VERSION "Version"

NS_ :

BS_:

BU_: LBMS CCU ZCUR_ZCUT Tester PLGM CCURT2 TMC ZCUF ZCUL ZCUR ZCUT EMS DCDC IPS NIDU DCU2 IDUR OBC OPC LPC CPC GCU DCU IPU BMS EOP DCDC2 SRS ECS SAS CBM RAS EPS RBM IBCS ICM IID IDC RCICP AMP WHUD IMR CD INU ADC IFC FAPA RRR RLR PAS PCS SCMR SCMRL SCMRR SCMRM SCMT MFS DRM IDU FCP RCP LBMSAD AVAS DLPFL FBLCM FLISD FLLCM FRLCM RLLCMA RLLCMB RRLCMA RRLCMB RLISD RRISD DLPML DLPMR PSDL PSDR HVSPRL HVSPRR TBOX2 TBOX EPB RFR SBM WCM ETC EVCC CCURT1 EDL

BO_ 1236 LBMS_DiagCode: 64 LBMS
 SG_ LBMS_DTCCode : 7|512@0+ (1,0) [0|0] ""  CCU

BO_ 998 CCU_VCU_5: 24 CCU
 SG_ VCU_LVBatFillSt_1 : 127|4@0+ (1,0) [0|15] ""  CCURT2,LBMS

BO_ 616 CCU_1: 64 CCU
 SG_ UMM_UsageModeSt : 26|3@0+ (1,0) [0|7] ""  CCURT2,TMC,ZCUF,ZCUL,ZCUR,ZCUT,EMS,DCDC,IPS,NIDU,DCU2,IDUR,OBC,OPC,LPC,CPC,GCU,DCU,IPU,BMS,EOP,DCDC2,SRS,ECS,SAS,CBM,RAS,EPS,RBM,IBCS,ICM,IID,IDC,RCICP,AMP,WHUD,IMR,CD,INU,ADC,IFC,FAPA,RRR,RLR,PAS,PCS,SCMR,SCMRL,SCMRR,SCMRM,SCMT,MFS,DRM,IDU,FCP,RCP,LBMSAD,AVAS,DLPFL,FBLCM,FLISD,FLLCM,FRLCM,RLLCMA,RLLCMB,RRLCMA,RRLCMB,RLISD,RRISD,DLPML,DLPMR,PLGM,PSDL,PSDR,HVSPRL,HVSPRR,LBMS,TBOX2,TBOX
 SG_ VMM_VehModeSt : 159|4@0+ (1,0) [0|15] ""  CCURT2,TMC,ZCUF,ZCUL,ZCUR,ZCUT,EMS,DCDC,IPS,NIDU,DCU2,IDUR,OBC,OPC,LPC,CPC,GCU,DCU,IPU,BMS,EOP,DCDC2,SRS,ECS,SAS,EPS,EPB,RBM,IBCS,ICM,IDC,RCICP,AMP,WHUD,IMR,ADC,IFC,FAPA,RRR,RLR,PAS,SCMR,SCMRL,SCMRR,SCMT,MFS,IDU,FCP,RCP,LBMSAD,AVAS,DLPFL,FBLCM,FLISD,FLLCM,FRLCM,RLLCMA,RLLCMB,RRLCMA,RRLCMB,RLISD,RRISD,DLPML,DLPMR,PLGM,PSDL,PSDR,HVSPRL,HVSPRR,LBMS,RFR,SBM,WCM,ETC,TBOX2,TBOX
 SG_ VMM_OTAModeSt : 167|2@0+ (1,0) [0|3] ""  CCURT2,ZCUF,ZCUL,ZCUR,ZCUT,EMS,DCDC,IPS,NIDU,DCU2,IDUR,OBC,OPC,LPC,CPC,GCU,DCU,IPU,BMS,EOP,DCDC2,SRS,ECS,EPS,EPB,RBM,IBCS,ICM,IDC,RCICP,AMP,WHUD,ADC,IFC,FAPA,RRR,RLR,PAS,SCMR,SCMRL,SCMRR,SCMT,MFS,RCP,LBMSAD,AVAS,DLPFL,FBLCM,FLISD,FLLCM,FRLCM,RLLCMA,RLLCMB,RRLCMA,RRLCMB,RLISD,RRISD,DLPML,DLPMR,PSDL,PSDR,HVSPRL,HVSPRR,LBMS,RFR,SBM,WCM,ETC,TBOX
 SG_ Time_Year : 343|8@0+ (1,2000) [2000|2255] "y"  CCURT2,TMC,ZCUF,ZCUL,ZCUR,ZCUT,EMS,DCDC,IPS,NIDU,DCU2,IDUR,OBC,OPC,LPC,CPC,GCU,DCU,IPU,BMS,EOP,EVCC,DCDC2,SRS,ECS,CBM,EPS,RBM,IBCS,RCICP,AMP,WHUD,IMR,INU,ADC,IFC,FAPA,RRR,RLR,PAS,PCS,SCMR,SCMRL,SCMRR,SCMT,MFS,DRM,RCP,LBMSAD,DLPFL,FBLCM,FLISD,FLLCM,FRLCM,RLLCMA,RLLCMB,RRLCMA,RRLCMB,RLISD,RRISD,DLPML,DLPMR,PLGM,PSDL,PSDR,HVSPRL,HVSPRR,LBMS
 SG_ Time_Month : 351|4@0+ (1,0) [1|12] "m"  CCURT2,TMC,ZCUF,ZCUL,ZCUR,ZCUT,EMS,DCDC,IPS,NIDU,DCU2,IDUR,OBC,OPC,LPC,CPC,GCU,DCU,IPU,BMS,EOP,EVCC,DCDC2,SRS,ECS,CBM,EPS,RBM,IBCS,RCICP,AMP,WHUD,IMR,INU,ADC,IFC,FAPA,RRR,RLR,PAS,PCS,SCMR,SCMRL,SCMRR,SCMT,MFS,DRM,RCP,LBMSAD,DLPFL,FBLCM,FLISD,FLLCM,FRLCM,RLLCMA,RLLCMB,RRLCMA,RRLCMB,RLISD,RRISD,DLPML,DLPMR,PLGM,PSDL,PSDR,HVSPRL,HVSPRR,LBMS
 SG_ Time_Day : 347|5@0+ (1,0) [1|31] "d"  CCURT2,TMC,ZCUF,ZCUL,ZCUR,ZCUT,EMS,DCDC,IPS,NIDU,DCU2,IDUR,OBC,OPC,LPC,CPC,GCU,DCU,IPU,BMS,EOP,EVCC,DCDC2,SRS,ECS,CBM,EPS,RBM,IBCS,RCICP,AMP,WHUD,IMR,INU,ADC,IFC,FAPA,RRR,RLR,PAS,PCS,SCMR,SCMRL,SCMRR,SCMT,MFS,DRM,RCP,LBMSAD,DLPFL,FBLCM,FLISD,FLLCM,FRLCM,RLLCMA,RLLCMB,RRLCMA,RRLCMB,RLISD,RRISD,DLPML,DLPMR,PLGM,PSDL,PSDR,HVSPRL,HVSPRR,LBMS
 SG_ Time_Hour : 358|5@0+ (1,0) [0|23] "h"  CCURT2,TMC,ZCUF,ZCUL,ZCUR,ZCUT,EMS,DCDC,IPS,NIDU,DCU2,IDUR,OBC,OPC,LPC,CPC,GCU,DCU,IPU,BMS,EOP,EVCC,DCDC2,SRS,ECS,CBM,EPS,RBM,IBCS,RCICP,AMP,WHUD,IMR,INU,ADC,IFC,FAPA,RRR,RLR,PAS,PCS,SCMR,SCMRL,SCMRR,SCMT,MFS,DRM,RCP,LBMSAD,DLPFL,FBLCM,FLISD,FLLCM,FRLCM,RLLCMA,RLLCMB,RRLCMA,RRLCMB,RLISD,RRISD,DLPML,DLPMR,PLGM,PSDL,PSDR,HVSPRL,HVSPRR,LBMS
 SG_ Time_Min : 353|6@0+ (1,0) [0|59] "min"  CCURT2,TMC,ZCUF,ZCUL,ZCUR,ZCUT,EMS,DCDC,IPS,NIDU,DCU2,IDUR,OBC,OPC,LPC,CPC,GCU,DCU,IPU,BMS,EOP,EVCC,DCDC2,SRS,ECS,CBM,EPS,RBM,IBCS,RCICP,AMP,WHUD,IMR,INU,ADC,IFC,FAPA,RRR,RLR,PAS,PCS,SCMR,SCMRL,SCMRR,SCMT,MFS,DRM,RCP,LBMSAD,DLPFL,FBLCM,FLISD,FLLCM,FRLCM,RLLCMA,RLLCMB,RRLCMA,RRLCMB,RLISD,RRISD,DLPML,DLPMR,PLGM,PSDL,PSDR,HVSPRL,HVSPRR,LBMS
 SG_ Time_Sec : 363|6@0+ (1,0) [0|59] "s"  CCURT2,TMC,ZCUF,ZCUL,ZCUR,ZCUT,EMS,DCDC,IPS,NIDU,DCU2,IDUR,OBC,OPC,LPC,CPC,GCU,DCU,IPU,BMS,EOP,EVCC,DCDC2,SRS,ECS,CBM,EPS,RBM,IBCS,RCICP,AMP,WHUD,IMR,INU,ADC,IFC,FAPA,RRR,RLR,PAS,PCS,SCMR,SCMRL,SCMRR,SCMT,MFS,DRM,RCP,LBMSAD,DLPFL,FBLCM,FLISD,FLLCM,FRLCM,RLLCMA,RLLCMB,RRLCMA,RRLCMB,RLISD,RRISD,DLPML,DLPMR,PLGM,PSDL,PSDR,HVSPRL,HVSPRR,LBMS

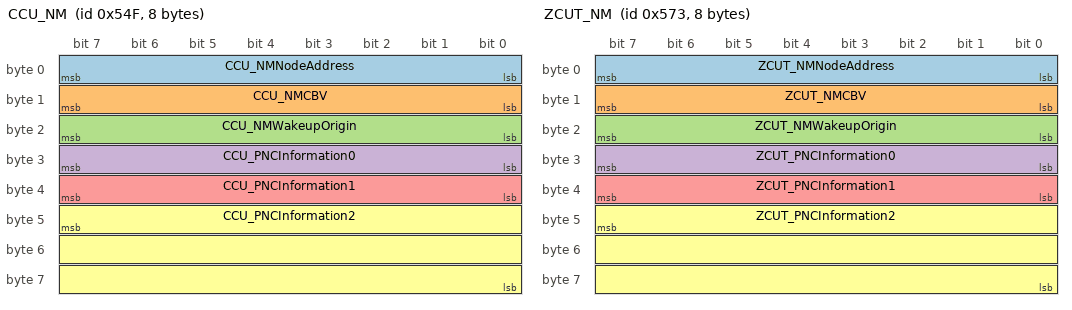
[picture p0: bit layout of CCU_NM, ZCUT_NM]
BO_ 1359 CCU_NM: 8 CCU
 SG_ CCU_NMNodeAddress : 7|8@0+ (1,0) [0|255] ""  CCURT1,TMC,ZCUF,ZCUL,ZCUR,ZCUT,EMS,IPS,NIDU,BMS,EVCC,ECS,CBM,RBM,IBCS,ICM,IID,IDC,AMP,ADC,FAPA,SCMR,SCMRL,SCMRR,SCMRM,SCMT,MFS,LBMSAD,PLGM,PSDL,PSDR,LBMS,TBOX
 SG_ CCU_NMCBV : 15|8@0+ (1,0) [0|0] ""  CCURT1,TMC,ZCUF,ZCUL,ZCUR,ZCUT,EMS,IPS,NIDU,BMS,EVCC,ECS,CBM,RBM,IBCS,ICM,IID,IDC,AMP,ADC,FAPA,SCMR,SCMRL,SCMRR,SCMRM,SCMT,MFS,LBMSAD,PLGM,PSDL,PSDR,LBMS,TBOX
 SG_ CCU_NMWakeupOrigin : 23|8@0+ (1,0) [0|255] ""  CCURT1,TMC,ZCUF,ZCUL,ZCUR,ZCUT,EMS,IPS,NIDU,BMS,EVCC,ECS,CBM,RBM,IBCS,ICM,IID,IDC,AMP,ADC,FAPA,SCMR,SCMRL,SCMRR,SCMRM,SCMT,MFS,LBMSAD,PLGM,PSDL,PSDR,LBMS,TBOX
 SG_ CCU_PNCInformation0 : 31|8@0+ (1,0) [0|255] ""  CCURT1,TMC,ZCUF,ZCUL,ZCUR,ZCUT,EMS,IPS,NIDU,BMS,EVCC,ECS,CBM,RBM,IBCS,ICM,IID,IDC,AMP,ADC,FAPA,SCMR,SCMRL,SCMRR,SCMRM,SCMT,MFS,LBMSAD,PLGM,PSDL,PSDR,LBMS,TBOX
 SG_ CCU_PNCInformation1 : 39|8@0+ (1,0) [0|255] ""  CCURT1,TMC,ZCUF,ZCUL,ZCUR,ZCUT,EMS,IPS,NIDU,BMS,EVCC,ECS,CBM,RBM,IBCS,ICM,IID,IDC,AMP,ADC,FAPA,SCMR,SCMRL,SCMRR,SCMRM,SCMT,MFS,LBMSAD,PLGM,PSDL,PSDR,LBMS,TBOX
 SG_ CCU_PNCInformation2 : 47|24@0+ (1,0) [0|0] ""  CCURT1,TMC,ZCUF,ZCUL,ZCUR,ZCUT,EMS,IPS,NIDU,BMS,EVCC,ECS,CBM,RBM,IBCS,ICM,IID,IDC,AMP,ADC,FAPA,SCMR,SCMRL,SCMRR,SCMRM,SCMT,MFS,LBMSAD,PLGM,PSDL,PSDR,LBMS,TBOX

BO_ 352 CCU_BCS_2_C: 64 CCU
 SG_ BCS_VehSpd : 31|13@0+ (0.05625,0) [0|240] "km/h"  TMC,ZCUF,ZCUL,ZCUR,ZCUT,EMS,DCDC,IPS,NIDU,DCU2,IDUR,OBC,OPC,LPC,CPC,GCU,DCU,IPU,BMS,EVCC,DCDC2,EDL,ICM,IID,IDC,AMP,IMR,INU,ADC,IFC,FAPA,RRR,RLR,PAS,PCS,SCMR,SCMRL,SCMRR,SCMRM,SCMT,MFS,DRM,IDU,RCP,LBMSAD,AVAS,DLPFL,FBLCM,FLISD,FLLCM,FRLCM,RLLCMA,RLLCMB,RRLCMA,RRLCMB,RLISD,RRISD,DLPML,DLPMR,PLGM,PSDL,PSDR,HVSPRL,HVSPRR,LBMS,TBOX2,TBOX
 SG_ BCS_VehSpdVD : 34|1@0+ (1,0) [0|1] ""  TMC,ZCUF,ZCUL,ZCUR,ZCUT,EMS,DCDC,IPS,NIDU,DCU2,IDUR,OBC,OPC,LPC,CPC,GCU,DCU,IPU,BMS,EVCC,DCDC2,ICM,IID,IDC,AMP,IMR,INU,ADC,IFC,FAPA,RRR,RLR,PAS,SCMR,SCMRL,SCMRR,SCMRM,SCMT,MFS,DRM,IDU,RCP,LBMSAD,AVAS,DLPFL,FBLCM,FLISD,FLLCM,FRLCM,RLLCMA,RLLCMB,RRLCMA,RRLCMB,RLISD,RRISD,DLPML,DLPMR,PLGM,PSDL,PSDR,HVSPRL,HVSPRR,LBMS,TBOX

BO_ 884 CCU_GwMsg_3: 64 CCU
 SG_ CCU_GwMsg_3_CRC : 7|16@0+ (1,0) [0|65535] ""  CBM,LBMS
 SG_ CCU_GwMsg_3_Counter : 23|8@0+ (1,0) [0|255] ""  CBM,LBMS
 SG_ LCK_FrontLeftDoorHandlePosition : 31|8@0+ (1,0) [0|255] ""  CBM,LBMS
 SG_ LCK_FrontLeftDoorLockAction : 41|2@0+ (1,0) [0|2] ""  CBM,LBMS
 SG_ LCK_FrontLeftDoorHandleAction : 43|2@0+ (1,0) [0|2] ""  CBM,LBMS
 SG_ LCK_FrontLeftPowerDoorAction : 45|2@0+ (1,0) [0|2] ""  CBM,LBMS
 SG_ LCK_FrontRightDoorHandlePosition : 39|8@0+ (1,0) [0|255] ""  CBM,LBMS
 SG_ LCK_FrontRightDoorLockAction : 47|2@0+ (1,0) [0|2] ""  CBM,LBMS
 SG_ LCK_FrontRightDoorHandleAction : 53|2@0+ (1,0) [0|2] ""  CBM,LBMS
 SG_ LCK_FrontRightPowerDoorAction : 55|2@0+ (1,0) [0|2] ""  CBM,LBMS
 SG_ IPDS_BAT1PowerSt : 48|1@0+ (1,0) [0|1] ""  LBMSAD,LBMS
 SG_ IPDS_BAT2PowerSt : 49|1@0+ (1,0) [0|1] ""  LBMSAD,LBMS
 SG_ IPDS_DCDC2PowerSt : 50|1@0+ (1,0) [0|1] ""  LBMSAD,LBMS
 SG_ IPDS_GridIsoPowerSt : 51|1@0+ (1,0) [0|1] ""  LBMSAD,LBMS
 SG_ IPS_DCDCDiagErrCode : 63|8@0+ (1,0) [0|255] ""  LBMSAD,LBMS
 SG_ IPS_DCDCCurrLvAct : 71|9@0+ (1,0) [0|511] "A"  LBMSAD,LBMS

BO_ 514 CCU_GwMsg_2: 16 CCU
 SG_ CCU_GwMsg_2_CRC : 7|16@0+ (1,0) [0|65535] ""  ZCUR,ZCUT,LBMSAD,LBMS
 SG_ CCU_GwMsg_2_Counter : 23|8@0+ (1,0) [0|255] ""  ZCUR,ZCUT,LBMSAD,LBMS
 SG_ SRS_CrashOutputSt : 29|8@0+ (1,0) [0|160] ""  LBMSAD,LBMS
 SG_ BMS_HVBattSt : 109|4@0+ (1,0) [0|15] ""  LBMSAD,LBMS

BO_ 909 CCU_ZCU_1: 64 CCU
 SG_ LCK_FrontLeftDoorLockSt : 47|1@0+ (1,0) [0|1] ""  ZCUR,CBM,ICM,IDC,ADC,IFC,FAPA,RRR,RLR,LBMS
 SG_ LCK_FrontRightDoorLockSt : 46|1@0+ (1,0) [0|1] ""  CBM,ICM,IDC,ADC,IFC,FAPA,RRR,RLR,LBMS
 SG_ LCK_RearLeftDoorLockSt : 45|1@0+ (1,0) [0|1] ""  ZCUL,ZCUR,ECS,CBM,ICM,IDC,ADC,IFC,FAPA,RRR,RLR,LBMS
 SG_ LCK_RearRightDoorLockSt : 44|1@0+ (1,0) [0|1] ""  ZCUL,ZCUR,ECS,CBM,ICM,IDC,ADC,IFC,FAPA,RRR,RLR,LBMS
 SG_ LCK_RearLeftChildSaftyLockSt : 43|1@0+ (1,0) [0|1] ""  ZCUL,ZCUR,CBM,ICM,IDC,ADC,IFC,FAPA,RRR,RLR,LBMS
 SG_ LCK_RearRightChildSaftyLockSt : 42|1@0+ (1,0) [0|1] ""  ZCUL,ZCUR,CBM,ICM,IDC,ADC,IFC,FAPA,RRR,RLR,LBMS
 SG_ IPS_DCDCVoltLvAct : 301|10@0+ (0.1,0) [0|102.3] "V"  LBMSAD,LBMS
 SG_ BMS_ThermalRunawayErr : 208|1@0+ (1,0) [0|1] ""  LBMSAD,LBMS
 SG_ IPS_DCDCModeSt : 449|3@0+ (1,0) [0|7] ""  ZCUR,ECS,IDU,LBMSAD,LBMS

BO_ 792 CCU_ZCUT_2: 64 CCU
 SG_ ZCUT_2_CRC : 7|16@0+ (1,0) [0|65535] ""  LBMS
 SG_ ZCUT_2_Counter : 23|8@0+ (1,0) [0|255] ""  LBMS
 SG_ LCK_RearLeftDoorLockAction : 141|2@0+ (1,0) [0|2] ""  LBMS
 SG_ LCK_RearLeftDoorHandleAction : 139|2@0+ (1,0) [0|2] ""  LBMS
 SG_ LCK_RearLeftPowerDoorAction : 137|2@0+ (1,0) [0|2] ""  LBMS
 SG_ LCK_RearLeftDoorHandlePosition : 151|8@0+ (1,0) [0|255] ""  LBMS
 SG_ LCK_RearLeftChildSaftyLockAction : 158|2@0+ (1,0) [0|2] ""  LBMS
 SG_ LCK_RearRightDoorHandlePosition : 167|8@0+ (1,0) [0|255] ""  LBMS
 SG_ LCK_RearRightDoorHandleAction : 175|2@0+ (1,0) [0|2] ""  LBMS
 SG_ LCK_RearRightPowerDoorAction : 173|2@0+ (1,0) [0|2] ""  LBMS
 SG_ LCK_RearRightChildSaftyLockAction : 171|2@0+ (1,0) [0|2] ""  LBMS
 SG_ LCK_RearRightDoorLockAction : 203|2@0+ (1,0) [0|3] ""  LBMS

BO_ 1395 ZCUT_NM: 8 ZCUR_ZCUT
 SG_ ZCUT_NMNodeAddress : 7|8@0+ (1,0) [0|255] ""  CCU,SCMR,SCMRL,SCMRR,SCMRM,SCMT,PLGM,LBMS
 SG_ ZCUT_NMCBV : 15|8@0+ (1,0) [0|0] ""  CCU,SCMR,SCMRL,SCMRR,SCMRM,SCMT,PLGM,LBMS
 SG_ ZCUT_NMWakeupOrigin : 23|8@0+ (1,0) [0|255] ""  CCU,SCMR,SCMRL,SCMRR,SCMRM,SCMT,PLGM,LBMS
 SG_ ZCUT_PNCInformation0 : 31|8@0+ (1,0) [0|255] ""  CCU,SCMR,SCMRL,SCMRR,SCMRM,SCMT,PLGM,LBMS
 SG_ ZCUT_PNCInformation1 : 39|8@0+ (1,0) [0|255] ""  CCU,SCMR,SCMRL,SCMRR,SCMRM,SCMT,PLGM,LBMS
 SG_ ZCUT_PNCInformation2 : 47|24@0+ (1,0) [0|0] ""  CCU,SCMR,SCMRL,SCMRR,SCMRM,SCMT,PLGM,LBMS

BO_ 1697 LBMS_Diag_Rx: 64 Tester
 SG_ LBMS_Diag_Request : 7|512@0+ (1,0) [0|0] ""  LBMS

BO_ 1705 LBMS_Diag_Tx: 64 LBMS
 SG_ LBMS_Diag_Response : 7|512@0+ (1,0) [0|0] ""  Tester

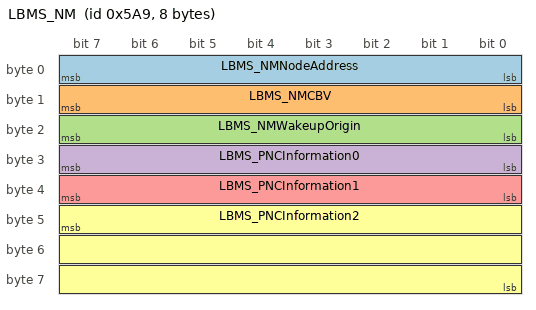
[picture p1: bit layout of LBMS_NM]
BO_ 1449 LBMS_NM: 8 LBMS
 SG_ LBMS_NMNodeAddress : 7|8@0+ (1,0) [0|255] ""  CCU,ZCUT,PLGM
 SG_ LBMS_NMCBV : 15|8@0+ (1,0) [0|0] ""  CCU,ZCUT,PLGM
 SG_ LBMS_NMWakeupOrigin : 23|8@0+ (1,0) [0|255] ""  CCU,ZCUT,PLGM
 SG_ LBMS_PNCInformation0 : 31|8@0+ (1,0) [0|255] ""  CCU,ZCUT,PLGM
 SG_ LBMS_PNCInformation1 : 39|8@0+ (1,0) [0|255] ""  CCU,ZCUT,PLGM
 SG_ LBMS_PNCInformation2 : 47|24@0+ (1,0) [0|0] ""  CCU,ZCUT,PLGM

BO_ 793 LBMS_1: 64 LBMS
 SG_ LBMS_1_CRC : 7|16@0+ (1,0) [0|65535] ""  CCU,CCURT1,CCURT2
 SG_ LBMS_1_Counter : 23|8@0+ (1,0) [0|255] ""  CCU,CCURT1,CCURT2
 SG_ LBMS_UnsfLoadPackVoltVD : 110|1@0+ (1,0) [0|1] ""  CCU,CCURT1,CCURT2
 SG_ LBMS_UnsfLoadPackVolt : 73|11@0+ (0.01,0) [0|20.47] "V"  CCU,CCURT1,CCURT2
 SG_ LBMS_SfLoadPackVoltVD : 111|1@0+ (1,0) [0|1] ""  CCU,CCURT1,CCURT2
 SG_ LBMS_SfLoadPackVolt : 94|11@0+ (0.01,0) [0|20.47] "V"  CCU,CCURT1,CCURT2
 SG_ LBMS_UnsfLoadCurrentRange : 97|2@0+ (1,0) [0|3] ""  CCU,CCURT1,CCURT2
 SG_ LBMS_SfLoadCurrentRange : 99|2@0+ (1,0) [0|3] ""  CCU,CCURT1,CCURT2
 SG_ LBMS_SOFVD : 28|1@0+ (1,0) [0|1] ""  CCU,CCURT1,CCURT2
 SG_ LBMS_SOFEN : 30|2@0+ (1,0) [0|3] ""  CCU,CCURT1,CCURT2
 SG_ LBMS_SOFInhibitSt : 47|8@0+ (1,0) [0|255] ""  CCU,CCURT1,CCURT2
 SG_ LBMS_ChargReq : 26|3@0+ (1,0) [0|7] ""  CCU,CCURT1,CCURT2
 SG_ LBMS_SOCVD : 27|1@0+ (1,0) [0|1] ""  CCU,CCURT1,CCURT2
 SG_ LBMS_SOC : 39|8@0+ (1,0) [0|100] "%"  CCU,CCURT1,CCURT2
 SG_ LBMS_PackVoltVD : 31|1@0+ (1,0) [0|1] ""  CCU,CCURT1,CCURT2
 SG_ LBMS_PackVolt : 55|11@0+ (0.01,0) [0|20.47] "V"  CCU,CCURT1,CCURT2
 SG_ LBMS_AlrmDispSt : 60|3@0+ (1,0) [0|7] ""  CCU,CCURT1,CCURT2
 SG_ LBMS_CurrentRange : 57|2@0+ (1,0) [0|3] ""  CCU,CCURT1,CCURT2
 SG_ LBMS_RefChargReq : 75|2@0+ (1,0) [0|3] ""  CCU,CCURT1,CCURT2
 SG_ LBMS_ThermalRunawayErr : 77|2@0+ (1,0) [0|3] ""  CCU,CCURT1,CCURT2
 SG_ LBMS_ChrgVoltReq : 71|10@0+ (0.01,9) [9|19.23] "V"  CCU,CCURT1,CCURT2
 SG_ LBMS_IPDS_BAT1PowerReq : 107|1@0+ (1,0) [0|1] ""  CCU,CCURT1,CCURT2
 SG_ LBMS_IPDS_BAT2PowerReq : 108|1@0+ (1,0) [0|1] ""  CCU,CCURT1,CCURT2
 SG_ LBMS_IPDS_GridlsoPowerReq : 109|1@0+ (1,0) [0|1] ""  CCU,CCURT1,CCURT2
 SG_ LBMS_FaultSt_SOCLow : 106|2@0+ (1,0) [0|3] ""  CCU,CCURT1,CCURT2
 SG_ LBMS_FaultNum : 119|8@0+ (1,0) [0|255] ""  CCU,CCURT1,CCURT2
 SG_ LBMS_FaultCode : 127|8@0+ (1,0) [0|255] ""  CCU,CCURT1,CCURT2
 SG_ LBMS_DisconnectSt : 191|3@0+ (1,0) [0|7] ""  CCU,CCURT1,CCURT2

BO_ 973 LBMS_2: 64 LBMS
 SG_ LBMS_SOH : 7|8@0+ (1,0) [0|255] ""  CCU,CCURT1,CCURT2
 SG_ LBMS_SOHVD : 25|1@0+ (1,0) [0|1] ""  CCU,CCURT1,CCURT2
 SG_ LBMS_Current : 15|22@0+ (0.001,-1500) [-1500|2694.303] "A"  CCU,CCURT1,CCURT2
 SG_ LBMS_ChrgCurrentReq : 39|12@0+ (0.1,0) [0|409.5] "A"  CCU,CCURT1,CCURT2
 SG_ LBMS_CellTotVolt : 43|11@0+ (0.01,0) [0|20.47] "V"  CCU,CCURT1,CCURT2
 SG_ LBMS_CellTotVoltVD : 24|1@0+ (1,0) [0|1] ""  CCU,CCURT1,CCURT2
 SG_ LBMS_ChargReqEn : 48|1@0+ (1,0) [0|1] ""  CCU,CCURT1,CCURT2
 SG_ LBMS_WorkSt : 63|4@0+ (1,0) [0|15] ""  CCU,CCURT1,CCURT2
 SG_ LBMS_MOSSt : 71|3@0+ (1,0) [0|7] ""  CCU,CCURT1,CCURT2
 SG_ LBMS_WakeupSource : 59|4@0+ (1,0) [0|15] ""  CCU,CCURT1,CCURT2
 SG_ LBMS_HardWireSt : 68|2@0+ (1,0) [0|3] ""  CCU,CCURT1,CCURT2
 SG_ LBMS_QC : 471|14@0+ (1,-16000) [-16000|383] "mA"  CCU,CCURT1,CCURT2
 SG_ LBMS_WireHarnConSt : 84|3@0+ (1,0) [0|7] ""  CCU,CCURT1,CCURT2
 SG_ LBMS_SOCCaliMode : 66|3@0+ (1,0) [0|7] ""  CCU,CCURT1,CCURT2
 SG_ LBMS_ChrgCurrentLimt1 : 95|12@0+ (0.1,0) [0|409.5] "A"  CCU,CCURT1,CCURT2
 SG_ LBMS_ChrgCurrentLimt2 : 99|12@0+ (0.1,0) [0|409.5] "A"  CCU,CCURT1,CCURT2
 SG_ LBMS_ChrgCurrentLimt1VD : 81|1@0+ (1,0) [0|1] ""  CCU,CCURT1,CCURT2
 SG_ LBMS_ChrgCurrentLimt2VD : 80|1@0+ (1,0) [0|1] ""  CCU,CCURT1,CCURT2
 SG_ LBMS_Cell1Volt : 119|13@0+ (0.001,0) [0|8.191] "V"  CCU,CCURT1,CCURT2
 SG_ LBMS_Cell1VoltVD : 122|1@0+ (1,0) [0|1] ""  CCU,CCURT1,CCURT2
 SG_ LBMS_Cell2Volt : 135|13@0+ (0.001,0) [0|8.191] "V"  CCU,CCURT1,CCURT2
 SG_ LBMS_Cell2VoltVD : 138|1@0+ (1,0) [0|1] ""  CCU,CCURT1,CCURT2
 SG_ LBMS_Cell3Volt : 151|13@0+ (0.001,0) [0|8.191] "V"  CCU,CCURT1,CCURT2
 SG_ LBMS_Cell3VoltVD : 154|1@0+ (1,0) [0|1] ""  CCU,CCURT1,CCURT2
 SG_ LBMS_Cell4Volt : 167|13@0+ (0.001,0) [0|8.191] "V"  CCU,CCURT1,CCURT2
 SG_ LBMS_Cell4VoltVD : 170|1@0+ (1,0) [0|1] ""  CCU,CCURT1,CCURT2
 SG_ LBMS_CellMaxVolt : 183|13@0+ (0.001,0) [0|8.191] "V"  CCU,CCURT1,CCURT2
 SG_ LBMS_CellMinVolt : 199|13@0+ (0.001,0) [0|8.191] "V"  CCU,CCURT1,CCURT2
 SG_ LBMS_Cell1BalanceSt : 121|2@0+ (1,0) [0|3] ""  CCU,CCURT1,CCURT2
 SG_ LBMS_Cell2BalanceSt : 137|2@0+ (1,0) [0|3] ""  CCU,CCURT1,CCURT2
 SG_ LBMS_Cell3BalanceSt : 153|2@0+ (1,0) [0|3] ""  CCU,CCURT1,CCURT2
 SG_ LBMS_Cell4BalanceSt : 169|2@0+ (1,0) [0|3] ""  CCU,CCURT1,CCURT2
 SG_ LBMS_CellTemp1 : 215|8@0+ (1,-40) [-40|215] "℃"  CCU,CCURT1,CCURT2
 SG_ LBMS_CellTemp2 : 223|8@0+ (1,-40) [-40|215] "℃"  CCU,CCURT1,CCURT2
 SG_ LBMS_CellTemp3 : 231|8@0+ (1,-40) [-40|215] "℃"  CCU,CCURT1,CCURT2
 SG_ LBMS_CellTemp1VD : 186|1@0+ (1,0) [0|1] ""  CCU,CCURT1,CCURT2
 SG_ LBMS_CellTemp2VD : 185|1@0+ (1,0) [0|1] ""  CCU,CCURT1,CCURT2
 SG_ LBMS_CellTemp3VD : 184|1@0+ (1,0) [0|1] ""  CCU,CCURT1,CCURT2
 SG_ LBMS_McuTemp : 239|8@0+ (1,-40) [-40|215] "℃"  CCU,CCURT1,CCURT2
 SG_ LBMS_McuTempVD : 201|1@0+ (1,0) [0|1] ""  CCU,CCURT1,CCURT2
 SG_ LBMS_MosTemp1 : 247|8@0+ (1,-40) [-40|215] "℃"  CCU,CCURT1,CCURT2
 SG_ LBMS_MosTemp1VD : 200|1@0+ (1,0) [0|1] ""  CCU,CCURT1,CCURT2
 SG_ LBMS_CurrentVD : 202|1@0+ (1,0) [0|1] ""  CCU,CCURT1,CCURT2
 SG_ LBMS_MosTemp2 : 255|8@0+ (1,-40) [-40|215] "℃"  CCU,CCURT1,CCURT2
 SG_ LBMS_MosTemp2VD : 287|1@0+ (1,0) [0|1] ""  CCU,CCURT1,CCURT2
 SG_ LBMS_ShuntTemp : 263|8@0+ (1,-40) [-40|215] "℃"  CCU,CCURT1,CCURT2
 SG_ LBMS_ShuntTempVD : 286|1@0+ (1,0) [0|1] ""  CCU,CCURT1,CCURT2
 SG_ LBMS_BalanTemp1 : 271|8@0+ (1,-40) [-40|215] "℃"  CCU,CCURT1,CCURT2
 SG_ LBMS_BalanTemp1VD : 285|1@0+ (1,0) [0|1] ""  CCU,CCURT1,CCURT2
 SG_ LBMS_BalanTemp2 : 279|8@0+ (1,-40) [-40|215] "℃"  CCU,CCURT1,CCURT2
 SG_ LBMS_BalanTemp2VD : 284|1@0+ (1,0) [0|1] ""  CCU,CCURT1,CCURT2
 SG_ LBMS_FaultSt_OVB : 295|2@0+ (1,0) [0|3] ""  CCU,CCURT1,CCURT2
 SG_ LBMS_FaultSt_OVC : 283|3@0+ (1,0) [0|7] ""  CCU,CCURT1,CCURT2
 SG_ LBMS_FaultSt_CVD : 280|1@0+ (1,0) [0|1] ""  CCU,CCURT1,CCURT2
 SG_ LBMS_FaultSt_LVB : 293|3@0+ (1,0) [0|7] ""  CCU,CCURT1,CCURT2
 SG_ LBMS_FaultSt_LVC : 290|3@0+ (1,0) [0|7] ""  CCU,CCURT1,CCURT2
 SG_ LBMS_FaultSt_OTB : 303|3@0+ (1,0) [0|7] ""  CCU,CCURT1,CCURT2
 SG_ LBMS_FaultSt_OTMC : 300|2@0+ (1,0) [0|3] ""  CCU,CCURT1,CCURT2
 SG_ LBMS_FaultSt_OTMO : 298|2@0+ (1,0) [0|3] ""  CCU,CCURT1,CCURT2
 SG_ LBMS_FaultSt_OTS : 311|2@0+ (1,0) [0|3] ""  CCU,CCURT1,CCURT2
 SG_ LBMS_FaultSt_OTCB : 296|1@0+ (1,0) [0|1] ""  CCU,CCURT1,CCURT2
 SG_ LBMS_FaultSt_CTD : 309|1@0+ (1,0) [0|1] ""  CCU,CCURT1,CCURT2
 SG_ LBMS_FaultSt_LT : 308|2@0+ (1,0) [0|3] ""  CCU,CCURT1,CCURT2
 SG_ LBMS_FaultSt_ChgOC : 319|2@0+ (1,0) [0|3] ""  CCU,CCURT1,CCURT2
 SG_ LBMS_FaultSt_DsgOC : 306|3@0+ (1,0) [0|7] ""  CCU,CCURT1,CCURT2
 SG_ LBMS_FaultSt_Hard_CellVolCol : 317|2@0+ (1,0) [0|3] ""  CCU,CCURT1,CCURT2
 SG_ LBMS_FaultSt_Hard_TempColBat : 315|2@0+ (1,0) [0|3] ""  CCU,CCURT1,CCURT2
 SG_ LBMS_FaultSt_Hard_TemColMOS : 313|2@0+ (1,0) [0|3] ""  CCU,CCURT1,CCURT2
 SG_ LBMS_FaultSt_Hard_TemColMCU : 327|2@0+ (1,0) [0|3] ""  CCU,CCURT1,CCURT2
 SG_ LBMS_FaultSt_Hard_Shunt : 325|2@0+ (1,0) [0|3] ""  CCU,CCURT1,CCURT2
 SG_ LBMS_FaultSt_Hard_ChgMOS : 323|2@0+ (1,0) [0|3] ""  CCU,CCURT1,CCURT2
 SG_ LBMS_FaultSt_Hard_DsgMOS : 343|3@0+ (1,0) [0|7] ""  CCU,CCURT1,CCURT2
 SG_ LBMS_FaultSt_Hard_AFE : 335|4@0+ (1,0) [0|15] ""  CCU,CCURT1,CCURT2
 SG_ LBMS_FaultSt_Hard_MCU : 331|4@0+ (1,0) [0|15] ""  CCU,CCURT1,CCURT2
 SG_ LBMS_FaultSt_Hard_SBC : 340|3@0+ (1,0) [0|7] ""  CCU,CCURT1,CCURT2
 SG_ LBMS_FaultSt_Hard_DCDC : 321|2@0+ (1,0) [0|3] ""  CCU,CCURT1,CCURT2
 SG_ LBMS_FaultSt_CANBusOff : 337|1@0+ (1,0) [0|1] ""  CCU,CCURT1,CCURT2
 SG_ LBMS_FaultSt_CANTimeOut : 336|1@0+ (1,0) [0|1] ""  CCU,CCURT1,CCURT2
 SG_ LBMS_FaultSt_CANCrcErr : 405|1@0+ (1,0) [0|1] ""  CCU,CCURT1,CCURT2
 SG_ LBMS_CumuChargeAh : 351|24@0+ (0.1,0) [0|1677721.5] "Ah"  CCU,CCURT1,CCURT2
 SG_ LBMS_CumuDischargeAh : 375|24@0+ (0.1,0) [0|1677721.5] "Ah"  CCU,CCURT1,CCURT2
 SG_ LBMS_LastFullChargeAh : 399|10@0+ (1,0) [0|1023] "Ah"  CCU,CCURT1,CCURT2
 SG_ LBMS_HisLockPackSt : 404|1@0+ (1,0) [0|1] ""  CCU,CCURT1,CCURT2
 SG_ LBMS_CurentLockPackSt : 403|1@0+ (1,0) [0|1] ""  CCU,CCURT1,CCURT2
 SG_ LBMS_ExternalCharging : 402|1@0+ (1,0) [0|1] ""  CCU,CCURT1,CCURT2
 SG_ LBMS_LastFullChargeTime : 415|8@0+ (1,0) [0|255] "h"  CCU,CCURT1,CCURT2
 SG_ LBMS_StaticTime : 423|13@0+ (1,0) [0|8191] "day"  CCU,CCURT1,CCURT2
 SG_ LBMS_AppVersionFirst : 439|4@0+ (1,0) [0|15] ""  CCU,CCURT1,CCURT2
 SG_ LBMS_AppVersionSecond : 435|4@0+ (1,0) [0|15] ""  CCU,CCURT1,CCURT2
 SG_ LBMS_AppVersionThird : 447|4@0+ (1,0) [0|15] ""  CCU,CCURT1,CCURT2
 SG_ LBMS_BootVersionFirst : 443|4@0+ (1,0) [0|15] ""  CCU,CCURT1,CCURT2
 SG_ LBMS_BootVersionSecond : 455|4@0+ (1,0) [0|15] ""  CCU,CCURT1,CCURT2
 SG_ LBMS_HwVersion : 451|4@0+ (1,0) [0|15] ""  CCU,CCURT1,CCURT2
 SG_ LBMS_Supplier : 426|3@0+ (1,0) [0|7] ""  CCU,CCURT1,CCURT2
 SG_ LBMS_UpackRvsVolt : 473|12@0+ (0.01,-20) [-20|20] "V"  CCU,CCURT1,CCURT2
 SG_ LBMS_UpackRvsVoltVD : 401|1@0+ (1,0) [0|1] ""  CCU,CCURT1,CCURT2

CM_ SG_ 1236 LBMS_DTCCode "LBMS DTC code and status";
CM_ SG_ 998 VCU_LVBatFillSt_1 "Low voltage battery charge fill state";
CM_ SG_ 616 UMM_UsageModeSt "Usage mode state";
CM_ SG_ 616 VMM_VehModeSt "Vehicle mode state";
CM_ SG_ 616 VMM_OTAModeSt "OTA Mode state";
CM_ SG_ 616 Time_Year "Year number";
CM_ SG_ 616 Time_Month "Month number";
CM_ SG_ 616 Time_Day "Day number";
CM_ SG_ 616 Time_Hour "Hour number";
CM_ SG_ 616 Time_Min "Minute number";
CM_ SG_ 616 Time_Sec "Second number";
CM_ SG_ 1359 CCU_NMNodeAddress "CCU node address";
CM_ SG_ 1359 CCU_NMCBV "CCU Network management control bit vector";
CM_ SG_ 1359 CCU_NMWakeupOrigin "Origin of the wake up";
CM_ SG_ 1359 CCU_PNCInformation0 "PNC Information";
CM_ SG_ 1359 CCU_PNCInformation1 "PNC Information";
CM_ SG_ 1359 CCU_PNCInformation2 "PNC Information";
CM_ SG_ 352 BCS_VehSpd "Vehicle speed";
CM_ SG_ 352 BCS_VehSpdVD "Quality/fault information to vehicle speed";
CM_ SG_ 884 CCU_GwMsg_3_CRC "E2E Profile 5 CRC";
CM_ SG_ 884 CCU_GwMsg_3_Counter "E2E Profile 5 Counter";
CM_ SG_ 884 LCK_FrontLeftDoorHandlePosition "FrontLeftDoorHandlePosition";
CM_ SG_ 884 LCK_FrontLeftDoorLockAction "FrontLeftDoorLockAction";
CM_ SG_ 884 LCK_FrontLeftDoorHandleAction "FrontLeftDoorHandleAction";
CM_ SG_ 884 LCK_FrontLeftPowerDoorAction "FrontLeftPowerDoorAction";
CM_ SG_ 884 LCK_FrontRightDoorHandlePosition "FrontRightDoorHandlePosition";
CM_ SG_ 884 LCK_FrontRightDoorLockAction "FrontRightDoorLockAction";
CM_ SG_ 884 LCK_FrontRightDoorHandleAction "FrontRightDoorHandleAction";
CM_ SG_ 884 LCK_FrontRightPowerDoorAction "FrontRightPowerDoorAction";
CM_ SG_ 884 IPDS_BAT1PowerSt "BAT1 power  state";
CM_ SG_ 884 IPDS_BAT2PowerSt "BAT2 power  state";
CM_ SG_ 884 IPDS_DCDC2PowerSt "DCDC2 power  state";
CM_ SG_ 884 IPDS_GridIsoPowerSt "Grid Isolation Power State";
CM_ SG_ 884 IPS_DCDCDiagErrCode "DCDC diagnostics error code";
CM_ SG_ 884 IPS_DCDCCurrLvAct "LV Current? of DCDC";
CM_ SG_ 514 CCU_GwMsg_2_CRC "E2E Profile 5 CRC";
CM_ SG_ 514 CCU_GwMsg_2_Counter "E2E Profile 5 Counter";
CM_ SG_ 514 SRS_CrashOutputSt "To inform there's crash event happened in last 2 seconds.After 2 seconds, the signal will turn to 0(crash here means any one of the 5 status defined below)";
CM_ SG_ 514 BMS_HVBattSt "working state of HV battery system";
CM_ SG_ 909 LCK_FrontLeftDoorLockSt "FrontLeftDoorLockSt";
CM_ SG_ 909 LCK_FrontRightDoorLockSt "FrontRightDoorLockSt";
CM_ SG_ 909 LCK_RearLeftDoorLockSt "RearLeftDoorLockSt";
CM_ SG_ 909 LCK_RearRightDoorLockSt "RearRightDoorLockSt";
CM_ SG_ 909 LCK_RearLeftChildSaftyLockSt "RearLeftChildSaftyLockSt";
CM_ SG_ 909 LCK_RearRightChildSaftyLockSt "RearRightChildSaftyLockSt";
CM_ SG_ 909 IPS_DCDCVoltLvAct "actual LV voltage at DCDC";
CM_ SG_ 909 BMS_ThermalRunawayErr "thermal runaway error alarm";
CM_ SG_ 909 IPS_DCDCModeSt "mode status of DCDC";
CM_ SG_ 792 ZCUT_2_CRC "E2E Profile 5 CRC";
CM_ SG_ 792 ZCUT_2_Counter "E2E Profile 5 Counter";
CM_ SG_ 792 LCK_RearLeftDoorLockAction "RearLeftDoorLockAction";
CM_ SG_ 792 LCK_RearLeftDoorHandleAction "RearLeftDoorHandleAction";
CM_ SG_ 792 LCK_RearLeftPowerDoorAction "RearLeftPowerDoorAction";
CM_ SG_ 792 LCK_RearLeftDoorHandlePosition "RearLeftDoorHandlePosition";
CM_ SG_ 792 LCK_RearLeftChildSaftyLockAction "RearLeftChildSaftyLockAction";
CM_ SG_ 792 LCK_RearRightDoorHandlePosition "RearRightDoorHandlePosition";
CM_ SG_ 792 LCK_RearRightDoorHandleAction "RearRightDoorHandleAction";
CM_ SG_ 792 LCK_RearRightPowerDoorAction "RearRightPowerDoorAction";
CM_ SG_ 792 LCK_RearRightChildSaftyLockAction "RearRightChildSaftyLockAction";
CM_ SG_ 792 LCK_RearRightDoorLockAction "RearRightDoorLockAction";
CM_ SG_ 1395 ZCUT_NMNodeAddress "ZCUT node address";
CM_ SG_ 1395 ZCUT_NMCBV "ZCUT Network management control bit vector";
CM_ SG_ 1395 ZCUT_NMWakeupOrigin "Origin of the wake up";
CM_ SG_ 1395 ZCUT_PNCInformation0 "PNC Information";
CM_ SG_ 1395 ZCUT_PNCInformation1 "PNC Information";
CM_ SG_ 1395 ZCUT_PNCInformation2 "PNC Information";
CM_ SG_ 1697 LBMS_Diag_Request "LBMS diagnostic request";
CM_ SG_ 1705 LBMS_Diag_Response "LBMS diagnostic response";
CM_ SG_ 1449 LBMS_NMNodeAddress "LBMS node address";
CM_ SG_ 1449 LBMS_NMCBV "LBMS Network management control bit vector";
CM_ SG_ 1449 LBMS_NMWakeupOrigin "Origin of the wake up";
CM_ SG_ 1449 LBMS_PNCInformation0 "PNC Information";
CM_ SG_ 1449 LBMS_PNCInformation1 "PNC Information";
CM_ SG_ 1449 LBMS_PNCInformation2 "PNC Information";
CM_ SG_ 793 LBMS_1_CRC "E2E Profile 5 CRC";
CM_ SG_ 793 LBMS_1_Counter "E2E Profile 5 Counter";
CM_ SG_ 793 LBMS_UnsfLoadPackVoltVD "Battery  pack voltage validity of unsafe load";
CM_ SG_ 793 LBMS_UnsfLoadPackVolt "Battery  pack voltage of unsafe load ";
CM_ SG_ 793 LBMS_SfLoadPackVoltVD "Battery  pack voltage validity of safe load";
CM_ SG_ 793 LBMS_SfLoadPackVolt "Battery  pack voltage of safe load ";
CM_ SG_ 793 LBMS_UnsfLoadCurrentRange "Battery current  range of unsafe load";
CM_ SG_ 793 LBMS_SfLoadCurrentRange "Battery current  range of safe load";
CM_ SG_ 793 LBMS_SOFVD "LBMS Validity of SOF";
CM_ SG_ 793 LBMS_SOFEN "LBMS  State of Function Enable";
CM_ SG_ 793 LBMS_SOFInhibitSt "Inhibited status of SOF ";
CM_ SG_ 793 LBMS_ChargReq "LBMS Battery Charge Request";
CM_ SG_ 793 LBMS_SOCVD "LBMS Validity of SOC";
CM_ SG_ 793 LBMS_SOC "LBMS  State of Charge";
CM_ SG_ 793 LBMS_PackVoltVD "LBMS Battery voltage of pack  Valid";
CM_ SG_ 793 LBMS_PackVolt "LBMS Battery voltage of pack";
CM_ SG_ 793 LBMS_AlrmDispSt "Alarm  State for Display of Low voltage battery Management System";
CM_ SG_ 793 LBMS_CurrentRange "LBMS Battery Current  Range";
CM_ SG_ 793 LBMS_RefChargReq "Battery fully charged sign Dynamic calibration";
CM_ SG_ 793 LBMS_ThermalRunawayErr "Lithium electrothermal runaway state signal";
CM_ SG_ 793 LBMS_ChrgVoltReq "Battery Charging Volt Request";
CM_ SG_ 793 LBMS_IPDS_BAT1PowerReq "LBMS Control Battery1 power Request";
CM_ SG_ 793 LBMS_IPDS_BAT2PowerReq "LBMS Control Battery2 power Request";
CM_ SG_ 793 LBMS_IPDS_GridlsoPowerReq "LBMS Control Grid Isolation Power Request";
CM_ SG_ 793 LBMS_FaultSt_SOCLow "SOC LOW Fault of Battery";
CM_ SG_ 793 LBMS_FaultNum "Number of LBMS Faults";
CM_ SG_ 793 LBMS_FaultCode "LBMS Fault Code";
CM_ SG_ 793 LBMS_DisconnectSt "Low voltage battery power supply disconnect state";
CM_ SG_ 973 LBMS_SOH "LBMS State of Health";
CM_ SG_ 973 LBMS_SOHVD "LBMS Validity of SOH";
CM_ SG_ 973 LBMS_Current "LBMS Battery Current";
CM_ SG_ 973 LBMS_ChrgCurrentReq "Battery charging current request";
CM_ SG_ 973 LBMS_CellTotVolt "LBMS The total internal voltage of the battery";
CM_ SG_ 973 LBMS_CellTotVoltVD "LBMS The total internal voltage of the battery Validity";
CM_ SG_ 973 LBMS_ChargReqEn "Autocharge Request of Low voltage battery Management System Enable state";
CM_ SG_ 973 LBMS_WorkSt "LBMS Battery Working State";
CM_ SG_ 973 LBMS_MOSSt "State of Mos";
CM_ SG_ 973 LBMS_WakeupSource "WakeupSource";
CM_ SG_ 973 LBMS_HardWireSt "Hardwire  state ";
CM_ SG_ 973 LBMS_QC "Quiescent Current";
CM_ SG_ 973 LBMS_WireHarnConSt "Wire harness connect state";
CM_ SG_ 973 LBMS_SOCCaliMode "The Method of The last SOC  Calibration";
CM_ SG_ 973 LBMS_ChrgCurrentLimt1 "Charge current limit MAP1";
CM_ SG_ 973 LBMS_ChrgCurrentLimt2 "Charge current limit MAP2";
CM_ SG_ 973 LBMS_ChrgCurrentLimt1VD "Charge current limit MAP1 Validity";
CM_ SG_ 973 LBMS_ChrgCurrentLimt2VD "Charge current limit MAP2 Validity";
CM_ SG_ 973 LBMS_Cell1Volt "Cell voltage 1";
CM_ SG_ 973 LBMS_Cell1VoltVD "Cell voltage 1 validity";
CM_ SG_ 973 LBMS_Cell2Volt "Cell voltage 2";
CM_ SG_ 973 LBMS_Cell2VoltVD "Cell voltage 2 validity";
CM_ SG_ 973 LBMS_Cell3Volt "Cell voltage 3";
CM_ SG_ 973 LBMS_Cell3VoltVD "Cell voltage 3 validity";
CM_ SG_ 973 LBMS_Cell4Volt "Cell voltage 4";
CM_ SG_ 973 LBMS_Cell4VoltVD "Cell voltage 4 validity";
CM_ SG_ 973 LBMS_CellMaxVolt "Cell maximum voltage";
CM_ SG_ 973 LBMS_CellMinVolt "Cell minimum voltage ";
CM_ SG_ 973 LBMS_Cell1BalanceSt "Balance state of the cell 1";
CM_ SG_ 973 LBMS_Cell2BalanceSt "Balance state of the cell 2";
CM_ SG_ 973 LBMS_Cell3BalanceSt "Balance state of the cell 3";
CM_ SG_ 973 LBMS_Cell4BalanceSt "Balance state of the cell 4";
CM_ SG_ 973 LBMS_CellTemp1 "Battery cell temperature 1";
CM_ SG_ 973 LBMS_CellTemp2 "Battery cell temperature 2";
CM_ SG_ 973 LBMS_CellTemp3 "Battery cell temperature 3";
CM_ SG_ 973 LBMS_CellTemp1VD "Battery cell temperature 1 validity";
CM_ SG_ 973 LBMS_CellTemp2VD "Battery cell temperature 2 validity";
CM_ SG_ 973 LBMS_CellTemp3VD "Battery cell temperature 3 validity";
CM_ SG_ 973 LBMS_McuTemp "MCU temperature signal";
CM_ SG_ 973 LBMS_McuTempVD "MCU temperature signal validity";
CM_ SG_ 973 LBMS_MosTemp1 "MOS1 temperature signal";
CM_ SG_ 973 LBMS_MosTemp1VD "MOS1 temperature signal validity";
CM_ SG_ 973 LBMS_CurrentVD "LBMS battery current validity";
CM_ SG_ 973 LBMS_MosTemp2 "MOS2 temperature signal";
CM_ SG_ 973 LBMS_MosTemp2VD "MOS2 temperature signal validity";
CM_ SG_ 973 LBMS_ShuntTemp "Shunt temperature signal";
CM_ SG_ 973 LBMS_ShuntTempVD "Shunt temperature signal validity";
CM_ SG_ 973 LBMS_BalanTemp1 "Balance temperature 1 signal";
CM_ SG_ 973 LBMS_BalanTemp1VD "Balance temperature 1 signal validity";
CM_ SG_ 973 LBMS_BalanTemp2 "Balance temperature 2 signal";
CM_ SG_ 973 LBMS_BalanTemp2VD "Balance temperature 2 signal validity";
CM_ SG_ 973 LBMS_FaultSt_OVB "Over voltage fault of Battery";
CM_ SG_ 973 LBMS_FaultSt_OVC "Over voltage fault of cell ";
CM_ SG_ 973 LBMS_FaultSt_CVD " Cell  voltage different fault";
CM_ SG_ 973 LBMS_FaultSt_LVB "Low voltage fault of Battery";
CM_ SG_ 973 LBMS_FaultSt_LVC "Low voltage fault of Cell";
CM_ SG_ 973 LBMS_FaultSt_OTB "Over temperature fault of Battery";
CM_ SG_ 973 LBMS_FaultSt_OTMC "Over temperature fault of MCU";
CM_ SG_ 973 LBMS_FaultSt_OTMO "Over temperature fault of MOS";
CM_ SG_ 973 LBMS_FaultSt_OTS "Over temperature fault of Shunt";
CM_ SG_ 973 LBMS_FaultSt_OTCB "Over temperature fault of cell Balance";
CM_ SG_ 973 LBMS_FaultSt_CTD "Cell temperature different fault";
CM_ SG_ 973 LBMS_FaultSt_LT "Low temperature fault";
CM_ SG_ 973 LBMS_FaultSt_ChgOC "Charge over current fault";
CM_ SG_ 973 LBMS_FaultSt_DsgOC "Discharge over current fault";
CM_ SG_ 973 LBMS_FaultSt_Hard_CellVolCol "Cell volt collect open hardware fault";
CM_ SG_ 973 LBMS_FaultSt_Hard_TempColBat "Temperature collect hardware fault of Battery";
CM_ SG_ 973 LBMS_FaultSt_Hard_TemColMOS "Temperature collect hardware fault of MOS";
CM_ SG_ 973 LBMS_FaultSt_Hard_TemColMCU "Temperature collect hardware fault of MCU";
CM_ SG_ 973 LBMS_FaultSt_Hard_Shunt "Shunt  hardware fault";
CM_ SG_ 973 LBMS_FaultSt_Hard_ChgMOS "Charge mos hardware fault";
CM_ SG_ 973 LBMS_FaultSt_Hard_DsgMOS "Discharge mos hardware fault";
CM_ SG_ 973 LBMS_FaultSt_Hard_AFE "AFE hardware fault";
CM_ SG_ 973 LBMS_FaultSt_Hard_MCU "MCU hardware fault";
CM_ SG_ 973 LBMS_FaultSt_Hard_SBC "SBC hardware fault";
CM_ SG_ 973 LBMS_FaultSt_Hard_DCDC "DCDC hardeware fault";
CM_ SG_ 973 LBMS_FaultSt_CANBusOff "Communication bus off fault";
CM_ SG_ 973 LBMS_FaultSt_CANTimeOut "Communication timeout fault";
CM_ SG_ 973 LBMS_FaultSt_CANCrcErr "Communication crc fault";
CM_ SG_ 973 LBMS_CumuChargeAh "Cumulate  Charge Ah";
CM_ SG_ 973 LBMS_CumuDischargeAh "Cumulate  Discharge Ah";
CM_ SG_ 973 LBMS_LastFullChargeAh "Throughput From last Full Charge Correction";
CM_ SG_ 973 LBMS_HisLockPackSt "Historical lock State";
CM_ SG_ 973 LBMS_CurentLockPackSt "Current lock State";
CM_ SG_ 973 LBMS_ExternalCharging "External Ground Charging State";
CM_ SG_ 973 LBMS_LastFullChargeTime "Time From last Full Charge Correction";
CM_ SG_ 973 LBMS_StaticTime "Accumulated Battery Static Time";
CM_ SG_ 973 LBMS_AppVersionFirst "1st Digit of The APP Version Number";
CM_ SG_ 973 LBMS_AppVersionSecond "2nd Digit of The APP Version Number";
CM_ SG_ 973 LBMS_AppVersionThird "3rd Digit of The APP Version Number";
CM_ SG_ 973 LBMS_BootVersionFirst "1st Digit of The BOOT Version Number";
CM_ SG_ 973 LBMS_BootVersionSecond "2nd Digit of The BOOT Version Number";
CM_ SG_ 973 LBMS_HwVersion "HW Version Number, 1Byte";
CM_ SG_ 973 LBMS_Supplier "LBMS Supplier";
CM_ SG_ 973 LBMS_UpackRvsVolt "LBMS Battery Negative Voltage of Pack";
CM_ SG_ 973 LBMS_UpackRvsVoltVD "LBMS Battery Negative Voltage of Pack Validity";

BA_DEF_ BO_  "GenMsgCycleTime" INT 0 0;
BA_DEF_ BO_  "GenMsgCycleTimeFast" INT 0 0;
BA_DEF_ BO_  "GenMsgSendType" ENUM  "Periodic","Event","IfActive","POE","PA","FixedPeriodic","Event","EnabledPeriodic","NotUsed","NotUsed","EventPeriodic","NotUsed","NotUsed","NoMsgSendType";
BA_DEF_ BO_  "VFrameFormat" ENUM  "StandardCAN","ExtendedCAN","reserved","reserved","reserved","reserved","reserved","reserved","reserved","reserved","reserved","reserved","reserved","reserved","StandardCAN_FD","ExtendedCAN_FD";
BA_DEF_ BO_  "CANFD_BRS" ENUM  "0","1";
BA_DEF_ SG_  "EventCommandSignal" ENUM  "No","Yes";
BA_DEF_ SG_  "GatewayedSignals" ENUM  "No","Yes";
BA_DEF_ SG_  "GenSigInactiveValue" HEX 0 0;
BA_DEF_ SG_  "GenSigInvalidValue" HEX 0 0;
BA_DEF_ SG_  "GenSigSendType" ENUM  "Trigger","Passive","Cyclic","OnWrite","OnWriteWithRepetition","OnChange","OnChangeWithRepetition","IfActive","IfActiveWithRepetition","NoSigSendType";
BA_DEF_ SG_  "GenSigStartValue" HEX 0 0;
BA_DEF_ SG_  "GenSigTimeoutValue" HEX 0 0;
BA_DEF_ SG_  "Remark" STRING ;
BA_DEF_  "Manufacturer" STRING ;
BA_DEF_  "Project" STRING ;
BA_DEF_  "Version" STRING ;
BA_DEF_  "Date" STRING ;
BA_DEF_  "Author" STRING ;
BA_DEF_  "DBName" STRING ;
BA_DEF_  "BusType" STRING ;
BA_DEF_  "Checker" STRING ;
BA_DEF_  "Approver" STRING ;
BA_ "Manufacturer" "GACRND";
BA_ "Project" "A88";
BA_ "Version" "0.1";
BA_ "Date" "2025/5/30 15:05:41";
BA_ "Author" "LeoFeng";
BA_ "DBName" "LBMSCZR_CANFD2";
BA_ "BusType" "CAN FD";
BA_ "Checker" "Miss Fan";
BA_ "Approver" "Mr Hu";

BA_ "GenMsgCycleTime" BO_ 1236 0;
BA_ "GenMsgCycleTimeFast" BO_ 1236 0;
BA_ "GenMsgSendType" BO_ 1236 1;
BA_ "VFrameFormat" BO_ 1236 14;
BA_ "CANFD_BRS" BO_ 1236 1;
BA_ "GenMsgCycleTime" BO_ 998 200;
BA_ "GenMsgCycleTimeFast" BO_ 998 0;
BA_ "GenMsgSendType" BO_ 998 0;
BA_ "VFrameFormat" BO_ 998 14;
BA_ "CANFD_BRS" BO_ 998 1;
BA_ "GenMsgCycleTime" BO_ 616 20;
BA_ "GenMsgCycleTimeFast" BO_ 616 0;
BA_ "GenMsgSendType" BO_ 616 0;
BA_ "VFrameFormat" BO_ 616 14;
BA_ "CANFD_BRS" BO_ 616 1;
BA_ "GenMsgCycleTime" BO_ 616 20;
BA_ "GenMsgCycleTimeFast" BO_ 616 0;
BA_ "GenMsgSendType" BO_ 616 0;
BA_ "VFrameFormat" BO_ 616 14;
BA_ "CANFD_BRS" BO_ 616 1;
BA_ "GenMsgCycleTime" BO_ 616 20;
BA_ "GenMsgCycleTimeFast" BO_ 616 0;
BA_ "GenMsgSendType" BO_ 616 0;
BA_ "VFrameFormat" BO_ 616 14;
BA_ "CANFD_BRS" BO_ 616 1;
BA_ "GenMsgCycleTime" BO_ 616 20;
BA_ "GenMsgCycleTimeFast" BO_ 616 0;
BA_ "GenMsgSendType" BO_ 616 0;
BA_ "VFrameFormat" BO_ 616 14;
BA_ "CANFD_BRS" BO_ 616 1;
BA_ "GenMsgCycleTime" BO_ 616 20;
BA_ "GenMsgCycleTimeFast" BO_ 616 0;
BA_ "GenMsgSendType" BO_ 616 0;
BA_ "VFrameFormat" BO_ 616 14;
BA_ "CANFD_BRS" BO_ 616 1;
BA_ "GenMsgCycleTime" BO_ 616 20;
BA_ "GenMsgCycleTimeFast" BO_ 616 0;
BA_ "GenMsgSendType" BO_ 616 0;
BA_ "VFrameFormat" BO_ 616 14;
BA_ "CANFD_BRS" BO_ 616 1;
BA_ "GenMsgCycleTime" BO_ 616 20;
BA_ "GenMsgCycleTimeFast" BO_ 616 0;
BA_ "GenMsgSendType" BO_ 616 0;
BA_ "VFrameFormat" BO_ 616 14;
BA_ "CANFD_BRS" BO_ 616 1;
BA_ "GenMsgCycleTime" BO_ 616 20;
BA_ "GenMsgCycleTimeFast" BO_ 616 0;
BA_ "GenMsgSendType" BO_ 616 0;
BA_ "VFrameFormat" BO_ 616 14;
BA_ "CANFD_BRS" BO_ 616 1;
BA_ "GenMsgCycleTime" BO_ 616 20;
BA_ "GenMsgCycleTimeFast" BO_ 616 0;
BA_ "GenMsgSendType" BO_ 616 0;
BA_ "VFrameFormat" BO_ 616 14;
BA_ "CANFD_BRS" BO_ 616 1;
BA_ "GenMsgCycleTime" BO_ 1359 200;
BA_ "GenMsgCycleTimeFast" BO_ 1359 0;
BA_ "GenMsgSendType" BO_ 1359 0;
BA_ "VFrameFormat" BO_ 1359 0;
BA_ "CANFD_BRS" BO_ 1359 1;
BA_ "GenMsgCycleTime" BO_ 1359 200;
BA_ "GenMsgCycleTimeFast" BO_ 1359 0;
BA_ "GenMsgSendType" BO_ 1359 0;
BA_ "VFrameFormat" BO_ 1359 0;
BA_ "CANFD_BRS" BO_ 1359 1;
BA_ "GenMsgCycleTime" BO_ 1359 200;
BA_ "GenMsgCycleTimeFast" BO_ 1359 0;
BA_ "GenMsgSendType" BO_ 1359 0;
BA_ "VFrameFormat" BO_ 1359 0;
BA_ "CANFD_BRS" BO_ 1359 1;
BA_ "GenMsgCycleTime" BO_ 1359 200;
BA_ "GenMsgCycleTimeFast" BO_ 1359 0;
BA_ "GenMsgSendType" BO_ 1359 0;
BA_ "VFrameFormat" BO_ 1359 0;
BA_ "CANFD_BRS" BO_ 1359 1;
BA_ "GenMsgCycleTime" BO_ 1359 200;
BA_ "GenMsgCycleTimeFast" BO_ 1359 0;
BA_ "GenMsgSendType" BO_ 1359 0;
BA_ "VFrameFormat" BO_ 1359 0;
BA_ "CANFD_BRS" BO_ 1359 1;
BA_ "GenMsgCycleTime" BO_ 1359 200;
BA_ "GenMsgCycleTimeFast" BO_ 1359 0;
BA_ "GenMsgSendType" BO_ 1359 0;
BA_ "VFrameFormat" BO_ 1359 0;
BA_ "CANFD_BRS" BO_ 1359 1;
BA_ "GenMsgCycleTime" BO_ 352 10;
BA_ "GenMsgCycleTimeFast" BO_ 352 0;
BA_ "GenMsgSendType" BO_ 352 0;
BA_ "VFrameFormat" BO_ 352 14;
BA_ "CANFD_BRS" BO_ 352 1;
BA_ "GenMsgCycleTime" BO_ 352 10;
BA_ "GenMsgCycleTimeFast" BO_ 352 0;
BA_ "GenMsgSendType" BO_ 352 0;
BA_ "VFrameFormat" BO_ 352 14;
BA_ "CANFD_BRS" BO_ 352 1;
BA_ "GenMsgCycleTime" BO_ 884 100;
BA_ "GenMsgCycleTimeFast" BO_ 884 0;
BA_ "GenMsgSendType" BO_ 884 0;
BA_ "VFrameFormat" BO_ 884 14;
BA_ "CANFD_BRS" BO_ 884 1;
BA_ "GenMsgCycleTime" BO_ 884 100;
BA_ "GenMsgCycleTimeFast" BO_ 884 0;
BA_ "GenMsgSendType" BO_ 884 0;
BA_ "VFrameFormat" BO_ 884 14;
BA_ "CANFD_BRS" BO_ 884 1;
BA_ "GenMsgCycleTime" BO_ 884 100;
BA_ "GenMsgCycleTimeFast" BO_ 884 0;
BA_ "GenMsgSendType" BO_ 884 0;
BA_ "VFrameFormat" BO_ 884 14;
BA_ "CANFD_BRS" BO_ 884 1;
BA_ "GenMsgCycleTime" BO_ 884 100;
BA_ "GenMsgCycleTimeFast" BO_ 884 0;
BA_ "GenMsgSendType" BO_ 884 0;
BA_ "VFrameFormat" BO_ 884 14;
BA_ "CANFD_BRS" BO_ 884 1;
BA_ "GenMsgCycleTime" BO_ 884 100;
BA_ "GenMsgCycleTimeFast" BO_ 884 0;
BA_ "GenMsgSendType" BO_ 884 0;
BA_ "VFrameFormat" BO_ 884 14;
BA_ "CANFD_BRS" BO_ 884 1;
BA_ "GenMsgCycleTime" BO_ 884 100;
BA_ "GenMsgCycleTimeFast" BO_ 884 0;
BA_ "GenMsgSendType" BO_ 884 0;
BA_ "VFrameFormat" BO_ 884 14;
BA_ "CANFD_BRS" BO_ 884 1;
BA_ "GenMsgCycleTime" BO_ 884 100;
BA_ "GenMsgCycleTimeFast" BO_ 884 0;
BA_ "GenMsgSendType" BO_ 884 0;
BA_ "VFrameFormat" BO_ 884 14;
BA_ "CANFD_BRS" BO_ 884 1;
BA_ "GenMsgCycleTime" BO_ 884 100;
BA_ "GenMsgCycleTimeFast" BO_ 884 0;
BA_ "GenMsgSendType" BO_ 884 0;
BA_ "VFrameFormat" BO_ 884 14;
BA_ "CANFD_BRS" BO_ 884 1;
BA_ "GenMsgCycleTime" BO_ 884 100;
BA_ "GenMsgCycleTimeFast" BO_ 884 0;
BA_ "GenMsgSendType" BO_ 884 0;
BA_ "VFrameFormat" BO_ 884 14;
BA_ "CANFD_BRS" BO_ 884 1;
BA_ "GenMsgCycleTime" BO_ 884 100;
BA_ "GenMsgCycleTimeFast" BO_ 884 0;
BA_ "GenMsgSendType" BO_ 884 0;
BA_ "VFrameFormat" BO_ 884 14;
BA_ "CANFD_BRS" BO_ 884 1;
BA_ "GenMsgCycleTime" BO_ 884 100;
BA_ "GenMsgCycleTimeFast" BO_ 884 0;
BA_ "GenMsgSendType" BO_ 884 0;
BA_ "VFrameFormat" BO_ 884 14;
BA_ "CANFD_BRS" BO_ 884 1;
BA_ "GenMsgCycleTime" BO_ 884 100;
BA_ "GenMsgCycleTimeFast" BO_ 884 0;
BA_ "GenMsgSendType" BO_ 884 0;
BA_ "VFrameFormat" BO_ 884 14;
BA_ "CANFD_BRS" BO_ 884 1;
BA_ "GenMsgCycleTime" BO_ 884 100;
BA_ "GenMsgCycleTimeFast" BO_ 884 0;
BA_ "GenMsgSendType" BO_ 884 0;
BA_ "VFrameFormat" BO_ 884 14;
BA_ "CANFD_BRS" BO_ 884 1;
BA_ "GenMsgCycleTime" BO_ 884 100;
BA_ "GenMsgCycleTimeFast" BO_ 884 0;
BA_ "GenMsgSendType" BO_ 884 0;
BA_ "VFrameFormat" BO_ 884 14;
BA_ "CANFD_BRS" BO_ 884 1;
BA_ "GenMsgCycleTime" BO_ 884 100;
BA_ "GenMsgCycleTimeFast" BO_ 884 0;
BA_ "GenMsgSendType" BO_ 884 0;
BA_ "VFrameFormat" BO_ 884 14;
BA_ "CANFD_BRS" BO_ 884 1;
BA_ "GenMsgCycleTime" BO_ 884 100;
BA_ "GenMsgCycleTimeFast" BO_ 884 0;
BA_ "GenMsgSendType" BO_ 884 0;
BA_ "VFrameFormat" BO_ 884 14;
BA_ "CANFD_BRS" BO_ 884 1;
BA_ "GenMsgCycleTime" BO_ 514 10;
BA_ "GenMsgCycleTimeFast" BO_ 514 0;
BA_ "GenMsgSendType" BO_ 514 0;
BA_ "VFrameFormat" BO_ 514 14;
BA_ "CANFD_BRS" BO_ 514 1;
BA_ "GenMsgCycleTime" BO_ 514 10;
BA_ "GenMsgCycleTimeFast" BO_ 514 0;
BA_ "GenMsgSendType" BO_ 514 0;
BA_ "VFrameFormat" BO_ 514 14;
BA_ "CANFD_BRS" BO_ 514 1;
BA_ "GenMsgCycleTime" BO_ 514 10;
BA_ "GenMsgCycleTimeFast" BO_ 514 0;
BA_ "GenMsgSendType" BO_ 514 0;
BA_ "VFrameFormat" BO_ 514 14;
BA_ "CANFD_BRS" BO_ 514 1;
BA_ "GenMsgCycleTime" BO_ 514 10;
BA_ "GenMsgCycleTimeFast" BO_ 514 0;
BA_ "GenMsgSendType" BO_ 514 0;
BA_ "VFrameFormat" BO_ 514 14;
BA_ "CANFD_BRS" BO_ 514 1;
BA_ "GenMsgCycleTime" BO_ 909 100;
BA_ "GenMsgCycleTimeFast" BO_ 909 0;
BA_ "GenMsgSendType" BO_ 909 0;
BA_ "VFrameFormat" BO_ 909 14;
BA_ "CANFD_BRS" BO_ 909 1;
BA_ "GenMsgCycleTime" BO_ 909 100;
BA_ "GenMsgCycleTimeFast" BO_ 909 0;
BA_ "GenMsgSendType" BO_ 909 0;
BA_ "VFrameFormat" BO_ 909 14;
BA_ "CANFD_BRS" BO_ 909 1;
BA_ "GenMsgCycleTime" BO_ 909 100;
BA_ "GenMsgCycleTimeFast" BO_ 909 0;
BA_ "GenMsgSendType" BO_ 909 0;
BA_ "VFrameFormat" BO_ 909 14;
BA_ "CANFD_BRS" BO_ 909 1;
BA_ "GenMsgCycleTime" BO_ 909 100;
BA_ "GenMsgCycleTimeFast" BO_ 909 0;
BA_ "GenMsgSendType" BO_ 909 0;
BA_ "VFrameFormat" BO_ 909 14;
BA_ "CANFD_BRS" BO_ 909 1;
BA_ "GenMsgCycleTime" BO_ 909 100;
BA_ "GenMsgCycleTimeFast" BO_ 909 0;
BA_ "GenMsgSendType" BO_ 909 0;
BA_ "VFrameFormat" BO_ 909 14;
BA_ "CANFD_BRS" BO_ 909 1;
BA_ "GenMsgCycleTime" BO_ 909 100;
BA_ "GenMsgCycleTimeFast" BO_ 909 0;
BA_ "GenMsgSendType" BO_ 909 0;
BA_ "VFrameFormat" BO_ 909 14;
BA_ "CANFD_BRS" BO_ 909 1;
BA_ "GenMsgCycleTime" BO_ 909 100;
BA_ "GenMsgCycleTimeFast" BO_ 909 0;
BA_ "GenMsgSendType" BO_ 909 0;
BA_ "VFrameFormat" BO_ 909 14;
BA_ "CANFD_BRS" BO_ 909 1;
BA_ "GenMsgCycleTime" BO_ 909 100;
BA_ "GenMsgCycleTimeFast" BO_ 909 0;
BA_ "GenMsgSendType" BO_ 909 0;
BA_ "VFrameFormat" BO_ 909 14;
BA_ "CANFD_BRS" BO_ 909 1;
BA_ "GenMsgCycleTime" BO_ 909 100;
BA_ "GenMsgCycleTimeFast" BO_ 909 0;
BA_ "GenMsgSendType" BO_ 909 0;
BA_ "VFrameFormat" BO_ 909 14;
BA_ "CANFD_BRS" BO_ 909 1;
BA_ "GenMsgCycleTime" BO_ 792 100;
BA_ "GenMsgCycleTimeFast" BO_ 792 0;
BA_ "GenMsgSendType" BO_ 792 0;
BA_ "VFrameFormat" BO_ 792 14;
BA_ "CANFD_BRS" BO_ 792 1;
BA_ "GenMsgCycleTime" BO_ 792 100;
BA_ "GenMsgCycleTimeFast" BO_ 792 0;
BA_ "GenMsgSendType" BO_ 792 0;
BA_ "VFrameFormat" BO_ 792 14;
BA_ "CANFD_BRS" BO_ 792 1;
BA_ "GenMsgCycleTime" BO_ 792 100;
BA_ "GenMsgCycleTimeFast" BO_ 792 0;
BA_ "GenMsgSendType" BO_ 792 0;
BA_ "VFrameFormat" BO_ 792 14;
BA_ "CANFD_BRS" BO_ 792 1;
BA_ "GenMsgCycleTime" BO_ 792 100;
BA_ "GenMsgCycleTimeFast" BO_ 792 0;
BA_ "GenMsgSendType" BO_ 792 0;
BA_ "VFrameFormat" BO_ 792 14;
BA_ "CANFD_BRS" BO_ 792 1;
BA_ "GenMsgCycleTime" BO_ 792 100;
BA_ "GenMsgCycleTimeFast" BO_ 792 0;
BA_ "GenMsgSendType" BO_ 792 0;
BA_ "VFrameFormat" BO_ 792 14;
BA_ "CANFD_BRS" BO_ 792 1;
BA_ "GenMsgCycleTime" BO_ 792 100;
BA_ "GenMsgCycleTimeFast" BO_ 792 0;
BA_ "GenMsgSendType" BO_ 792 0;
BA_ "VFrameFormat" BO_ 792 14;
BA_ "CANFD_BRS" BO_ 792 1;
BA_ "GenMsgCycleTime" BO_ 792 100;
BA_ "GenMsgCycleTimeFast" BO_ 792 0;
BA_ "GenMsgSendType" BO_ 792 0;
BA_ "VFrameFormat" BO_ 792 14;
BA_ "CANFD_BRS" BO_ 792 1;
BA_ "GenMsgCycleTime" BO_ 792 100;
BA_ "GenMsgCycleTimeFast" BO_ 792 0;
BA_ "GenMsgSendType" BO_ 792 0;
BA_ "VFrameFormat" BO_ 792 14;
BA_ "CANFD_BRS" BO_ 792 1;
BA_ "GenMsgCycleTime" BO_ 792 100;
BA_ "GenMsgCycleTimeFast" BO_ 792 0;
BA_ "GenMsgSendType" BO_ 792 0;
BA_ "VFrameFormat" BO_ 792 14;
BA_ "CANFD_BRS" BO_ 792 1;
BA_ "GenMsgCycleTime" BO_ 792 100;
BA_ "GenMsgCycleTimeFast" BO_ 792 0;
BA_ "GenMsgSendType" BO_ 792 0;
BA_ "VFrameFormat" BO_ 792 14;
BA_ "CANFD_BRS" BO_ 792 1;
BA_ "GenMsgCycleTime" BO_ 792 100;
BA_ "GenMsgCycleTimeFast" BO_ 792 0;
BA_ "GenMsgSendType" BO_ 792 0;
BA_ "VFrameFormat" BO_ 792 14;
BA_ "CANFD_BRS" BO_ 792 1;
BA_ "GenMsgCycleTime" BO_ 792 100;
BA_ "GenMsgCycleTimeFast" BO_ 792 0;
BA_ "GenMsgSendType" BO_ 792 0;
BA_ "VFrameFormat" BO_ 792 14;
BA_ "CANFD_BRS" BO_ 792 1;
BA_ "GenMsgCycleTime" BO_ 1395 200;
BA_ "GenMsgCycleTimeFast" BO_ 1395 0;
BA_ "GenMsgSendType" BO_ 1395 0;
BA_ "VFrameFormat" BO_ 1395 0;
BA_ "CANFD_BRS" BO_ 1395 1;
BA_ "GenMsgCycleTime" BO_ 1395 200;
BA_ "GenMsgCycleTimeFast" BO_ 1395 0;
BA_ "GenMsgSendType" BO_ 1395 0;
BA_ "VFrameFormat" BO_ 1395 0;
BA_ "CANFD_BRS" BO_ 1395 1;
BA_ "GenMsgCycleTime" BO_ 1395 200;
BA_ "GenMsgCycleTimeFast" BO_ 1395 0;
BA_ "GenMsgSendType" BO_ 1395 0;
BA_ "VFrameFormat" BO_ 1395 0;
BA_ "CANFD_BRS" BO_ 1395 1;
BA_ "GenMsgCycleTime" BO_ 1395 200;
BA_ "GenMsgCycleTimeFast" BO_ 1395 0;
BA_ "GenMsgSendType" BO_ 1395 0;
BA_ "VFrameFormat" BO_ 1395 0;
BA_ "CANFD_BRS" BO_ 1395 1;
BA_ "GenMsgCycleTime" BO_ 1395 200;
BA_ "GenMsgCycleTimeFast" BO_ 1395 0;
BA_ "GenMsgSendType" BO_ 1395 0;
BA_ "VFrameFormat" BO_ 1395 0;
BA_ "CANFD_BRS" BO_ 1395 1;
BA_ "GenMsgCycleTime" BO_ 1395 200;
BA_ "GenMsgCycleTimeFast" BO_ 1395 0;
BA_ "GenMsgSendType" BO_ 1395 0;
BA_ "VFrameFormat" BO_ 1395 0;
BA_ "CANFD_BRS" BO_ 1395 1;
BA_ "GenMsgCycleTime" BO_ 1697 0;
BA_ "GenMsgCycleTimeFast" BO_ 1697 0;
BA_ "GenMsgSendType" BO_ 1697 1;
BA_ "VFrameFormat" BO_ 1697 14;
BA_ "CANFD_BRS" BO_ 1697 1;
BA_ "GenMsgCycleTime" BO_ 1705 0;
BA_ "GenMsgCycleTimeFast" BO_ 1705 0;
BA_ "GenMsgSendType" BO_ 1705 1;
BA_ "VFrameFormat" BO_ 1705 14;
BA_ "CANFD_BRS" BO_ 1705 1;
BA_ "GenMsgCycleTime" BO_ 1449 200;
BA_ "GenMsgCycleTimeFast" BO_ 1449 0;
BA_ "GenMsgSendType" BO_ 1449 0;
BA_ "VFrameFormat" BO_ 1449 0;
BA_ "CANFD_BRS" BO_ 1449 1;
BA_ "GenMsgCycleTime" BO_ 1449 200;
BA_ "GenMsgCycleTimeFast" BO_ 1449 0;
BA_ "GenMsgSendType" BO_ 1449 0;
BA_ "VFrameFormat" BO_ 1449 0;
BA_ "CANFD_BRS" BO_ 1449 1;
BA_ "GenMsgCycleTime" BO_ 1449 200;
BA_ "GenMsgCycleTimeFast" BO_ 1449 0;
BA_ "GenMsgSendType" BO_ 1449 0;
BA_ "VFrameFormat" BO_ 1449 0;
BA_ "CANFD_BRS" BO_ 1449 1;
BA_ "GenMsgCycleTime" BO_ 1449 200;
BA_ "GenMsgCycleTimeFast" BO_ 1449 0;
BA_ "GenMsgSendType" BO_ 1449 0;
BA_ "VFrameFormat" BO_ 1449 0;
BA_ "CANFD_BRS" BO_ 1449 1;
BA_ "GenMsgCycleTime" BO_ 1449 200;
BA_ "GenMsgCycleTimeFast" BO_ 1449 0;
BA_ "GenMsgSendType" BO_ 1449 0;
BA_ "VFrameFormat" BO_ 1449 0;
BA_ "CANFD_BRS" BO_ 1449 1;
BA_ "GenMsgCycleTime" BO_ 1449 200;
BA_ "GenMsgCycleTimeFast" BO_ 1449 0;
BA_ "GenMsgSendType" BO_ 1449 0;
BA_ "VFrameFormat" BO_ 1449 0;
BA_ "CANFD_BRS" BO_ 1449 1;
BA_ "GenMsgCycleTime" BO_ 793 100;
BA_ "GenMsgCycleTimeFast" BO_ 793 0;
BA_ "GenMsgSendType" BO_ 793 0;
BA_ "VFrameFormat" BO_ 793 14;
BA_ "CANFD_BRS" BO_ 793 1;
BA_ "GenMsgCycleTime" BO_ 793 100;
BA_ "GenMsgCycleTimeFast" BO_ 793 0;
BA_ "GenMsgSendType" BO_ 793 0;
BA_ "VFrameFormat" BO_ 793 14;
BA_ "CANFD_BRS" BO_ 793 1;
BA_ "GenMsgCycleTime" BO_ 793 100;
BA_ "GenMsgCycleTimeFast" BO_ 793 0;
BA_ "GenMsgSendType" BO_ 793 0;
BA_ "VFrameFormat" BO_ 793 14;
BA_ "CANFD_BRS" BO_ 793 1;
BA_ "GenMsgCycleTime" BO_ 793 100;
BA_ "GenMsgCycleTimeFast" BO_ 793 0;
BA_ "GenMsgSendType" BO_ 793 0;
BA_ "VFrameFormat" BO_ 793 14;
BA_ "CANFD_BRS" BO_ 793 1;
BA_ "GenMsgCycleTime" BO_ 793 100;
BA_ "GenMsgCycleTimeFast" BO_ 793 0;
BA_ "GenMsgSendType" BO_ 793 0;
BA_ "VFrameFormat" BO_ 793 14;
BA_ "CANFD_BRS" BO_ 793 1;
BA_ "GenMsgCycleTime" BO_ 793 100;
BA_ "GenMsgCycleTimeFast" BO_ 793 0;
BA_ "GenMsgSendType" BO_ 793 0;
BA_ "VFrameFormat" BO_ 793 14;
BA_ "CANFD_BRS" BO_ 793 1;
BA_ "GenMsgCycleTime" BO_ 793 100;
BA_ "GenMsgCycleTimeFast" BO_ 793 0;
BA_ "GenMsgSendType" BO_ 793 0;
BA_ "VFrameFormat" BO_ 793 14;
BA_ "CANFD_BRS" BO_ 793 1;
BA_ "GenMsgCycleTime" BO_ 793 100;
BA_ "GenMsgCycleTimeFast" BO_ 793 0;
BA_ "GenMsgSendType" BO_ 793 0;
BA_ "VFrameFormat" BO_ 793 14;
BA_ "CANFD_BRS" BO_ 793 1;
BA_ "GenMsgCycleTime" BO_ 793 100;
BA_ "GenMsgCycleTimeFast" BO_ 793 0;
BA_ "GenMsgSendType" BO_ 793 0;
BA_ "VFrameFormat" BO_ 793 14;
BA_ "CANFD_BRS" BO_ 793 1;
BA_ "GenMsgCycleTime" BO_ 793 100;
BA_ "GenMsgCycleTimeFast" BO_ 793 0;
BA_ "GenMsgSendType" BO_ 793 0;
BA_ "VFrameFormat" BO_ 793 14;
BA_ "CANFD_BRS" BO_ 793 1;
BA_ "GenMsgCycleTime" BO_ 793 100;
BA_ "GenMsgCycleTimeFast" BO_ 793 0;
BA_ "GenMsgSendType" BO_ 793 0;
BA_ "VFrameFormat" BO_ 793 14;
BA_ "CANFD_BRS" BO_ 793 1;
BA_ "GenMsgCycleTime" BO_ 793 100;
BA_ "GenMsgCycleTimeFast" BO_ 793 0;
BA_ "GenMsgSendType" BO_ 793 0;
BA_ "VFrameFormat" BO_ 793 14;
BA_ "CANFD_BRS" BO_ 793 1;
BA_ "GenMsgCycleTime" BO_ 793 100;
BA_ "GenMsgCycleTimeFast" BO_ 793 0;
BA_ "GenMsgSendType" BO_ 793 0;
BA_ "VFrameFormat" BO_ 793 14;
BA_ "CANFD_BRS" BO_ 793 1;
BA_ "GenMsgCycleTime" BO_ 793 100;
BA_ "GenMsgCycleTimeFast" BO_ 793 0;
BA_ "GenMsgSendType" BO_ 793 0;
BA_ "VFrameFormat" BO_ 793 14;
BA_ "CANFD_BRS" BO_ 793 1;
BA_ "GenMsgCycleTime" BO_ 793 100;
BA_ "GenMsgCycleTimeFast" BO_ 793 0;
BA_ "GenMsgSendType" BO_ 793 0;
BA_ "VFrameFormat" BO_ 793 14;
BA_ "CANFD_BRS" BO_ 793 1;
BA_ "GenMsgCycleTime" BO_ 793 100;
BA_ "GenMsgCycleTimeFast" BO_ 793 0;
BA_ "GenMsgSendType" BO_ 793 0;
BA_ "VFrameFormat" BO_ 793 14;
BA_ "CANFD_BRS" BO_ 793 1;
BA_ "GenMsgCycleTime" BO_ 793 100;
BA_ "GenMsgCycleTimeFast" BO_ 793 0;
BA_ "GenMsgSendType" BO_ 793 0;
BA_ "VFrameFormat" BO_ 793 14;
BA_ "CANFD_BRS" BO_ 793 1;
BA_ "GenMsgCycleTime" BO_ 793 100;
BA_ "GenMsgCycleTimeFast" BO_ 793 0;
BA_ "GenMsgSendType" BO_ 793 0;
BA_ "VFrameFormat" BO_ 793 14;
BA_ "CANFD_BRS" BO_ 793 1;
BA_ "GenMsgCycleTime" BO_ 793 100;
BA_ "GenMsgCycleTimeFast" BO_ 793 0;
BA_ "GenMsgSendType" BO_ 793 0;
BA_ "VFrameFormat" BO_ 793 14;
BA_ "CANFD_BRS" BO_ 793 1;
BA_ "GenMsgCycleTime" BO_ 793 100;
BA_ "GenMsgCycleTimeFast" BO_ 793 0;
BA_ "GenMsgSendType" BO_ 793 0;
BA_ "VFrameFormat" BO_ 793 14;
BA_ "CANFD_BRS" BO_ 793 1;
BA_ "GenMsgCycleTime" BO_ 793 100;
BA_ "GenMsgCycleTimeFast" BO_ 793 0;
BA_ "GenMsgSendType" BO_ 793 0;
BA_ "VFrameFormat" BO_ 793 14;
BA_ "CANFD_BRS" BO_ 793 1;
BA_ "GenMsgCycleTime" BO_ 793 100;
BA_ "GenMsgCycleTimeFast" BO_ 793 0;
BA_ "GenMsgSendType" BO_ 793 0;
BA_ "VFrameFormat" BO_ 793 14;
BA_ "CANFD_BRS" BO_ 793 1;
BA_ "GenMsgCycleTime" BO_ 793 100;
BA_ "GenMsgCycleTimeFast" BO_ 793 0;
BA_ "GenMsgSendType" BO_ 793 0;
BA_ "VFrameFormat" BO_ 793 14;
BA_ "CANFD_BRS" BO_ 793 1;
BA_ "GenMsgCycleTime" BO_ 793 100;
BA_ "GenMsgCycleTimeFast" BO_ 793 0;
BA_ "GenMsgSendType" BO_ 793 0;
BA_ "VFrameFormat" BO_ 793 14;
BA_ "CANFD_BRS" BO_ 793 1;
BA_ "GenMsgCycleTime" BO_ 793 100;
BA_ "GenMsgCycleTimeFast" BO_ 793 0;
BA_ "GenMsgSendType" BO_ 793 0;
BA_ "VFrameFormat" BO_ 793 14;
BA_ "CANFD_BRS" BO_ 793 1;
BA_ "GenMsgCycleTime" BO_ 793 100;
BA_ "GenMsgCycleTimeFast" BO_ 793 0;
BA_ "GenMsgSendType" BO_ 793 0;
BA_ "VFrameFormat" BO_ 793 14;
BA_ "CANFD_BRS" BO_ 793 1;
BA_ "GenMsgCycleTime" BO_ 793 100;
BA_ "GenMsgCycleTimeFast" BO_ 793 0;
BA_ "GenMsgSendType" BO_ 793 0;
BA_ "VFrameFormat" BO_ 793 14;
BA_ "CANFD_BRS" BO_ 793 1;
BA_ "GenMsgCycleTime" BO_ 793 100;
BA_ "GenMsgCycleTimeFast" BO_ 793 0;
BA_ "GenMsgSendType" BO_ 793 0;
BA_ "VFrameFormat" BO_ 793 14;
BA_ "CANFD_BRS" BO_ 793 1;
BA_ "GenMsgCycleTime" BO_ 973 500;
BA_ "GenMsgCycleTimeFast" BO_ 973 0;
BA_ "GenMsgSendType" BO_ 973 0;
BA_ "VFrameFormat" BO_ 973 14;
BA_ "CANFD_BRS" BO_ 973 1;
BA_ "GenMsgCycleTime" BO_ 973 500;
BA_ "GenMsgCycleTimeFast" BO_ 973 0;
BA_ "GenMsgSendType" BO_ 973 0;
BA_ "VFrameFormat" BO_ 973 14;
BA_ "CANFD_BRS" BO_ 973 1;
BA_ "GenMsgCycleTime" BO_ 973 500;
BA_ "GenMsgCycleTimeFast" BO_ 973 0;
BA_ "GenMsgSendType" BO_ 973 0;
BA_ "VFrameFormat" BO_ 973 14;
BA_ "CANFD_BRS" BO_ 973 1;
BA_ "GenMsgCycleTime" BO_ 973 500;
BA_ "GenMsgCycleTimeFast" BO_ 973 0;
BA_ "GenMsgSendType" BO_ 973 0;
BA_ "VFrameFormat" BO_ 973 14;
BA_ "CANFD_BRS" BO_ 973 1;
BA_ "GenMsgCycleTime" BO_ 973 500;
BA_ "GenMsgCycleTimeFast" BO_ 973 0;
BA_ "GenMsgSendType" BO_ 973 0;
BA_ "VFrameFormat" BO_ 973 14;
BA_ "CANFD_BRS" BO_ 973 1;
BA_ "GenMsgCycleTime" BO_ 973 500;
BA_ "GenMsgCycleTimeFast" BO_ 973 0;
BA_ "GenMsgSendType" BO_ 973 0;
BA_ "VFrameFormat" BO_ 973 14;
BA_ "CANFD_BRS" BO_ 973 1;
BA_ "GenMsgCycleTime" BO_ 973 500;
BA_ "GenMsgCycleTimeFast" BO_ 973 0;
BA_ "GenMsgSendType" BO_ 973 0;
BA_ "VFrameFormat" BO_ 973 14;
BA_ "CANFD_BRS" BO_ 973 1;
BA_ "GenMsgCycleTime" BO_ 973 500;
BA_ "GenMsgCycleTimeFast" BO_ 973 0;
BA_ "GenMsgSendType" BO_ 973 0;
BA_ "VFrameFormat" BO_ 973 14;
BA_ "CANFD_BRS" BO_ 973 1;
BA_ "GenMsgCycleTime" BO_ 973 500;
BA_ "GenMsgCycleTimeFast" BO_ 973 0;
BA_ "GenMsgSendType" BO_ 973 0;
BA_ "VFrameFormat" BO_ 973 14;
BA_ "CANFD_BRS" BO_ 973 1;
BA_ "GenMsgCycleTime" BO_ 973 500;
BA_ "GenMsgCycleTimeFast" BO_ 973 0;
BA_ "GenMsgSendType" BO_ 973 0;
BA_ "VFrameFormat" BO_ 973 14;
BA_ "CANFD_BRS" BO_ 973 1;
BA_ "GenMsgCycleTime" BO_ 973 500;
BA_ "GenMsgCycleTimeFast" BO_ 973 0;
BA_ "GenMsgSendType" BO_ 973 0;
BA_ "VFrameFormat" BO_ 973 14;
BA_ "CANFD_BRS" BO_ 973 1;
BA_ "GenMsgCycleTime" BO_ 973 500;
BA_ "GenMsgCycleTimeFast" BO_ 973 0;
BA_ "GenMsgSendType" BO_ 973 0;
BA_ "VFrameFormat" BO_ 973 14;
BA_ "CANFD_BRS" BO_ 973 1;
BA_ "GenMsgCycleTime" BO_ 973 500;
BA_ "GenMsgCycleTimeFast" BO_ 973 0;
BA_ "GenMsgSendType" BO_ 973 0;
BA_ "VFrameFormat" BO_ 973 14;
BA_ "CANFD_BRS" BO_ 973 1;
BA_ "GenMsgCycleTime" BO_ 973 500;
BA_ "GenMsgCycleTimeFast" BO_ 973 0;
BA_ "GenMsgSendType" BO_ 973 0;
BA_ "VFrameFormat" BO_ 973 14;
BA_ "CANFD_BRS" BO_ 973 1;
BA_ "GenMsgCycleTime" BO_ 973 500;
BA_ "GenMsgCycleTimeFast" BO_ 973 0;
BA_ "GenMsgSendType" BO_ 973 0;
BA_ "VFrameFormat" BO_ 973 14;
BA_ "CANFD_BRS" BO_ 973 1;
BA_ "GenMsgCycleTime" BO_ 973 500;
BA_ "GenMsgCycleTimeFast" BO_ 973 0;
BA_ "GenMsgSendType" BO_ 973 0;
BA_ "VFrameFormat" BO_ 973 14;
BA_ "CANFD_BRS" BO_ 973 1;
BA_ "GenMsgCycleTime" BO_ 973 500;
BA_ "GenMsgCycleTimeFast" BO_ 973 0;
BA_ "GenMsgSendType" BO_ 973 0;
BA_ "VFrameFormat" BO_ 973 14;
BA_ "CANFD_BRS" BO_ 973 1;
BA_ "GenMsgCycleTime" BO_ 973 500;
BA_ "GenMsgCycleTimeFast" BO_ 973 0;
BA_ "GenMsgSendType" BO_ 973 0;
BA_ "VFrameFormat" BO_ 973 14;
BA_ "CANFD_BRS" BO_ 973 1;
BA_ "GenMsgCycleTime" BO_ 973 500;
BA_ "GenMsgCycleTimeFast" BO_ 973 0;
BA_ "GenMsgSendType" BO_ 973 0;
BA_ "VFrameFormat" BO_ 973 14;
BA_ "CANFD_BRS" BO_ 973 1;
BA_ "GenMsgCycleTime" BO_ 973 500;
BA_ "GenMsgCycleTimeFast" BO_ 973 0;
BA_ "GenMsgSendType" BO_ 973 0;
BA_ "VFrameFormat" BO_ 973 14;
BA_ "CANFD_BRS" BO_ 973 1;
BA_ "GenMsgCycleTime" BO_ 973 500;
BA_ "GenMsgCycleTimeFast" BO_ 973 0;
BA_ "GenMsgSendType" BO_ 973 0;
BA_ "VFrameFormat" BO_ 973 14;
BA_ "CANFD_BRS" BO_ 973 1;
BA_ "GenMsgCycleTime" BO_ 973 500;
BA_ "GenMsgCycleTimeFast" BO_ 973 0;
BA_ "GenMsgSendType" BO_ 973 0;
BA_ "VFrameFormat" BO_ 973 14;
BA_ "CANFD_BRS" BO_ 973 1;
BA_ "GenMsgCycleTime" BO_ 973 500;
BA_ "GenMsgCycleTimeFast" BO_ 973 0;
BA_ "GenMsgSendType" BO_ 973 0;
BA_ "VFrameFormat" BO_ 973 14;
BA_ "CANFD_BRS" BO_ 973 1;
BA_ "GenMsgCycleTime" BO_ 973 500;
BA_ "GenMsgCycleTimeFast" BO_ 973 0;
BA_ "GenMsgSendType" BO_ 973 0;
BA_ "VFrameFormat" BO_ 973 14;
BA_ "CANFD_BRS" BO_ 973 1;
BA_ "GenMsgCycleTime" BO_ 973 500;
BA_ "GenMsgCycleTimeFast" BO_ 973 0;
BA_ "GenMsgSendType" BO_ 973 0;
BA_ "VFrameFormat" BO_ 973 14;
BA_ "CANFD_BRS" BO_ 973 1;
BA_ "GenMsgCycleTime" BO_ 973 500;
BA_ "GenMsgCycleTimeFast" BO_ 973 0;
BA_ "GenMsgSendType" BO_ 973 0;
BA_ "VFrameFormat" BO_ 973 14;
BA_ "CANFD_BRS" BO_ 973 1;
BA_ "GenMsgCycleTime" BO_ 973 500;
BA_ "GenMsgCycleTimeFast" BO_ 973 0;
BA_ "GenMsgSendType" BO_ 973 0;
BA_ "VFrameFormat" BO_ 973 14;
BA_ "CANFD_BRS" BO_ 973 1;
BA_ "GenMsgCycleTime" BO_ 973 500;
BA_ "GenMsgCycleTimeFast" BO_ 973 0;
BA_ "GenMsgSendType" BO_ 973 0;
BA_ "VFrameFormat" BO_ 973 14;
BA_ "CANFD_BRS" BO_ 973 1;
BA_ "GenMsgCycleTime" BO_ 973 500;
BA_ "GenMsgCycleTimeFast" BO_ 973 0;
BA_ "GenMsgSendType" BO_ 973 0;
BA_ "VFrameFormat" BO_ 973 14;
BA_ "CANFD_BRS" BO_ 973 1;
BA_ "GenMsgCycleTime" BO_ 973 500;
BA_ "GenMsgCycleTimeFast" BO_ 973 0;
BA_ "GenMsgSendType" BO_ 973 0;
BA_ "VFrameFormat" BO_ 973 14;
BA_ "CANFD_BRS" BO_ 973 1;
BA_ "GenMsgCycleTime" BO_ 973 500;
BA_ "GenMsgCycleTimeFast" BO_ 973 0;
BA_ "GenMsgSendType" BO_ 973 0;
BA_ "VFrameFormat" BO_ 973 14;
BA_ "CANFD_BRS" BO_ 973 1;
BA_ "GenMsgCycleTime" BO_ 973 500;
BA_ "GenMsgCycleTimeFast" BO_ 973 0;
BA_ "GenMsgSendType" BO_ 973 0;
BA_ "VFrameFormat" BO_ 973 14;
BA_ "CANFD_BRS" BO_ 973 1;
BA_ "GenMsgCycleTime" BO_ 973 500;
BA_ "GenMsgCycleTimeFast" BO_ 973 0;
BA_ "GenMsgSendType" BO_ 973 0;
BA_ "VFrameFormat" BO_ 973 14;
BA_ "CANFD_BRS" BO_ 973 1;
BA_ "GenMsgCycleTime" BO_ 973 500;
BA_ "GenMsgCycleTimeFast" BO_ 973 0;
BA_ "GenMsgSendType" BO_ 973 0;
BA_ "VFrameFormat" BO_ 973 14;
BA_ "CANFD_BRS" BO_ 973 1;
BA_ "GenMsgCycleTime" BO_ 973 500;
BA_ "GenMsgCycleTimeFast" BO_ 973 0;
BA_ "GenMsgSendType" BO_ 973 0;
BA_ "VFrameFormat" BO_ 973 14;
BA_ "CANFD_BRS" BO_ 973 1;
BA_ "GenMsgCycleTime" BO_ 973 500;
BA_ "GenMsgCycleTimeFast" BO_ 973 0;
BA_ "GenMsgSendType" BO_ 973 0;
BA_ "VFrameFormat" BO_ 973 14;
BA_ "CANFD_BRS" BO_ 973 1;
BA_ "GenMsgCycleTime" BO_ 973 500;
BA_ "GenMsgCycleTimeFast" BO_ 973 0;
BA_ "GenMsgSendType" BO_ 973 0;
BA_ "VFrameFormat" BO_ 973 14;
BA_ "CANFD_BRS" BO_ 973 1;
BA_ "GenMsgCycleTime" BO_ 973 500;
BA_ "GenMsgCycleTimeFast" BO_ 973 0;
BA_ "GenMsgSendType" BO_ 973 0;
BA_ "VFrameFormat" BO_ 973 14;
BA_ "CANFD_BRS" BO_ 973 1;
BA_ "GenMsgCycleTime" BO_ 973 500;
BA_ "GenMsgCycleTimeFast" BO_ 973 0;
BA_ "GenMsgSendType" BO_ 973 0;
BA_ "VFrameFormat" BO_ 973 14;
BA_ "CANFD_BRS" BO_ 973 1;
BA_ "GenMsgCycleTime" BO_ 973 500;
BA_ "GenMsgCycleTimeFast" BO_ 973 0;
BA_ "GenMsgSendType" BO_ 973 0;
BA_ "VFrameFormat" BO_ 973 14;
BA_ "CANFD_BRS" BO_ 973 1;
BA_ "GenMsgCycleTime" BO_ 973 500;
BA_ "GenMsgCycleTimeFast" BO_ 973 0;
BA_ "GenMsgSendType" BO_ 973 0;
BA_ "VFrameFormat" BO_ 973 14;
BA_ "CANFD_BRS" BO_ 973 1;
BA_ "GenMsgCycleTime" BO_ 973 500;
BA_ "GenMsgCycleTimeFast" BO_ 973 0;
BA_ "GenMsgSendType" BO_ 973 0;
BA_ "VFrameFormat" BO_ 973 14;
BA_ "CANFD_BRS" BO_ 973 1;
BA_ "GenMsgCycleTime" BO_ 973 500;
BA_ "GenMsgCycleTimeFast" BO_ 973 0;
BA_ "GenMsgSendType" BO_ 973 0;
BA_ "VFrameFormat" BO_ 973 14;
BA_ "CANFD_BRS" BO_ 973 1;
BA_ "GenMsgCycleTime" BO_ 973 500;
BA_ "GenMsgCycleTimeFast" BO_ 973 0;
BA_ "GenMsgSendType" BO_ 973 0;
BA_ "VFrameFormat" BO_ 973 14;
BA_ "CANFD_BRS" BO_ 973 1;
BA_ "GenMsgCycleTime" BO_ 973 500;
BA_ "GenMsgCycleTimeFast" BO_ 973 0;
BA_ "GenMsgSendType" BO_ 973 0;
BA_ "VFrameFormat" BO_ 973 14;
BA_ "CANFD_BRS" BO_ 973 1;
BA_ "GenMsgCycleTime" BO_ 973 500;
BA_ "GenMsgCycleTimeFast" BO_ 973 0;
BA_ "GenMsgSendType" BO_ 973 0;
BA_ "VFrameFormat" BO_ 973 14;
BA_ "CANFD_BRS" BO_ 973 1;
BA_ "GenMsgCycleTime" BO_ 973 500;
BA_ "GenMsgCycleTimeFast" BO_ 973 0;
BA_ "GenMsgSendType" BO_ 973 0;
BA_ "VFrameFormat" BO_ 973 14;
BA_ "CANFD_BRS" BO_ 973 1;
BA_ "GenMsgCycleTime" BO_ 973 500;
BA_ "GenMsgCycleTimeFast" BO_ 973 0;
BA_ "GenMsgSendType" BO_ 973 0;
BA_ "VFrameFormat" BO_ 973 14;
BA_ "CANFD_BRS" BO_ 973 1;
BA_ "GenMsgCycleTime" BO_ 973 500;
BA_ "GenMsgCycleTimeFast" BO_ 973 0;
BA_ "GenMsgSendType" BO_ 973 0;
BA_ "VFrameFormat" BO_ 973 14;
BA_ "CANFD_BRS" BO_ 973 1;
BA_ "GenMsgCycleTime" BO_ 973 500;
BA_ "GenMsgCycleTimeFast" BO_ 973 0;
BA_ "GenMsgSendType" BO_ 973 0;
BA_ "VFrameFormat" BO_ 973 14;
BA_ "CANFD_BRS" BO_ 973 1;
BA_ "GenMsgCycleTime" BO_ 973 500;
BA_ "GenMsgCycleTimeFast" BO_ 973 0;
BA_ "GenMsgSendType" BO_ 973 0;
BA_ "VFrameFormat" BO_ 973 14;
BA_ "CANFD_BRS" BO_ 973 1;
BA_ "GenMsgCycleTime" BO_ 973 500;
BA_ "GenMsgCycleTimeFast" BO_ 973 0;
BA_ "GenMsgSendType" BO_ 973 0;
BA_ "VFrameFormat" BO_ 973 14;
BA_ "CANFD_BRS" BO_ 973 1;
BA_ "GenMsgCycleTime" BO_ 973 500;
BA_ "GenMsgCycleTimeFast" BO_ 973 0;
BA_ "GenMsgSendType" BO_ 973 0;
BA_ "VFrameFormat" BO_ 973 14;
BA_ "CANFD_BRS" BO_ 973 1;
BA_ "GenMsgCycleTime" BO_ 973 500;
BA_ "GenMsgCycleTimeFast" BO_ 973 0;
BA_ "GenMsgSendType" BO_ 973 0;
BA_ "VFrameFormat" BO_ 973 14;
BA_ "CANFD_BRS" BO_ 973 1;
BA_ "GenMsgCycleTime" BO_ 973 500;
BA_ "GenMsgCycleTimeFast" BO_ 973 0;
BA_ "GenMsgSendType" BO_ 973 0;
BA_ "VFrameFormat" BO_ 973 14;
BA_ "CANFD_BRS" BO_ 973 1;
BA_ "GenMsgCycleTime" BO_ 973 500;
BA_ "GenMsgCycleTimeFast" BO_ 973 0;
BA_ "GenMsgSendType" BO_ 973 0;
BA_ "VFrameFormat" BO_ 973 14;
BA_ "CANFD_BRS" BO_ 973 1;
BA_ "GenMsgCycleTime" BO_ 973 500;
BA_ "GenMsgCycleTimeFast" BO_ 973 0;
BA_ "GenMsgSendType" BO_ 973 0;
BA_ "VFrameFormat" BO_ 973 14;
BA_ "CANFD_BRS" BO_ 973 1;
BA_ "GenMsgCycleTime" BO_ 973 500;
BA_ "GenMsgCycleTimeFast" BO_ 973 0;
BA_ "GenMsgSendType" BO_ 973 0;
BA_ "VFrameFormat" BO_ 973 14;
BA_ "CANFD_BRS" BO_ 973 1;
BA_ "GenMsgCycleTime" BO_ 973 500;
BA_ "GenMsgCycleTimeFast" BO_ 973 0;
BA_ "GenMsgSendType" BO_ 973 0;
BA_ "VFrameFormat" BO_ 973 14;
BA_ "CANFD_BRS" BO_ 973 1;
BA_ "GenMsgCycleTime" BO_ 973 500;
BA_ "GenMsgCycleTimeFast" BO_ 973 0;
BA_ "GenMsgSendType" BO_ 973 0;
BA_ "VFrameFormat" BO_ 973 14;
BA_ "CANFD_BRS" BO_ 973 1;
BA_ "GenMsgCycleTime" BO_ 973 500;
BA_ "GenMsgCycleTimeFast" BO_ 973 0;
BA_ "GenMsgSendType" BO_ 973 0;
BA_ "VFrameFormat" BO_ 973 14;
BA_ "CANFD_BRS" BO_ 973 1;
BA_ "GenMsgCycleTime" BO_ 973 500;
BA_ "GenMsgCycleTimeFast" BO_ 973 0;
BA_ "GenMsgSendType" BO_ 973 0;
BA_ "VFrameFormat" BO_ 973 14;
BA_ "CANFD_BRS" BO_ 973 1;
BA_ "GenMsgCycleTime" BO_ 973 500;
BA_ "GenMsgCycleTimeFast" BO_ 973 0;
BA_ "GenMsgSendType" BO_ 973 0;
BA_ "VFrameFormat" BO_ 973 14;
BA_ "CANFD_BRS" BO_ 973 1;
BA_ "GenMsgCycleTime" BO_ 973 500;
BA_ "GenMsgCycleTimeFast" BO_ 973 0;
BA_ "GenMsgSendType" BO_ 973 0;
BA_ "VFrameFormat" BO_ 973 14;
BA_ "CANFD_BRS" BO_ 973 1;
BA_ "GenMsgCycleTime" BO_ 973 500;
BA_ "GenMsgCycleTimeFast" BO_ 973 0;
BA_ "GenMsgSendType" BO_ 973 0;
BA_ "VFrameFormat" BO_ 973 14;
BA_ "CANFD_BRS" BO_ 973 1;
BA_ "GenMsgCycleTime" BO_ 973 500;
BA_ "GenMsgCycleTimeFast" BO_ 973 0;
BA_ "GenMsgSendType" BO_ 973 0;
BA_ "VFrameFormat" BO_ 973 14;
BA_ "CANFD_BRS" BO_ 973 1;
BA_ "GenMsgCycleTime" BO_ 973 500;
BA_ "GenMsgCycleTimeFast" BO_ 973 0;
BA_ "GenMsgSendType" BO_ 973 0;
BA_ "VFrameFormat" BO_ 973 14;
BA_ "CANFD_BRS" BO_ 973 1;
BA_ "GenMsgCycleTime" BO_ 973 500;
BA_ "GenMsgCycleTimeFast" BO_ 973 0;
BA_ "GenMsgSendType" BO_ 973 0;
BA_ "VFrameFormat" BO_ 973 14;
BA_ "CANFD_BRS" BO_ 973 1;
BA_ "GenMsgCycleTime" BO_ 973 500;
BA_ "GenMsgCycleTimeFast" BO_ 973 0;
BA_ "GenMsgSendType" BO_ 973 0;
BA_ "VFrameFormat" BO_ 973 14;
BA_ "CANFD_BRS" BO_ 973 1;
BA_ "GenMsgCycleTime" BO_ 973 500;
BA_ "GenMsgCycleTimeFast" BO_ 973 0;
BA_ "GenMsgSendType" BO_ 973 0;
BA_ "VFrameFormat" BO_ 973 14;
BA_ "CANFD_BRS" BO_ 973 1;
BA_ "GenMsgCycleTime" BO_ 973 500;
BA_ "GenMsgCycleTimeFast" BO_ 973 0;
BA_ "GenMsgSendType" BO_ 973 0;
BA_ "VFrameFormat" BO_ 973 14;
BA_ "CANFD_BRS" BO_ 973 1;
BA_ "GenMsgCycleTime" BO_ 973 500;
BA_ "GenMsgCycleTimeFast" BO_ 973 0;
BA_ "GenMsgSendType" BO_ 973 0;
BA_ "VFrameFormat" BO_ 973 14;
BA_ "CANFD_BRS" BO_ 973 1;
BA_ "GenMsgCycleTime" BO_ 973 500;
BA_ "GenMsgCycleTimeFast" BO_ 973 0;
BA_ "GenMsgSendType" BO_ 973 0;
BA_ "VFrameFormat" BO_ 973 14;
BA_ "CANFD_BRS" BO_ 973 1;
BA_ "GenMsgCycleTime" BO_ 973 500;
BA_ "GenMsgCycleTimeFast" BO_ 973 0;
BA_ "GenMsgSendType" BO_ 973 0;
BA_ "VFrameFormat" BO_ 973 14;
BA_ "CANFD_BRS" BO_ 973 1;
BA_ "GenMsgCycleTime" BO_ 973 500;
BA_ "GenMsgCycleTimeFast" BO_ 973 0;
BA_ "GenMsgSendType" BO_ 973 0;
BA_ "VFrameFormat" BO_ 973 14;
BA_ "CANFD_BRS" BO_ 973 1;
BA_ "GenMsgCycleTime" BO_ 973 500;
BA_ "GenMsgCycleTimeFast" BO_ 973 0;
BA_ "GenMsgSendType" BO_ 973 0;
BA_ "VFrameFormat" BO_ 973 14;
BA_ "CANFD_BRS" BO_ 973 1;
BA_ "GenMsgCycleTime" BO_ 973 500;
BA_ "GenMsgCycleTimeFast" BO_ 973 0;
BA_ "GenMsgSendType" BO_ 973 0;
BA_ "VFrameFormat" BO_ 973 14;
BA_ "CANFD_BRS" BO_ 973 1;
BA_ "GenMsgCycleTime" BO_ 973 500;
BA_ "GenMsgCycleTimeFast" BO_ 973 0;
BA_ "GenMsgSendType" BO_ 973 0;
BA_ "VFrameFormat" BO_ 973 14;
BA_ "CANFD_BRS" BO_ 973 1;
BA_ "GenMsgCycleTime" BO_ 973 500;
BA_ "GenMsgCycleTimeFast" BO_ 973 0;
BA_ "GenMsgSendType" BO_ 973 0;
BA_ "VFrameFormat" BO_ 973 14;
BA_ "CANFD_BRS" BO_ 973 1;
BA_ "GenMsgCycleTime" BO_ 973 500;
BA_ "GenMsgCycleTimeFast" BO_ 973 0;
BA_ "GenMsgSendType" BO_ 973 0;
BA_ "VFrameFormat" BO_ 973 14;
BA_ "CANFD_BRS" BO_ 973 1;
BA_ "GenMsgCycleTime" BO_ 973 500;
BA_ "GenMsgCycleTimeFast" BO_ 973 0;
BA_ "GenMsgSendType" BO_ 973 0;
BA_ "VFrameFormat" BO_ 973 14;
BA_ "CANFD_BRS" BO_ 973 1;
BA_ "GenMsgCycleTime" BO_ 973 500;
BA_ "GenMsgCycleTimeFast" BO_ 973 0;
BA_ "GenMsgSendType" BO_ 973 0;
BA_ "VFrameFormat" BO_ 973 14;
BA_ "CANFD_BRS" BO_ 973 1;
BA_ "GenMsgCycleTime" BO_ 973 500;
BA_ "GenMsgCycleTimeFast" BO_ 973 0;
BA_ "GenMsgSendType" BO_ 973 0;
BA_ "VFrameFormat" BO_ 973 14;
BA_ "CANFD_BRS" BO_ 973 1;
BA_ "GenMsgCycleTime" BO_ 973 500;
BA_ "GenMsgCycleTimeFast" BO_ 973 0;
BA_ "GenMsgSendType" BO_ 973 0;
BA_ "VFrameFormat" BO_ 973 14;
BA_ "CANFD_BRS" BO_ 973 1;
BA_ "GenMsgCycleTime" BO_ 973 500;
BA_ "GenMsgCycleTimeFast" BO_ 973 0;
BA_ "GenMsgSendType" BO_ 973 0;
BA_ "VFrameFormat" BO_ 973 14;
BA_ "CANFD_BRS" BO_ 973 1;
BA_ "GenMsgCycleTime" BO_ 973 500;
BA_ "GenMsgCycleTimeFast" BO_ 973 0;
BA_ "GenMsgSendType" BO_ 973 0;
BA_ "VFrameFormat" BO_ 973 14;
BA_ "CANFD_BRS" BO_ 973 1;
BA_ "GenMsgCycleTime" BO_ 973 500;
BA_ "GenMsgCycleTimeFast" BO_ 973 0;
BA_ "GenMsgSendType" BO_ 973 0;
BA_ "VFrameFormat" BO_ 973 14;
BA_ "CANFD_BRS" BO_ 973 1;
BA_ "GenMsgCycleTime" BO_ 973 500;
BA_ "GenMsgCycleTimeFast" BO_ 973 0;
BA_ "GenMsgSendType" BO_ 973 0;
BA_ "VFrameFormat" BO_ 973 14;
BA_ "CANFD_BRS" BO_ 973 1;
BA_ "GenMsgCycleTime" BO_ 973 500;
BA_ "GenMsgCycleTimeFast" BO_ 973 0;
BA_ "GenMsgSendType" BO_ 973 0;
BA_ "VFrameFormat" BO_ 973 14;
BA_ "CANFD_BRS" BO_ 973 1;
BA_ "GenMsgCycleTime" BO_ 973 500;
BA_ "GenMsgCycleTimeFast" BO_ 973 0;
BA_ "GenMsgSendType" BO_ 973 0;
BA_ "VFrameFormat" BO_ 973 14;
BA_ "CANFD_BRS" BO_ 973 1;
BA_ "GenMsgCycleTime" BO_ 973 500;
BA_ "GenMsgCycleTimeFast" BO_ 973 0;
BA_ "GenMsgSendType" BO_ 973 0;
BA_ "VFrameFormat" BO_ 973 14;
BA_ "CANFD_BRS" BO_ 973 1;
BA_ "GenMsgCycleTime" BO_ 973 500;
BA_ "GenMsgCycleTimeFast" BO_ 973 0;
BA_ "GenMsgSendType" BO_ 973 0;
BA_ "VFrameFormat" BO_ 973 14;
BA_ "CANFD_BRS" BO_ 973 1;
BA_ "GenMsgCycleTime" BO_ 973 500;
BA_ "GenMsgCycleTimeFast" BO_ 973 0;
BA_ "GenMsgSendType" BO_ 973 0;
BA_ "VFrameFormat" BO_ 973 14;
BA_ "CANFD_BRS" BO_ 973 1;
BA_ "GenMsgCycleTime" BO_ 973 500;
BA_ "GenMsgCycleTimeFast" BO_ 973 0;
BA_ "GenMsgSendType" BO_ 973 0;
BA_ "VFrameFormat" BO_ 973 14;
BA_ "CANFD_BRS" BO_ 973 1;
BA_ "GenMsgCycleTime" BO_ 973 500;
BA_ "GenMsgCycleTimeFast" BO_ 973 0;
BA_ "GenMsgSendType" BO_ 973 0;
BA_ "VFrameFormat" BO_ 973 14;
BA_ "CANFD_BRS" BO_ 973 1;
BA_ "GenMsgCycleTime" BO_ 973 500;
BA_ "GenMsgCycleTimeFast" BO_ 973 0;
BA_ "GenMsgSendType" BO_ 973 0;
BA_ "VFrameFormat" BO_ 973 14;
BA_ "CANFD_BRS" BO_ 973 1;

BA_ "EventCommandSignal" SG_ 1236 LBMS_DTCCode 1;
BA_ "GatewayedSignals" SG_ 1236 LBMS_DTCCode 0;
BA_ "GenSigInactiveValue" SG_ 1236 LBMS_DTCCode 0;
BA_ "GenSigInvalidValue" SG_ 1236 LBMS_DTCCode 0;
BA_ "GenSigSendType" SG_ 1236 LBMS_DTCCode 0;
BA_ "GenSigStartValue" SG_ 1236 LBMS_DTCCode 0;
BA_ "GenSigTimeoutValue" SG_ 1236 LBMS_DTCCode 0;
BA_ "Remark" SG_ 1236 LBMS_DTCCode "";
BA_ "EventCommandSignal" SG_ 998 VCU_LVBatFillSt_1 0;
BA_ "GatewayedSignals" SG_ 998 VCU_LVBatFillSt_1 0;
BA_ "GenSigInactiveValue" SG_ 998 VCU_LVBatFillSt_1 0;
BA_ "GenSigInvalidValue" SG_ 998 VCU_LVBatFillSt_1 0;
BA_ "GenSigSendType" SG_ 998 VCU_LVBatFillSt_1 1;
BA_ "GenSigStartValue" SG_ 998 VCU_LVBatFillSt_1 0;
BA_ "GenSigTimeoutValue" SG_ 998 VCU_LVBatFillSt_1 0;
BA_ "Remark" SG_ 998 VCU_LVBatFillSt_1 "";
BA_ "EventCommandSignal" SG_ 616 UMM_UsageModeSt 0;
BA_ "GatewayedSignals" SG_ 616 UMM_UsageModeSt 0;
BA_ "GenSigInactiveValue" SG_ 616 UMM_UsageModeSt 0;
BA_ "GenSigInvalidValue" SG_ 616 UMM_UsageModeSt 0;
BA_ "GenSigSendType" SG_ 616 UMM_UsageModeSt 1;
BA_ "GenSigStartValue" SG_ 616 UMM_UsageModeSt 7;
BA_ "GenSigTimeoutValue" SG_ 616 UMM_UsageModeSt 0;
BA_ "Remark" SG_ 616 UMM_UsageModeSt "";
BA_ "EventCommandSignal" SG_ 616 VMM_VehModeSt 0;
BA_ "GatewayedSignals" SG_ 616 VMM_VehModeSt 0;
BA_ "GenSigInactiveValue" SG_ 616 VMM_VehModeSt 0;
BA_ "GenSigInvalidValue" SG_ 616 VMM_VehModeSt 15;
BA_ "GenSigSendType" SG_ 616 VMM_VehModeSt 1;
BA_ "GenSigStartValue" SG_ 616 VMM_VehModeSt 15;
BA_ "GenSigTimeoutValue" SG_ 616 VMM_VehModeSt 15;
BA_ "Remark" SG_ 616 VMM_VehModeSt "";
BA_ "EventCommandSignal" SG_ 616 VMM_OTAModeSt 0;
BA_ "GatewayedSignals" SG_ 616 VMM_OTAModeSt 0;
BA_ "GenSigInactiveValue" SG_ 616 VMM_OTAModeSt 0;
BA_ "GenSigInvalidValue" SG_ 616 VMM_OTAModeSt 2;
BA_ "GenSigSendType" SG_ 616 VMM_OTAModeSt 1;
BA_ "GenSigStartValue" SG_ 616 VMM_OTAModeSt 0;
BA_ "GenSigTimeoutValue" SG_ 616 VMM_OTAModeSt 0;
BA_ "Remark" SG_ 616 VMM_OTAModeSt "";
BA_ "EventCommandSignal" SG_ 616 Time_Year 0;
BA_ "GatewayedSignals" SG_ 616 Time_Year 0;
BA_ "GenSigInactiveValue" SG_ 616 Time_Year 0;
BA_ "GenSigInvalidValue" SG_ 616 Time_Year 0;
BA_ "GenSigSendType" SG_ 616 Time_Year 1;
BA_ "GenSigStartValue" SG_ 616 Time_Year 0;
BA_ "GenSigTimeoutValue" SG_ 616 Time_Year 0;
BA_ "Remark" SG_ 616 Time_Year "";
BA_ "EventCommandSignal" SG_ 616 Time_Month 0;
BA_ "GatewayedSignals" SG_ 616 Time_Month 0;
BA_ "GenSigInactiveValue" SG_ 616 Time_Month 0;
BA_ "GenSigInvalidValue" SG_ 616 Time_Month 0;
BA_ "GenSigSendType" SG_ 616 Time_Month 1;
BA_ "GenSigStartValue" SG_ 616 Time_Month 0;
BA_ "GenSigTimeoutValue" SG_ 616 Time_Month 0;
BA_ "Remark" SG_ 616 Time_Month "";
BA_ "EventCommandSignal" SG_ 616 Time_Day 0;
BA_ "GatewayedSignals" SG_ 616 Time_Day 0;
BA_ "GenSigInactiveValue" SG_ 616 Time_Day 0;
BA_ "GenSigInvalidValue" SG_ 616 Time_Day 0;
BA_ "GenSigSendType" SG_ 616 Time_Day 1;
BA_ "GenSigStartValue" SG_ 616 Time_Day 1;
BA_ "GenSigTimeoutValue" SG_ 616 Time_Day 0;
BA_ "Remark" SG_ 616 Time_Day "";
BA_ "EventCommandSignal" SG_ 616 Time_Hour 0;
BA_ "GatewayedSignals" SG_ 616 Time_Hour 0;
BA_ "GenSigInactiveValue" SG_ 616 Time_Hour 0;
BA_ "GenSigInvalidValue" SG_ 616 Time_Hour 0;
BA_ "GenSigSendType" SG_ 616 Time_Hour 1;
BA_ "GenSigStartValue" SG_ 616 Time_Hour 1;
BA_ "GenSigTimeoutValue" SG_ 616 Time_Hour 0;
BA_ "Remark" SG_ 616 Time_Hour "";
BA_ "EventCommandSignal" SG_ 616 Time_Min 0;
BA_ "GatewayedSignals" SG_ 616 Time_Min 0;
BA_ "GenSigInactiveValue" SG_ 616 Time_Min 0;
BA_ "GenSigInvalidValue" SG_ 616 Time_Min 0;
BA_ "GenSigSendType" SG_ 616 Time_Min 1;
BA_ "GenSigStartValue" SG_ 616 Time_Min 1;
BA_ "GenSigTimeoutValue" SG_ 616 Time_Min 0;
BA_ "Remark" SG_ 616 Time_Min "";
BA_ "EventCommandSignal" SG_ 616 Time_Sec 0;
BA_ "GatewayedSignals" SG_ 616 Time_Sec 0;
BA_ "GenSigInactiveValue" SG_ 616 Time_Sec 0;
BA_ "GenSigInvalidValue" SG_ 616 Time_Sec 0;
BA_ "GenSigSendType" SG_ 616 Time_Sec 1;
BA_ "GenSigStartValue" SG_ 616 Time_Sec 1;
BA_ "GenSigTimeoutValue" SG_ 616 Time_Sec 0;
BA_ "Remark" SG_ 616 Time_Sec "";
BA_ "EventCommandSignal" SG_ 1359 CCU_NMNodeAddress 0;
BA_ "GatewayedSignals" SG_ 1359 CCU_NMNodeAddress 0;
BA_ "GenSigInactiveValue" SG_ 1359 CCU_NMNodeAddress 0;
BA_ "GenSigInvalidValue" SG_ 1359 CCU_NMNodeAddress 0;
BA_ "GenSigSendType" SG_ 1359 CCU_NMNodeAddress 1;
BA_ "GenSigStartValue" SG_ 1359 CCU_NMNodeAddress 79;
BA_ "GenSigTimeoutValue" SG_ 1359 CCU_NMNodeAddress 0;
BA_ "Remark" SG_ 1359 CCU_NMNodeAddress "";
BA_ "EventCommandSignal" SG_ 1359 CCU_NMCBV 0;
BA_ "GatewayedSignals" SG_ 1359 CCU_NMCBV 0;
BA_ "GenSigInactiveValue" SG_ 1359 CCU_NMCBV 0;
BA_ "GenSigInvalidValue" SG_ 1359 CCU_NMCBV 0;
BA_ "GenSigSendType" SG_ 1359 CCU_NMCBV 1;
BA_ "GenSigStartValue" SG_ 1359 CCU_NMCBV 0;
BA_ "GenSigTimeoutValue" SG_ 1359 CCU_NMCBV 0;
BA_ "Remark" SG_ 1359 CCU_NMCBV "";
BA_ "EventCommandSignal" SG_ 1359 CCU_NMWakeupOrigin 0;
BA_ "GatewayedSignals" SG_ 1359 CCU_NMWakeupOrigin 0;
BA_ "GenSigInactiveValue" SG_ 1359 CCU_NMWakeupOrigin 0;
BA_ "GenSigInvalidValue" SG_ 1359 CCU_NMWakeupOrigin 0;
BA_ "GenSigSendType" SG_ 1359 CCU_NMWakeupOrigin 1;
BA_ "GenSigStartValue" SG_ 1359 CCU_NMWakeupOrigin 0;
BA_ "GenSigTimeoutValue" SG_ 1359 CCU_NMWakeupOrigin 0;
BA_ "Remark" SG_ 1359 CCU_NMWakeupOrigin "";
BA_ "EventCommandSignal" SG_ 1359 CCU_PNCInformation0 0;
BA_ "GatewayedSignals" SG_ 1359 CCU_PNCInformation0 0;
BA_ "GenSigInactiveValue" SG_ 1359 CCU_PNCInformation0 0;
BA_ "GenSigInvalidValue" SG_ 1359 CCU_PNCInformation0 0;
BA_ "GenSigSendType" SG_ 1359 CCU_PNCInformation0 1;
BA_ "GenSigStartValue" SG_ 1359 CCU_PNCInformation0 0;
BA_ "GenSigTimeoutValue" SG_ 1359 CCU_PNCInformation0 0;
BA_ "Remark" SG_ 1359 CCU_PNCInformation0 "";
BA_ "EventCommandSignal" SG_ 1359 CCU_PNCInformation1 0;
BA_ "GatewayedSignals" SG_ 1359 CCU_PNCInformation1 0;
BA_ "GenSigInactiveValue" SG_ 1359 CCU_PNCInformation1 0;
BA_ "GenSigInvalidValue" SG_ 1359 CCU_PNCInformation1 0;
BA_ "GenSigSendType" SG_ 1359 CCU_PNCInformation1 1;
BA_ "GenSigStartValue" SG_ 1359 CCU_PNCInformation1 0;
BA_ "GenSigTimeoutValue" SG_ 1359 CCU_PNCInformation1 0;
BA_ "Remark" SG_ 1359 CCU_PNCInformation1 "";
BA_ "EventCommandSignal" SG_ 1359 CCU_PNCInformation2 0;
BA_ "GatewayedSignals" SG_ 1359 CCU_PNCInformation2 0;
BA_ "GenSigInactiveValue" SG_ 1359 CCU_PNCInformation2 0;
BA_ "GenSigInvalidValue" SG_ 1359 CCU_PNCInformation2 0;
BA_ "GenSigSendType" SG_ 1359 CCU_PNCInformation2 1;
BA_ "GenSigStartValue" SG_ 1359 CCU_PNCInformation2 0;
BA_ "GenSigTimeoutValue" SG_ 1359 CCU_PNCInformation2 0;
BA_ "Remark" SG_ 1359 CCU_PNCInformation2 "";
BA_ "EventCommandSignal" SG_ 352 BCS_VehSpd 0;
BA_ "GatewayedSignals" SG_ 352 BCS_VehSpd 0;
BA_ "GenSigInactiveValue" SG_ 352 BCS_VehSpd 0;
BA_ "GenSigInvalidValue" SG_ 352 BCS_VehSpd 0;
BA_ "GenSigSendType" SG_ 352 BCS_VehSpd 1;
BA_ "GenSigStartValue" SG_ 352 BCS_VehSpd 0;
BA_ "GenSigTimeoutValue" SG_ 352 BCS_VehSpd 0;
BA_ "Remark" SG_ 352 BCS_VehSpd "";
BA_ "EventCommandSignal" SG_ 352 BCS_VehSpdVD 0;
BA_ "GatewayedSignals" SG_ 352 BCS_VehSpdVD 0;
BA_ "GenSigInactiveValue" SG_ 352 BCS_VehSpdVD 0;
BA_ "GenSigInvalidValue" SG_ 352 BCS_VehSpdVD 0;
BA_ "GenSigSendType" SG_ 352 BCS_VehSpdVD 1;
BA_ "GenSigStartValue" SG_ 352 BCS_VehSpdVD 0;
BA_ "GenSigTimeoutValue" SG_ 352 BCS_VehSpdVD 0;
BA_ "Remark" SG_ 352 BCS_VehSpdVD "";
BA_ "EventCommandSignal" SG_ 884 CCU_GwMsg_3_CRC 0;
BA_ "GatewayedSignals" SG_ 884 CCU_GwMsg_3_CRC 0;
BA_ "GenSigInactiveValue" SG_ 884 CCU_GwMsg_3_CRC 0;
BA_ "GenSigInvalidValue" SG_ 884 CCU_GwMsg_3_CRC 0;
BA_ "GenSigSendType" SG_ 884 CCU_GwMsg_3_CRC 1;
BA_ "GenSigStartValue" SG_ 884 CCU_GwMsg_3_CRC 0;
BA_ "GenSigTimeoutValue" SG_ 884 CCU_GwMsg_3_CRC 0;
BA_ "Remark" SG_ 884 CCU_GwMsg_3_CRC "";
BA_ "EventCommandSignal" SG_ 884 CCU_GwMsg_3_Counter 0;
BA_ "GatewayedSignals" SG_ 884 CCU_GwMsg_3_Counter 0;
BA_ "GenSigInactiveValue" SG_ 884 CCU_GwMsg_3_Counter 0;
BA_ "GenSigInvalidValue" SG_ 884 CCU_GwMsg_3_Counter 0;
BA_ "GenSigSendType" SG_ 884 CCU_GwMsg_3_Counter 1;
BA_ "GenSigStartValue" SG_ 884 CCU_GwMsg_3_Counter 0;
BA_ "GenSigTimeoutValue" SG_ 884 CCU_GwMsg_3_Counter 0;
BA_ "Remark" SG_ 884 CCU_GwMsg_3_Counter "";
BA_ "EventCommandSignal" SG_ 884 LCK_FrontLeftDoorHandlePosition 0;
BA_ "GatewayedSignals" SG_ 884 LCK_FrontLeftDoorHandlePosition 0;
BA_ "GenSigInactiveValue" SG_ 884 LCK_FrontLeftDoorHandlePosition 0;
BA_ "GenSigInvalidValue" SG_ 884 LCK_FrontLeftDoorHandlePosition 255;
BA_ "GenSigSendType" SG_ 884 LCK_FrontLeftDoorHandlePosition 1;
BA_ "GenSigStartValue" SG_ 884 LCK_FrontLeftDoorHandlePosition 0;
BA_ "GenSigTimeoutValue" SG_ 884 LCK_FrontLeftDoorHandlePosition 0;
BA_ "Remark" SG_ 884 LCK_FrontLeftDoorHandlePosition "";
BA_ "EventCommandSignal" SG_ 884 LCK_FrontLeftDoorLockAction 0;
BA_ "GatewayedSignals" SG_ 884 LCK_FrontLeftDoorLockAction 0;
BA_ "GenSigInactiveValue" SG_ 884 LCK_FrontLeftDoorLockAction 0;
BA_ "GenSigInvalidValue" SG_ 884 LCK_FrontLeftDoorLockAction 0;
BA_ "GenSigSendType" SG_ 884 LCK_FrontLeftDoorLockAction 1;
BA_ "GenSigStartValue" SG_ 884 LCK_FrontLeftDoorLockAction 0;
BA_ "GenSigTimeoutValue" SG_ 884 LCK_FrontLeftDoorLockAction 0;
BA_ "Remark" SG_ 884 LCK_FrontLeftDoorLockAction "";
BA_ "EventCommandSignal" SG_ 884 LCK_FrontLeftDoorHandleAction 0;
BA_ "GatewayedSignals" SG_ 884 LCK_FrontLeftDoorHandleAction 0;
BA_ "GenSigInactiveValue" SG_ 884 LCK_FrontLeftDoorHandleAction 0;
BA_ "GenSigInvalidValue" SG_ 884 LCK_FrontLeftDoorHandleAction 0;
BA_ "GenSigSendType" SG_ 884 LCK_FrontLeftDoorHandleAction 1;
BA_ "GenSigStartValue" SG_ 884 LCK_FrontLeftDoorHandleAction 0;
BA_ "GenSigTimeoutValue" SG_ 884 LCK_FrontLeftDoorHandleAction 0;
BA_ "Remark" SG_ 884 LCK_FrontLeftDoorHandleAction "";
BA_ "EventCommandSignal" SG_ 884 LCK_FrontLeftPowerDoorAction 0;
BA_ "GatewayedSignals" SG_ 884 LCK_FrontLeftPowerDoorAction 0;
BA_ "GenSigInactiveValue" SG_ 884 LCK_FrontLeftPowerDoorAction 0;
BA_ "GenSigInvalidValue" SG_ 884 LCK_FrontLeftPowerDoorAction 0;
BA_ "GenSigSendType" SG_ 884 LCK_FrontLeftPowerDoorAction 1;
BA_ "GenSigStartValue" SG_ 884 LCK_FrontLeftPowerDoorAction 0;
BA_ "GenSigTimeoutValue" SG_ 884 LCK_FrontLeftPowerDoorAction 0;
BA_ "Remark" SG_ 884 LCK_FrontLeftPowerDoorAction "";
BA_ "EventCommandSignal" SG_ 884 LCK_FrontRightDoorHandlePosition 0;
BA_ "GatewayedSignals" SG_ 884 LCK_FrontRightDoorHandlePosition 0;
BA_ "GenSigInactiveValue" SG_ 884 LCK_FrontRightDoorHandlePosition 0;
BA_ "GenSigInvalidValue" SG_ 884 LCK_FrontRightDoorHandlePosition 255;
BA_ "GenSigSendType" SG_ 884 LCK_FrontRightDoorHandlePosition 1;
BA_ "GenSigStartValue" SG_ 884 LCK_FrontRightDoorHandlePosition 0;
BA_ "GenSigTimeoutValue" SG_ 884 LCK_FrontRightDoorHandlePosition 0;
BA_ "Remark" SG_ 884 LCK_FrontRightDoorHandlePosition "";
BA_ "EventCommandSignal" SG_ 884 LCK_FrontRightDoorLockAction 0;
BA_ "GatewayedSignals" SG_ 884 LCK_FrontRightDoorLockAction 0;
BA_ "GenSigInactiveValue" SG_ 884 LCK_FrontRightDoorLockAction 0;
BA_ "GenSigInvalidValue" SG_ 884 LCK_FrontRightDoorLockAction 0;
BA_ "GenSigSendType" SG_ 884 LCK_FrontRightDoorLockAction 1;
BA_ "GenSigStartValue" SG_ 884 LCK_FrontRightDoorLockAction 0;
BA_ "GenSigTimeoutValue" SG_ 884 LCK_FrontRightDoorLockAction 0;
BA_ "Remark" SG_ 884 LCK_FrontRightDoorLockAction "";
BA_ "EventCommandSignal" SG_ 884 LCK_FrontRightDoorHandleAction 0;
BA_ "GatewayedSignals" SG_ 884 LCK_FrontRightDoorHandleAction 0;
BA_ "GenSigInactiveValue" SG_ 884 LCK_FrontRightDoorHandleAction 0;
BA_ "GenSigInvalidValue" SG_ 884 LCK_FrontRightDoorHandleAction 0;
BA_ "GenSigSendType" SG_ 884 LCK_FrontRightDoorHandleAction 1;
BA_ "GenSigStartValue" SG_ 884 LCK_FrontRightDoorHandleAction 0;
BA_ "GenSigTimeoutValue" SG_ 884 LCK_FrontRightDoorHandleAction 0;
BA_ "Remark" SG_ 884 LCK_FrontRightDoorHandleAction "";
BA_ "EventCommandSignal" SG_ 884 LCK_FrontRightPowerDoorAction 0;
BA_ "GatewayedSignals" SG_ 884 LCK_FrontRightPowerDoorAction 0;
BA_ "GenSigInactiveValue" SG_ 884 LCK_FrontRightPowerDoorAction 0;
BA_ "GenSigInvalidValue" SG_ 884 LCK_FrontRightPowerDoorAction 0;
BA_ "GenSigSendType" SG_ 884 LCK_FrontRightPowerDoorAction 1;
BA_ "GenSigStartValue" SG_ 884 LCK_FrontRightPowerDoorAction 0;
BA_ "GenSigTimeoutValue" SG_ 884 LCK_FrontRightPowerDoorAction 0;
BA_ "Remark" SG_ 884 LCK_FrontRightPowerDoorAction "";
BA_ "EventCommandSignal" SG_ 884 IPDS_BAT1PowerSt 0;
BA_ "GatewayedSignals" SG_ 884 IPDS_BAT1PowerSt 0;
BA_ "GenSigInactiveValue" SG_ 884 IPDS_BAT1PowerSt 0;
BA_ "GenSigInvalidValue" SG_ 884 IPDS_BAT1PowerSt 0;
BA_ "GenSigSendType" SG_ 884 IPDS_BAT1PowerSt 1;
BA_ "GenSigStartValue" SG_ 884 IPDS_BAT1PowerSt 1;
BA_ "GenSigTimeoutValue" SG_ 884 IPDS_BAT1PowerSt 0;
BA_ "Remark" SG_ 884 IPDS_BAT1PowerSt "";
BA_ "EventCommandSignal" SG_ 884 IPDS_BAT2PowerSt 0;
BA_ "GatewayedSignals" SG_ 884 IPDS_BAT2PowerSt 0;
BA_ "GenSigInactiveValue" SG_ 884 IPDS_BAT2PowerSt 0;
BA_ "GenSigInvalidValue" SG_ 884 IPDS_BAT2PowerSt 0;
BA_ "GenSigSendType" SG_ 884 IPDS_BAT2PowerSt 1;
BA_ "GenSigStartValue" SG_ 884 IPDS_BAT2PowerSt 1;
BA_ "GenSigTimeoutValue" SG_ 884 IPDS_BAT2PowerSt 0;
BA_ "Remark" SG_ 884 IPDS_BAT2PowerSt "";
BA_ "EventCommandSignal" SG_ 884 IPDS_DCDC2PowerSt 0;
BA_ "GatewayedSignals" SG_ 884 IPDS_DCDC2PowerSt 0;
BA_ "GenSigInactiveValue" SG_ 884 IPDS_DCDC2PowerSt 0;
BA_ "GenSigInvalidValue" SG_ 884 IPDS_DCDC2PowerSt 0;
BA_ "GenSigSendType" SG_ 884 IPDS_DCDC2PowerSt 1;
BA_ "GenSigStartValue" SG_ 884 IPDS_DCDC2PowerSt 1;
BA_ "GenSigTimeoutValue" SG_ 884 IPDS_DCDC2PowerSt 0;
BA_ "Remark" SG_ 884 IPDS_DCDC2PowerSt "";
BA_ "EventCommandSignal" SG_ 884 IPDS_GridIsoPowerSt 0;
BA_ "GatewayedSignals" SG_ 884 IPDS_GridIsoPowerSt 0;
BA_ "GenSigInactiveValue" SG_ 884 IPDS_GridIsoPowerSt 0;
BA_ "GenSigInvalidValue" SG_ 884 IPDS_GridIsoPowerSt 0;
BA_ "GenSigSendType" SG_ 884 IPDS_GridIsoPowerSt 1;
BA_ "GenSigStartValue" SG_ 884 IPDS_GridIsoPowerSt 1;
BA_ "GenSigTimeoutValue" SG_ 884 IPDS_GridIsoPowerSt 0;
BA_ "Remark" SG_ 884 IPDS_GridIsoPowerSt "";
BA_ "EventCommandSignal" SG_ 884 IPS_DCDCDiagErrCode 0;
BA_ "GatewayedSignals" SG_ 884 IPS_DCDCDiagErrCode 0;
BA_ "GenSigInactiveValue" SG_ 884 IPS_DCDCDiagErrCode 0;
BA_ "GenSigInvalidValue" SG_ 884 IPS_DCDCDiagErrCode 0;
BA_ "GenSigSendType" SG_ 884 IPS_DCDCDiagErrCode 1;
BA_ "GenSigStartValue" SG_ 884 IPS_DCDCDiagErrCode 0;
BA_ "GenSigTimeoutValue" SG_ 884 IPS_DCDCDiagErrCode 0;
BA_ "Remark" SG_ 884 IPS_DCDCDiagErrCode "";
BA_ "EventCommandSignal" SG_ 884 IPS_DCDCCurrLvAct 0;
BA_ "GatewayedSignals" SG_ 884 IPS_DCDCCurrLvAct 0;
BA_ "GenSigInactiveValue" SG_ 884 IPS_DCDCCurrLvAct 0;
BA_ "GenSigInvalidValue" SG_ 884 IPS_DCDCCurrLvAct 0;
BA_ "GenSigSendType" SG_ 884 IPS_DCDCCurrLvAct 1;
BA_ "GenSigStartValue" SG_ 884 IPS_DCDCCurrLvAct 0;
BA_ "GenSigTimeoutValue" SG_ 884 IPS_DCDCCurrLvAct 0;
BA_ "Remark" SG_ 884 IPS_DCDCCurrLvAct "";
BA_ "EventCommandSignal" SG_ 514 CCU_GwMsg_2_CRC 0;
BA_ "GatewayedSignals" SG_ 514 CCU_GwMsg_2_CRC 0;
BA_ "GenSigInactiveValue" SG_ 514 CCU_GwMsg_2_CRC 0;
BA_ "GenSigInvalidValue" SG_ 514 CCU_GwMsg_2_CRC 0;
BA_ "GenSigSendType" SG_ 514 CCU_GwMsg_2_CRC 1;
BA_ "GenSigStartValue" SG_ 514 CCU_GwMsg_2_CRC 0;
BA_ "GenSigTimeoutValue" SG_ 514 CCU_GwMsg_2_CRC 0;
BA_ "Remark" SG_ 514 CCU_GwMsg_2_CRC "";
BA_ "EventCommandSignal" SG_ 514 CCU_GwMsg_2_Counter 0;
BA_ "GatewayedSignals" SG_ 514 CCU_GwMsg_2_Counter 0;
BA_ "GenSigInactiveValue" SG_ 514 CCU_GwMsg_2_Counter 0;
BA_ "GenSigInvalidValue" SG_ 514 CCU_GwMsg_2_Counter 0;
BA_ "GenSigSendType" SG_ 514 CCU_GwMsg_2_Counter 1;
BA_ "GenSigStartValue" SG_ 514 CCU_GwMsg_2_Counter 0;
BA_ "GenSigTimeoutValue" SG_ 514 CCU_GwMsg_2_Counter 0;
BA_ "Remark" SG_ 514 CCU_GwMsg_2_Counter "";
BA_ "EventCommandSignal" SG_ 514 SRS_CrashOutputSt 0;
BA_ "GatewayedSignals" SG_ 514 SRS_CrashOutputSt 0;
BA_ "GenSigInactiveValue" SG_ 514 SRS_CrashOutputSt 0;
BA_ "GenSigInvalidValue" SG_ 514 SRS_CrashOutputSt 0;
BA_ "GenSigSendType" SG_ 514 SRS_CrashOutputSt 1;
BA_ "GenSigStartValue" SG_ 514 SRS_CrashOutputSt 0;
BA_ "GenSigTimeoutValue" SG_ 514 SRS_CrashOutputSt 0;
BA_ "Remark" SG_ 514 SRS_CrashOutputSt "";
BA_ "EventCommandSignal" SG_ 514 BMS_HVBattSt 0;
BA_ "GatewayedSignals" SG_ 514 BMS_HVBattSt 0;
BA_ "GenSigInactiveValue" SG_ 514 BMS_HVBattSt 0;
BA_ "GenSigInvalidValue" SG_ 514 BMS_HVBattSt 0;
BA_ "GenSigSendType" SG_ 514 BMS_HVBattSt 1;
BA_ "GenSigStartValue" SG_ 514 BMS_HVBattSt 0;
BA_ "GenSigTimeoutValue" SG_ 514 BMS_HVBattSt 0;
BA_ "Remark" SG_ 514 BMS_HVBattSt "";
BA_ "EventCommandSignal" SG_ 909 LCK_FrontLeftDoorLockSt 0;
BA_ "GatewayedSignals" SG_ 909 LCK_FrontLeftDoorLockSt 0;
BA_ "GenSigInactiveValue" SG_ 909 LCK_FrontLeftDoorLockSt 0;
BA_ "GenSigInvalidValue" SG_ 909 LCK_FrontLeftDoorLockSt 0;
BA_ "GenSigSendType" SG_ 909 LCK_FrontLeftDoorLockSt 0;
BA_ "GenSigStartValue" SG_ 909 LCK_FrontLeftDoorLockSt 0;
BA_ "GenSigTimeoutValue" SG_ 909 LCK_FrontLeftDoorLockSt 0;
BA_ "Remark" SG_ 909 LCK_FrontLeftDoorLockSt "";
BA_ "EventCommandSignal" SG_ 909 LCK_FrontRightDoorLockSt 0;
BA_ "GatewayedSignals" SG_ 909 LCK_FrontRightDoorLockSt 0;
BA_ "GenSigInactiveValue" SG_ 909 LCK_FrontRightDoorLockSt 0;
BA_ "GenSigInvalidValue" SG_ 909 LCK_FrontRightDoorLockSt 0;
BA_ "GenSigSendType" SG_ 909 LCK_FrontRightDoorLockSt 0;
BA_ "GenSigStartValue" SG_ 909 LCK_FrontRightDoorLockSt 0;
BA_ "GenSigTimeoutValue" SG_ 909 LCK_FrontRightDoorLockSt 0;
BA_ "Remark" SG_ 909 LCK_FrontRightDoorLockSt "";
BA_ "EventCommandSignal" SG_ 909 LCK_RearLeftDoorLockSt 0;
BA_ "GatewayedSignals" SG_ 909 LCK_RearLeftDoorLockSt 0;
BA_ "GenSigInactiveValue" SG_ 909 LCK_RearLeftDoorLockSt 0;
BA_ "GenSigInvalidValue" SG_ 909 LCK_RearLeftDoorLockSt 0;
BA_ "GenSigSendType" SG_ 909 LCK_RearLeftDoorLockSt 0;
BA_ "GenSigStartValue" SG_ 909 LCK_RearLeftDoorLockSt 0;
BA_ "GenSigTimeoutValue" SG_ 909 LCK_RearLeftDoorLockSt 0;
BA_ "Remark" SG_ 909 LCK_RearLeftDoorLockSt "";
BA_ "EventCommandSignal" SG_ 909 LCK_RearRightDoorLockSt 0;
BA_ "GatewayedSignals" SG_ 909 LCK_RearRightDoorLockSt 0;
BA_ "GenSigInactiveValue" SG_ 909 LCK_RearRightDoorLockSt 0;
BA_ "GenSigInvalidValue" SG_ 909 LCK_RearRightDoorLockSt 0;
BA_ "GenSigSendType" SG_ 909 LCK_RearRightDoorLockSt 0;
BA_ "GenSigStartValue" SG_ 909 LCK_RearRightDoorLockSt 0;
BA_ "GenSigTimeoutValue" SG_ 909 LCK_RearRightDoorLockSt 0;
BA_ "Remark" SG_ 909 LCK_RearRightDoorLockSt "";
BA_ "EventCommandSignal" SG_ 909 LCK_RearLeftChildSaftyLockSt 0;
BA_ "GatewayedSignals" SG_ 909 LCK_RearLeftChildSaftyLockSt 0;
BA_ "GenSigInactiveValue" SG_ 909 LCK_RearLeftChildSaftyLockSt 0;
BA_ "GenSigInvalidValue" SG_ 909 LCK_RearLeftChildSaftyLockSt 0;
BA_ "GenSigSendType" SG_ 909 LCK_RearLeftChildSaftyLockSt 0;
BA_ "GenSigStartValue" SG_ 909 LCK_RearLeftChildSaftyLockSt 0;
BA_ "GenSigTimeoutValue" SG_ 909 LCK_RearLeftChildSaftyLockSt 0;
BA_ "Remark" SG_ 909 LCK_RearLeftChildSaftyLockSt "";
BA_ "EventCommandSignal" SG_ 909 LCK_RearRightChildSaftyLockSt 0;
BA_ "GatewayedSignals" SG_ 909 LCK_RearRightChildSaftyLockSt 0;
BA_ "GenSigInactiveValue" SG_ 909 LCK_RearRightChildSaftyLockSt 0;
BA_ "GenSigInvalidValue" SG_ 909 LCK_RearRightChildSaftyLockSt 0;
BA_ "GenSigSendType" SG_ 909 LCK_RearRightChildSaftyLockSt 0;
BA_ "GenSigStartValue" SG_ 909 LCK_RearRightChildSaftyLockSt 0;
BA_ "GenSigTimeoutValue" SG_ 909 LCK_RearRightChildSaftyLockSt 0;
BA_ "Remark" SG_ 909 LCK_RearRightChildSaftyLockSt "";
BA_ "EventCommandSignal" SG_ 909 IPS_DCDCVoltLvAct 0;
BA_ "GatewayedSignals" SG_ 909 IPS_DCDCVoltLvAct 0;
BA_ "GenSigInactiveValue" SG_ 909 IPS_DCDCVoltLvAct 0;
BA_ "GenSigInvalidValue" SG_ 909 IPS_DCDCVoltLvAct 0;
BA_ "GenSigSendType" SG_ 909 IPS_DCDCVoltLvAct 1;
BA_ "GenSigStartValue" SG_ 909 IPS_DCDCVoltLvAct 0;
BA_ "GenSigTimeoutValue" SG_ 909 IPS_DCDCVoltLvAct 0;
BA_ "Remark" SG_ 909 IPS_DCDCVoltLvAct "";
BA_ "EventCommandSignal" SG_ 909 BMS_ThermalRunawayErr 0;
BA_ "GatewayedSignals" SG_ 909 BMS_ThermalRunawayErr 0;
BA_ "GenSigInactiveValue" SG_ 909 BMS_ThermalRunawayErr 0;
BA_ "GenSigInvalidValue" SG_ 909 BMS_ThermalRunawayErr 0;
BA_ "GenSigSendType" SG_ 909 BMS_ThermalRunawayErr 1;
BA_ "GenSigStartValue" SG_ 909 BMS_ThermalRunawayErr 0;
BA_ "GenSigTimeoutValue" SG_ 909 BMS_ThermalRunawayErr 0;
BA_ "Remark" SG_ 909 BMS_ThermalRunawayErr "";
BA_ "EventCommandSignal" SG_ 909 IPS_DCDCModeSt 0;
BA_ "GatewayedSignals" SG_ 909 IPS_DCDCModeSt 0;
BA_ "GenSigInactiveValue" SG_ 909 IPS_DCDCModeSt 0;
BA_ "GenSigInvalidValue" SG_ 909 IPS_DCDCModeSt 0;
BA_ "GenSigSendType" SG_ 909 IPS_DCDCModeSt 1;
BA_ "GenSigStartValue" SG_ 909 IPS_DCDCModeSt 0;
BA_ "GenSigTimeoutValue" SG_ 909 IPS_DCDCModeSt 0;
BA_ "Remark" SG_ 909 IPS_DCDCModeSt "";
BA_ "EventCommandSignal" SG_ 792 ZCUT_2_CRC 0;
BA_ "GatewayedSignals" SG_ 792 ZCUT_2_CRC 0;
BA_ "GenSigInactiveValue" SG_ 792 ZCUT_2_CRC 0;
BA_ "GenSigInvalidValue" SG_ 792 ZCUT_2_CRC 0;
BA_ "GenSigSendType" SG_ 792 ZCUT_2_CRC 1;
BA_ "GenSigStartValue" SG_ 792 ZCUT_2_CRC 0;
BA_ "GenSigTimeoutValue" SG_ 792 ZCUT_2_CRC 0;
BA_ "Remark" SG_ 792 ZCUT_2_CRC "";
BA_ "EventCommandSignal" SG_ 792 ZCUT_2_Counter 0;
BA_ "GatewayedSignals" SG_ 792 ZCUT_2_Counter 0;
BA_ "GenSigInactiveValue" SG_ 792 ZCUT_2_Counter 0;
BA_ "GenSigInvalidValue" SG_ 792 ZCUT_2_Counter 0;
BA_ "GenSigSendType" SG_ 792 ZCUT_2_Counter 1;
BA_ "GenSigStartValue" SG_ 792 ZCUT_2_Counter 0;
BA_ "GenSigTimeoutValue" SG_ 792 ZCUT_2_Counter 0;
BA_ "Remark" SG_ 792 ZCUT_2_Counter "";
BA_ "EventCommandSignal" SG_ 792 LCK_RearLeftDoorLockAction 0;
BA_ "GatewayedSignals" SG_ 792 LCK_RearLeftDoorLockAction 0;
BA_ "GenSigInactiveValue" SG_ 792 LCK_RearLeftDoorLockAction 0;
BA_ "GenSigInvalidValue" SG_ 792 LCK_RearLeftDoorLockAction 0;
BA_ "GenSigSendType" SG_ 792 LCK_RearLeftDoorLockAction 1;
BA_ "GenSigStartValue" SG_ 792 LCK_RearLeftDoorLockAction 0;
BA_ "GenSigTimeoutValue" SG_ 792 LCK_RearLeftDoorLockAction 0;
BA_ "Remark" SG_ 792 LCK_RearLeftDoorLockAction "";
BA_ "EventCommandSignal" SG_ 792 LCK_RearLeftDoorHandleAction 0;
BA_ "GatewayedSignals" SG_ 792 LCK_RearLeftDoorHandleAction 0;
BA_ "GenSigInactiveValue" SG_ 792 LCK_RearLeftDoorHandleAction 0;
BA_ "GenSigInvalidValue" SG_ 792 LCK_RearLeftDoorHandleAction 0;
BA_ "GenSigSendType" SG_ 792 LCK_RearLeftDoorHandleAction 1;
BA_ "GenSigStartValue" SG_ 792 LCK_RearLeftDoorHandleAction 0;
BA_ "GenSigTimeoutValue" SG_ 792 LCK_RearLeftDoorHandleAction 0;
BA_ "Remark" SG_ 792 LCK_RearLeftDoorHandleAction "";
BA_ "EventCommandSignal" SG_ 792 LCK_RearLeftPowerDoorAction 0;
BA_ "GatewayedSignals" SG_ 792 LCK_RearLeftPowerDoorAction 0;
BA_ "GenSigInactiveValue" SG_ 792 LCK_RearLeftPowerDoorAction 0;
BA_ "GenSigInvalidValue" SG_ 792 LCK_RearLeftPowerDoorAction 0;
BA_ "GenSigSendType" SG_ 792 LCK_RearLeftPowerDoorAction 1;
BA_ "GenSigStartValue" SG_ 792 LCK_RearLeftPowerDoorAction 0;
BA_ "GenSigTimeoutValue" SG_ 792 LCK_RearLeftPowerDoorAction 0;
BA_ "Remark" SG_ 792 LCK_RearLeftPowerDoorAction "";
BA_ "EventCommandSignal" SG_ 792 LCK_RearLeftDoorHandlePosition 0;
BA_ "GatewayedSignals" SG_ 792 LCK_RearLeftDoorHandlePosition 0;
BA_ "GenSigInactiveValue" SG_ 792 LCK_RearLeftDoorHandlePosition 0;
BA_ "GenSigInvalidValue" SG_ 792 LCK_RearLeftDoorHandlePosition 255;
BA_ "GenSigSendType" SG_ 792 LCK_RearLeftDoorHandlePosition 1;
BA_ "GenSigStartValue" SG_ 792 LCK_RearLeftDoorHandlePosition 0;
BA_ "GenSigTimeoutValue" SG_ 792 LCK_RearLeftDoorHandlePosition 0;
BA_ "Remark" SG_ 792 LCK_RearLeftDoorHandlePosition "";
BA_ "EventCommandSignal" SG_ 792 LCK_RearLeftChildSaftyLockAction 0;
BA_ "GatewayedSignals" SG_ 792 LCK_RearLeftChildSaftyLockAction 0;
BA_ "GenSigInactiveValue" SG_ 792 LCK_RearLeftChildSaftyLockAction 0;
BA_ "GenSigInvalidValue" SG_ 792 LCK_RearLeftChildSaftyLockAction 0;
BA_ "GenSigSendType" SG_ 792 LCK_RearLeftChildSaftyLockAction 1;
BA_ "GenSigStartValue" SG_ 792 LCK_RearLeftChildSaftyLockAction 0;
BA_ "GenSigTimeoutValue" SG_ 792 LCK_RearLeftChildSaftyLockAction 0;
BA_ "Remark" SG_ 792 LCK_RearLeftChildSaftyLockAction "";
BA_ "EventCommandSignal" SG_ 792 LCK_RearRightDoorHandlePosition 0;
BA_ "GatewayedSignals" SG_ 792 LCK_RearRightDoorHandlePosition 0;
BA_ "GenSigInactiveValue" SG_ 792 LCK_RearRightDoorHandlePosition 0;
BA_ "GenSigInvalidValue" SG_ 792 LCK_RearRightDoorHandlePosition 255;
BA_ "GenSigSendType" SG_ 792 LCK_RearRightDoorHandlePosition 1;
BA_ "GenSigStartValue" SG_ 792 LCK_RearRightDoorHandlePosition 0;
BA_ "GenSigTimeoutValue" SG_ 792 LCK_RearRightDoorHandlePosition 0;
BA_ "Remark" SG_ 792 LCK_RearRightDoorHandlePosition "";
BA_ "EventCommandSignal" SG_ 792 LCK_RearRightDoorHandleAction 0;
BA_ "GatewayedSignals" SG_ 792 LCK_RearRightDoorHandleAction 0;
BA_ "GenSigInactiveValue" SG_ 792 LCK_RearRightDoorHandleAction 0;
BA_ "GenSigInvalidValue" SG_ 792 LCK_RearRightDoorHandleAction 0;
BA_ "GenSigSendType" SG_ 792 LCK_RearRightDoorHandleAction 1;
BA_ "GenSigStartValue" SG_ 792 LCK_RearRightDoorHandleAction 0;
BA_ "GenSigTimeoutValue" SG_ 792 LCK_RearRightDoorHandleAction 0;
BA_ "Remark" SG_ 792 LCK_RearRightDoorHandleAction "";
BA_ "EventCommandSignal" SG_ 792 LCK_RearRightPowerDoorAction 0;
BA_ "GatewayedSignals" SG_ 792 LCK_RearRightPowerDoorAction 0;
BA_ "GenSigInactiveValue" SG_ 792 LCK_RearRightPowerDoorAction 0;
BA_ "GenSigInvalidValue" SG_ 792 LCK_RearRightPowerDoorAction 0;
BA_ "GenSigSendType" SG_ 792 LCK_RearRightPowerDoorAction 1;
BA_ "GenSigStartValue" SG_ 792 LCK_RearRightPowerDoorAction 0;
BA_ "GenSigTimeoutValue" SG_ 792 LCK_RearRightPowerDoorAction 0;
BA_ "Remark" SG_ 792 LCK_RearRightPowerDoorAction "";
BA_ "EventCommandSignal" SG_ 792 LCK_RearRightChildSaftyLockAction 0;
BA_ "GatewayedSignals" SG_ 792 LCK_RearRightChildSaftyLockAction 0;
BA_ "GenSigInactiveValue" SG_ 792 LCK_RearRightChildSaftyLockAction 0;
BA_ "GenSigInvalidValue" SG_ 792 LCK_RearRightChildSaftyLockAction 0;
BA_ "GenSigSendType" SG_ 792 LCK_RearRightChildSaftyLockAction 1;
BA_ "GenSigStartValue" SG_ 792 LCK_RearRightChildSaftyLockAction 0;
BA_ "GenSigTimeoutValue" SG_ 792 LCK_RearRightChildSaftyLockAction 0;
BA_ "Remark" SG_ 792 LCK_RearRightChildSaftyLockAction "";
BA_ "EventCommandSignal" SG_ 792 LCK_RearRightDoorLockAction 0;
BA_ "GatewayedSignals" SG_ 792 LCK_RearRightDoorLockAction 0;
BA_ "GenSigInactiveValue" SG_ 792 LCK_RearRightDoorLockAction 0;
BA_ "GenSigInvalidValue" SG_ 792 LCK_RearRightDoorLockAction 0;
BA_ "GenSigSendType" SG_ 792 LCK_RearRightDoorLockAction 0;
BA_ "GenSigStartValue" SG_ 792 LCK_RearRightDoorLockAction 0;
BA_ "GenSigTimeoutValue" SG_ 792 LCK_RearRightDoorLockAction 0;
BA_ "Remark" SG_ 792 LCK_RearRightDoorLockAction "";
BA_ "EventCommandSignal" SG_ 1395 ZCUT_NMNodeAddress 0;
BA_ "GatewayedSignals" SG_ 1395 ZCUT_NMNodeAddress 0;
BA_ "GenSigInactiveValue" SG_ 1395 ZCUT_NMNodeAddress 0;
BA_ "GenSigInvalidValue" SG_ 1395 ZCUT_NMNodeAddress 0;
BA_ "GenSigSendType" SG_ 1395 ZCUT_NMNodeAddress 1;
BA_ "GenSigStartValue" SG_ 1395 ZCUT_NMNodeAddress 115;
BA_ "GenSigTimeoutValue" SG_ 1395 ZCUT_NMNodeAddress 0;
BA_ "Remark" SG_ 1395 ZCUT_NMNodeAddress "";
BA_ "EventCommandSignal" SG_ 1395 ZCUT_NMCBV 0;
BA_ "GatewayedSignals" SG_ 1395 ZCUT_NMCBV 0;
BA_ "GenSigInactiveValue" SG_ 1395 ZCUT_NMCBV 0;
BA_ "GenSigInvalidValue" SG_ 1395 ZCUT_NMCBV 0;
BA_ "GenSigSendType" SG_ 1395 ZCUT_NMCBV 1;
BA_ "GenSigStartValue" SG_ 1395 ZCUT_NMCBV 0;
BA_ "GenSigTimeoutValue" SG_ 1395 ZCUT_NMCBV 0;
BA_ "Remark" SG_ 1395 ZCUT_NMCBV "";
BA_ "EventCommandSignal" SG_ 1395 ZCUT_NMWakeupOrigin 0;
BA_ "GatewayedSignals" SG_ 1395 ZCUT_NMWakeupOrigin 0;
BA_ "GenSigInactiveValue" SG_ 1395 ZCUT_NMWakeupOrigin 0;
BA_ "GenSigInvalidValue" SG_ 1395 ZCUT_NMWakeupOrigin 0;
BA_ "GenSigSendType" SG_ 1395 ZCUT_NMWakeupOrigin 1;
BA_ "GenSigStartValue" SG_ 1395 ZCUT_NMWakeupOrigin 0;
BA_ "GenSigTimeoutValue" SG_ 1395 ZCUT_NMWakeupOrigin 0;
BA_ "Remark" SG_ 1395 ZCUT_NMWakeupOrigin "";
BA_ "EventCommandSignal" SG_ 1395 ZCUT_PNCInformation0 0;
BA_ "GatewayedSignals" SG_ 1395 ZCUT_PNCInformation0 0;
BA_ "GenSigInactiveValue" SG_ 1395 ZCUT_PNCInformation0 0;
BA_ "GenSigInvalidValue" SG_ 1395 ZCUT_PNCInformation0 0;
BA_ "GenSigSendType" SG_ 1395 ZCUT_PNCInformation0 1;
BA_ "GenSigStartValue" SG_ 1395 ZCUT_PNCInformation0 0;
BA_ "GenSigTimeoutValue" SG_ 1395 ZCUT_PNCInformation0 0;
BA_ "Remark" SG_ 1395 ZCUT_PNCInformation0 "";
BA_ "EventCommandSignal" SG_ 1395 ZCUT_PNCInformation1 0;
BA_ "GatewayedSignals" SG_ 1395 ZCUT_PNCInformation1 0;
BA_ "GenSigInactiveValue" SG_ 1395 ZCUT_PNCInformation1 0;
BA_ "GenSigInvalidValue" SG_ 1395 ZCUT_PNCInformation1 0;
BA_ "GenSigSendType" SG_ 1395 ZCUT_PNCInformation1 1;
BA_ "GenSigStartValue" SG_ 1395 ZCUT_PNCInformation1 0;
BA_ "GenSigTimeoutValue" SG_ 1395 ZCUT_PNCInformation1 0;
BA_ "Remark" SG_ 1395 ZCUT_PNCInformation1 "";
BA_ "EventCommandSignal" SG_ 1395 ZCUT_PNCInformation2 0;
BA_ "GatewayedSignals" SG_ 1395 ZCUT_PNCInformation2 0;
BA_ "GenSigInactiveValue" SG_ 1395 ZCUT_PNCInformation2 0;
BA_ "GenSigInvalidValue" SG_ 1395 ZCUT_PNCInformation2 0;
BA_ "GenSigSendType" SG_ 1395 ZCUT_PNCInformation2 1;
BA_ "GenSigStartValue" SG_ 1395 ZCUT_PNCInformation2 0;
BA_ "GenSigTimeoutValue" SG_ 1395 ZCUT_PNCInformation2 0;
BA_ "Remark" SG_ 1395 ZCUT_PNCInformation2 "";
BA_ "EventCommandSignal" SG_ 1697 LBMS_Diag_Request 1;
BA_ "GatewayedSignals" SG_ 1697 LBMS_Diag_Request 0;
BA_ "GenSigInactiveValue" SG_ 1697 LBMS_Diag_Request 0;
BA_ "GenSigInvalidValue" SG_ 1697 LBMS_Diag_Request 0;
BA_ "GenSigSendType" SG_ 1697 LBMS_Diag_Request 0;
BA_ "GenSigStartValue" SG_ 1697 LBMS_Diag_Request 0;
BA_ "GenSigTimeoutValue" SG_ 1697 LBMS_Diag_Request 0;
BA_ "Remark" SG_ 1697 LBMS_Diag_Request "";
BA_ "EventCommandSignal" SG_ 1705 LBMS_Diag_Response 1;
BA_ "GatewayedSignals" SG_ 1705 LBMS_Diag_Response 0;
BA_ "GenSigInactiveValue" SG_ 1705 LBMS_Diag_Response 0;
BA_ "GenSigInvalidValue" SG_ 1705 LBMS_Diag_Response 0;
BA_ "GenSigSendType" SG_ 1705 LBMS_Diag_Response 0;
BA_ "GenSigStartValue" SG_ 1705 LBMS_Diag_Response 0;
BA_ "GenSigTimeoutValue" SG_ 1705 LBMS_Diag_Response 0;
BA_ "Remark" SG_ 1705 LBMS_Diag_Response "";
BA_ "EventCommandSignal" SG_ 1449 LBMS_NMNodeAddress 0;
BA_ "GatewayedSignals" SG_ 1449 LBMS_NMNodeAddress 0;
BA_ "GenSigInactiveValue" SG_ 1449 LBMS_NMNodeAddress 0;
BA_ "GenSigInvalidValue" SG_ 1449 LBMS_NMNodeAddress 0;
BA_ "GenSigSendType" SG_ 1449 LBMS_NMNodeAddress 1;
BA_ "GenSigStartValue" SG_ 1449 LBMS_NMNodeAddress 169;
BA_ "GenSigTimeoutValue" SG_ 1449 LBMS_NMNodeAddress 0;
BA_ "Remark" SG_ 1449 LBMS_NMNodeAddress "";
BA_ "EventCommandSignal" SG_ 1449 LBMS_NMCBV 0;
BA_ "GatewayedSignals" SG_ 1449 LBMS_NMCBV 0;
BA_ "GenSigInactiveValue" SG_ 1449 LBMS_NMCBV 0;
BA_ "GenSigInvalidValue" SG_ 1449 LBMS_NMCBV 0;
BA_ "GenSigSendType" SG_ 1449 LBMS_NMCBV 1;
BA_ "GenSigStartValue" SG_ 1449 LBMS_NMCBV 0;
BA_ "GenSigTimeoutValue" SG_ 1449 LBMS_NMCBV 0;
BA_ "Remark" SG_ 1449 LBMS_NMCBV "";
BA_ "EventCommandSignal" SG_ 1449 LBMS_NMWakeupOrigin 0;
BA_ "GatewayedSignals" SG_ 1449 LBMS_NMWakeupOrigin 0;
BA_ "GenSigInactiveValue" SG_ 1449 LBMS_NMWakeupOrigin 0;
BA_ "GenSigInvalidValue" SG_ 1449 LBMS_NMWakeupOrigin 0;
BA_ "GenSigSendType" SG_ 1449 LBMS_NMWakeupOrigin 1;
BA_ "GenSigStartValue" SG_ 1449 LBMS_NMWakeupOrigin 0;
BA_ "GenSigTimeoutValue" SG_ 1449 LBMS_NMWakeupOrigin 0;
BA_ "Remark" SG_ 1449 LBMS_NMWakeupOrigin "";
BA_ "EventCommandSignal" SG_ 1449 LBMS_PNCInformation0 0;
BA_ "GatewayedSignals" SG_ 1449 LBMS_PNCInformation0 0;
BA_ "GenSigInactiveValue" SG_ 1449 LBMS_PNCInformation0 0;
BA_ "GenSigInvalidValue" SG_ 1449 LBMS_PNCInformation0 0;
BA_ "GenSigSendType" SG_ 1449 LBMS_PNCInformation0 1;
BA_ "GenSigStartValue" SG_ 1449 LBMS_PNCInformation0 0;
BA_ "GenSigTimeoutValue" SG_ 1449 LBMS_PNCInformation0 0;
BA_ "Remark" SG_ 1449 LBMS_PNCInformation0 "";
BA_ "EventCommandSignal" SG_ 1449 LBMS_PNCInformation1 0;
BA_ "GatewayedSignals" SG_ 1449 LBMS_PNCInformation1 0;
BA_ "GenSigInactiveValue" SG_ 1449 LBMS_PNCInformation1 0;
BA_ "GenSigInvalidValue" SG_ 1449 LBMS_PNCInformation1 0;
BA_ "GenSigSendType" SG_ 1449 LBMS_PNCInformation1 1;
BA_ "GenSigStartValue" SG_ 1449 LBMS_PNCInformation1 0;
BA_ "GenSigTimeoutValue" SG_ 1449 LBMS_PNCInformation1 0;
BA_ "Remark" SG_ 1449 LBMS_PNCInformation1 "";
BA_ "EventCommandSignal" SG_ 1449 LBMS_PNCInformation2 0;
BA_ "GatewayedSignals" SG_ 1449 LBMS_PNCInformation2 0;
BA_ "GenSigInactiveValue" SG_ 1449 LBMS_PNCInformation2 0;
BA_ "GenSigInvalidValue" SG_ 1449 LBMS_PNCInformation2 0;
BA_ "GenSigSendType" SG_ 1449 LBMS_PNCInformation2 1;
BA_ "GenSigStartValue" SG_ 1449 LBMS_PNCInformation2 0;
BA_ "GenSigTimeoutValue" SG_ 1449 LBMS_PNCInformation2 0;
BA_ "Remark" SG_ 1449 LBMS_PNCInformation2 "";
BA_ "EventCommandSignal" SG_ 793 LBMS_1_CRC 0;
BA_ "GatewayedSignals" SG_ 793 LBMS_1_CRC 0;
BA_ "GenSigInactiveValue" SG_ 793 LBMS_1_CRC 0;
BA_ "GenSigInvalidValue" SG_ 793 LBMS_1_CRC 0;
BA_ "GenSigSendType" SG_ 793 LBMS_1_CRC 1;
BA_ "GenSigStartValue" SG_ 793 LBMS_1_CRC 0;
BA_ "GenSigTimeoutValue" SG_ 793 LBMS_1_CRC 0;
BA_ "Remark" SG_ 793 LBMS_1_CRC "";
BA_ "EventCommandSignal" SG_ 793 LBMS_1_Counter 0;
BA_ "GatewayedSignals" SG_ 793 LBMS_1_Counter 0;
BA_ "GenSigInactiveValue" SG_ 793 LBMS_1_Counter 0;
BA_ "GenSigInvalidValue" SG_ 793 LBMS_1_Counter 0;
BA_ "GenSigSendType" SG_ 793 LBMS_1_Counter 1;
BA_ "GenSigStartValue" SG_ 793 LBMS_1_Counter 0;
BA_ "GenSigTimeoutValue" SG_ 793 LBMS_1_Counter 0;
BA_ "Remark" SG_ 793 LBMS_1_Counter "";
BA_ "EventCommandSignal" SG_ 793 LBMS_UnsfLoadPackVoltVD 0;
BA_ "GatewayedSignals" SG_ 793 LBMS_UnsfLoadPackVoltVD 0;
BA_ "GenSigInactiveValue" SG_ 793 LBMS_UnsfLoadPackVoltVD 0;
BA_ "GenSigInvalidValue" SG_ 793 LBMS_UnsfLoadPackVoltVD 0;
BA_ "GenSigSendType" SG_ 793 LBMS_UnsfLoadPackVoltVD 1;
BA_ "GenSigStartValue" SG_ 793 LBMS_UnsfLoadPackVoltVD 0;
BA_ "GenSigTimeoutValue" SG_ 793 LBMS_UnsfLoadPackVoltVD 0;
BA_ "Remark" SG_ 793 LBMS_UnsfLoadPackVoltVD "";
BA_ "EventCommandSignal" SG_ 793 LBMS_UnsfLoadPackVolt 0;
BA_ "GatewayedSignals" SG_ 793 LBMS_UnsfLoadPackVolt 0;
BA_ "GenSigInactiveValue" SG_ 793 LBMS_UnsfLoadPackVolt 0;
BA_ "GenSigInvalidValue" SG_ 793 LBMS_UnsfLoadPackVolt 0;
BA_ "GenSigSendType" SG_ 793 LBMS_UnsfLoadPackVolt 1;
BA_ "GenSigStartValue" SG_ 793 LBMS_UnsfLoadPackVolt 2047;
BA_ "GenSigTimeoutValue" SG_ 793 LBMS_UnsfLoadPackVolt 0;
BA_ "Remark" SG_ 793 LBMS_UnsfLoadPackVolt "";
BA_ "EventCommandSignal" SG_ 793 LBMS_SfLoadPackVoltVD 0;
BA_ "GatewayedSignals" SG_ 793 LBMS_SfLoadPackVoltVD 0;
BA_ "GenSigInactiveValue" SG_ 793 LBMS_SfLoadPackVoltVD 0;
BA_ "GenSigInvalidValue" SG_ 793 LBMS_SfLoadPackVoltVD 0;
BA_ "GenSigSendType" SG_ 793 LBMS_SfLoadPackVoltVD 1;
BA_ "GenSigStartValue" SG_ 793 LBMS_SfLoadPackVoltVD 0;
BA_ "GenSigTimeoutValue" SG_ 793 LBMS_SfLoadPackVoltVD 0;
BA_ "Remark" SG_ 793 LBMS_SfLoadPackVoltVD "";
BA_ "EventCommandSignal" SG_ 793 LBMS_SfLoadPackVolt 0;
BA_ "GatewayedSignals" SG_ 793 LBMS_SfLoadPackVolt 0;
BA_ "GenSigInactiveValue" SG_ 793 LBMS_SfLoadPackVolt 0;
BA_ "GenSigInvalidValue" SG_ 793 LBMS_SfLoadPackVolt 0;
BA_ "GenSigSendType" SG_ 793 LBMS_SfLoadPackVolt 1;
BA_ "GenSigStartValue" SG_ 793 LBMS_SfLoadPackVolt 2047;
BA_ "GenSigTimeoutValue" SG_ 793 LBMS_SfLoadPackVolt 0;
BA_ "Remark" SG_ 793 LBMS_SfLoadPackVolt "";
BA_ "EventCommandSignal" SG_ 793 LBMS_UnsfLoadCurrentRange 0;
BA_ "GatewayedSignals" SG_ 793 LBMS_UnsfLoadCurrentRange 0;
BA_ "GenSigInactiveValue" SG_ 793 LBMS_UnsfLoadCurrentRange 0;
BA_ "GenSigInvalidValue" SG_ 793 LBMS_UnsfLoadCurrentRange 0;
BA_ "GenSigSendType" SG_ 793 LBMS_UnsfLoadCurrentRange 1;
BA_ "GenSigStartValue" SG_ 793 LBMS_UnsfLoadCurrentRange 0;
BA_ "GenSigTimeoutValue" SG_ 793 LBMS_UnsfLoadCurrentRange 0;
BA_ "Remark" SG_ 793 LBMS_UnsfLoadCurrentRange "";
BA_ "EventCommandSignal" SG_ 793 LBMS_SfLoadCurrentRange 0;
BA_ "GatewayedSignals" SG_ 793 LBMS_SfLoadCurrentRange 0;
BA_ "GenSigInactiveValue" SG_ 793 LBMS_SfLoadCurrentRange 0;
BA_ "GenSigInvalidValue" SG_ 793 LBMS_SfLoadCurrentRange 0;
BA_ "GenSigSendType" SG_ 793 LBMS_SfLoadCurrentRange 1;
BA_ "GenSigStartValue" SG_ 793 LBMS_SfLoadCurrentRange 0;
BA_ "GenSigTimeoutValue" SG_ 793 LBMS_SfLoadCurrentRange 0;
BA_ "Remark" SG_ 793 LBMS_SfLoadCurrentRange "";
BA_ "EventCommandSignal" SG_ 793 LBMS_SOFVD 0;
BA_ "GatewayedSignals" SG_ 793 LBMS_SOFVD 0;
BA_ "GenSigInactiveValue" SG_ 793 LBMS_SOFVD 0;
BA_ "GenSigInvalidValue" SG_ 793 LBMS_SOFVD 0;
BA_ "GenSigSendType" SG_ 793 LBMS_SOFVD 1;
BA_ "GenSigStartValue" SG_ 793 LBMS_SOFVD 0;
BA_ "GenSigTimeoutValue" SG_ 793 LBMS_SOFVD 0;
BA_ "Remark" SG_ 793 LBMS_SOFVD "";
BA_ "EventCommandSignal" SG_ 793 LBMS_SOFEN 0;
BA_ "GatewayedSignals" SG_ 793 LBMS_SOFEN 0;
BA_ "GenSigInactiveValue" SG_ 793 LBMS_SOFEN 0;
BA_ "GenSigInvalidValue" SG_ 793 LBMS_SOFEN 0;
BA_ "GenSigSendType" SG_ 793 LBMS_SOFEN 1;
BA_ "GenSigStartValue" SG_ 793 LBMS_SOFEN 0;
BA_ "GenSigTimeoutValue" SG_ 793 LBMS_SOFEN 0;
BA_ "Remark" SG_ 793 LBMS_SOFEN "";
BA_ "EventCommandSignal" SG_ 793 LBMS_SOFInhibitSt 0;
BA_ "GatewayedSignals" SG_ 793 LBMS_SOFInhibitSt 0;
BA_ "GenSigInactiveValue" SG_ 793 LBMS_SOFInhibitSt 0;
BA_ "GenSigInvalidValue" SG_ 793 LBMS_SOFInhibitSt 0;
BA_ "GenSigSendType" SG_ 793 LBMS_SOFInhibitSt 1;
BA_ "GenSigStartValue" SG_ 793 LBMS_SOFInhibitSt 0;
BA_ "GenSigTimeoutValue" SG_ 793 LBMS_SOFInhibitSt 0;
BA_ "Remark" SG_ 793 LBMS_SOFInhibitSt "";
BA_ "EventCommandSignal" SG_ 793 LBMS_ChargReq 0;
BA_ "GatewayedSignals" SG_ 793 LBMS_ChargReq 0;
BA_ "GenSigInactiveValue" SG_ 793 LBMS_ChargReq 0;
BA_ "GenSigInvalidValue" SG_ 793 LBMS_ChargReq 0;
BA_ "GenSigSendType" SG_ 793 LBMS_ChargReq 1;
BA_ "GenSigStartValue" SG_ 793 LBMS_ChargReq 0;
BA_ "GenSigTimeoutValue" SG_ 793 LBMS_ChargReq 0;
BA_ "Remark" SG_ 793 LBMS_ChargReq "";
BA_ "EventCommandSignal" SG_ 793 LBMS_SOCVD 0;
BA_ "GatewayedSignals" SG_ 793 LBMS_SOCVD 0;
BA_ "GenSigInactiveValue" SG_ 793 LBMS_SOCVD 0;
BA_ "GenSigInvalidValue" SG_ 793 LBMS_SOCVD 0;
BA_ "GenSigSendType" SG_ 793 LBMS_SOCVD 1;
BA_ "GenSigStartValue" SG_ 793 LBMS_SOCVD 0;
BA_ "GenSigTimeoutValue" SG_ 793 LBMS_SOCVD 0;
BA_ "Remark" SG_ 793 LBMS_SOCVD "";
BA_ "EventCommandSignal" SG_ 793 LBMS_SOC 0;
BA_ "GatewayedSignals" SG_ 793 LBMS_SOC 0;
BA_ "GenSigInactiveValue" SG_ 793 LBMS_SOC 0;
BA_ "GenSigInvalidValue" SG_ 793 LBMS_SOC 0;
BA_ "GenSigSendType" SG_ 793 LBMS_SOC 1;
BA_ "GenSigStartValue" SG_ 793 LBMS_SOC 255;
BA_ "GenSigTimeoutValue" SG_ 793 LBMS_SOC 0;
BA_ "Remark" SG_ 793 LBMS_SOC "";
BA_ "EventCommandSignal" SG_ 793 LBMS_PackVoltVD 0;
BA_ "GatewayedSignals" SG_ 793 LBMS_PackVoltVD 0;
BA_ "GenSigInactiveValue" SG_ 793 LBMS_PackVoltVD 0;
BA_ "GenSigInvalidValue" SG_ 793 LBMS_PackVoltVD 0;
BA_ "GenSigSendType" SG_ 793 LBMS_PackVoltVD 1;
BA_ "GenSigStartValue" SG_ 793 LBMS_PackVoltVD 0;
BA_ "GenSigTimeoutValue" SG_ 793 LBMS_PackVoltVD 0;
BA_ "Remark" SG_ 793 LBMS_PackVoltVD "";
BA_ "EventCommandSignal" SG_ 793 LBMS_PackVolt 0;
BA_ "GatewayedSignals" SG_ 793 LBMS_PackVolt 0;
BA_ "GenSigInactiveValue" SG_ 793 LBMS_PackVolt 0;
BA_ "GenSigInvalidValue" SG_ 793 LBMS_PackVolt 0;
BA_ "GenSigSendType" SG_ 793 LBMS_PackVolt 1;
BA_ "GenSigStartValue" SG_ 793 LBMS_PackVolt 2047;
BA_ "GenSigTimeoutValue" SG_ 793 LBMS_PackVolt 0;
BA_ "Remark" SG_ 793 LBMS_PackVolt "";
BA_ "EventCommandSignal" SG_ 793 LBMS_AlrmDispSt 0;
BA_ "GatewayedSignals" SG_ 793 LBMS_AlrmDispSt 0;
BA_ "GenSigInactiveValue" SG_ 793 LBMS_AlrmDispSt 0;
BA_ "GenSigInvalidValue" SG_ 793 LBMS_AlrmDispSt 0;
BA_ "GenSigSendType" SG_ 793 LBMS_AlrmDispSt 1;
BA_ "GenSigStartValue" SG_ 793 LBMS_AlrmDispSt 0;
BA_ "GenSigTimeoutValue" SG_ 793 LBMS_AlrmDispSt 0;
BA_ "Remark" SG_ 793 LBMS_AlrmDispSt "";
BA_ "EventCommandSignal" SG_ 793 LBMS_CurrentRange 0;
BA_ "GatewayedSignals" SG_ 793 LBMS_CurrentRange 0;
BA_ "GenSigInactiveValue" SG_ 793 LBMS_CurrentRange 0;
BA_ "GenSigInvalidValue" SG_ 793 LBMS_CurrentRange 0;
BA_ "GenSigSendType" SG_ 793 LBMS_CurrentRange 1;
BA_ "GenSigStartValue" SG_ 793 LBMS_CurrentRange 0;
BA_ "GenSigTimeoutValue" SG_ 793 LBMS_CurrentRange 0;
BA_ "Remark" SG_ 793 LBMS_CurrentRange "";
BA_ "EventCommandSignal" SG_ 793 LBMS_RefChargReq 0;
BA_ "GatewayedSignals" SG_ 793 LBMS_RefChargReq 0;
BA_ "GenSigInactiveValue" SG_ 793 LBMS_RefChargReq 0;
BA_ "GenSigInvalidValue" SG_ 793 LBMS_RefChargReq 0;
BA_ "GenSigSendType" SG_ 793 LBMS_RefChargReq 1;
BA_ "GenSigStartValue" SG_ 793 LBMS_RefChargReq 0;
BA_ "GenSigTimeoutValue" SG_ 793 LBMS_RefChargReq 0;
BA_ "Remark" SG_ 793 LBMS_RefChargReq "";
BA_ "EventCommandSignal" SG_ 793 LBMS_ThermalRunawayErr 0;
BA_ "GatewayedSignals" SG_ 793 LBMS_ThermalRunawayErr 0;
BA_ "GenSigInactiveValue" SG_ 793 LBMS_ThermalRunawayErr 0;
BA_ "GenSigInvalidValue" SG_ 793 LBMS_ThermalRunawayErr 0;
BA_ "GenSigSendType" SG_ 793 LBMS_ThermalRunawayErr 1;
BA_ "GenSigStartValue" SG_ 793 LBMS_ThermalRunawayErr 0;
BA_ "GenSigTimeoutValue" SG_ 793 LBMS_ThermalRunawayErr 0;
BA_ "Remark" SG_ 793 LBMS_ThermalRunawayErr "";
BA_ "EventCommandSignal" SG_ 793 LBMS_ChrgVoltReq 0;
BA_ "GatewayedSignals" SG_ 793 LBMS_ChrgVoltReq 0;
BA_ "GenSigInactiveValue" SG_ 793 LBMS_ChrgVoltReq 0;
BA_ "GenSigInvalidValue" SG_ 793 LBMS_ChrgVoltReq 0;
BA_ "GenSigSendType" SG_ 793 LBMS_ChrgVoltReq 1;
BA_ "GenSigStartValue" SG_ 793 LBMS_ChrgVoltReq 1023;
BA_ "GenSigTimeoutValue" SG_ 793 LBMS_ChrgVoltReq 0;
BA_ "Remark" SG_ 793 LBMS_ChrgVoltReq "";
BA_ "EventCommandSignal" SG_ 793 LBMS_IPDS_BAT1PowerReq 0;
BA_ "GatewayedSignals" SG_ 793 LBMS_IPDS_BAT1PowerReq 0;
BA_ "GenSigInactiveValue" SG_ 793 LBMS_IPDS_BAT1PowerReq 0;
BA_ "GenSigInvalidValue" SG_ 793 LBMS_IPDS_BAT1PowerReq 0;
BA_ "GenSigSendType" SG_ 793 LBMS_IPDS_BAT1PowerReq 1;
BA_ "GenSigStartValue" SG_ 793 LBMS_IPDS_BAT1PowerReq 1;
BA_ "GenSigTimeoutValue" SG_ 793 LBMS_IPDS_BAT1PowerReq 0;
BA_ "Remark" SG_ 793 LBMS_IPDS_BAT1PowerReq "";
BA_ "EventCommandSignal" SG_ 793 LBMS_IPDS_BAT2PowerReq 0;
BA_ "GatewayedSignals" SG_ 793 LBMS_IPDS_BAT2PowerReq 0;
BA_ "GenSigInactiveValue" SG_ 793 LBMS_IPDS_BAT2PowerReq 0;
BA_ "GenSigInvalidValue" SG_ 793 LBMS_IPDS_BAT2PowerReq 0;
BA_ "GenSigSendType" SG_ 793 LBMS_IPDS_BAT2PowerReq 1;
BA_ "GenSigStartValue" SG_ 793 LBMS_IPDS_BAT2PowerReq 1;
BA_ "GenSigTimeoutValue" SG_ 793 LBMS_IPDS_BAT2PowerReq 0;
BA_ "Remark" SG_ 793 LBMS_IPDS_BAT2PowerReq "";
BA_ "EventCommandSignal" SG_ 793 LBMS_IPDS_GridlsoPowerReq 0;
BA_ "GatewayedSignals" SG_ 793 LBMS_IPDS_GridlsoPowerReq 0;
BA_ "GenSigInactiveValue" SG_ 793 LBMS_IPDS_GridlsoPowerReq 0;
BA_ "GenSigInvalidValue" SG_ 793 LBMS_IPDS_GridlsoPowerReq 0;
BA_ "GenSigSendType" SG_ 793 LBMS_IPDS_GridlsoPowerReq 1;
BA_ "GenSigStartValue" SG_ 793 LBMS_IPDS_GridlsoPowerReq 1;
BA_ "GenSigTimeoutValue" SG_ 793 LBMS_IPDS_GridlsoPowerReq 0;
BA_ "Remark" SG_ 793 LBMS_IPDS_GridlsoPowerReq "功能需求纯电混动信号默认值不一致";
BA_ "EventCommandSignal" SG_ 793 LBMS_FaultSt_SOCLow 0;
BA_ "GatewayedSignals" SG_ 793 LBMS_FaultSt_SOCLow 0;
BA_ "GenSigInactiveValue" SG_ 793 LBMS_FaultSt_SOCLow 0;
BA_ "GenSigInvalidValue" SG_ 793 LBMS_FaultSt_SOCLow 0;
BA_ "GenSigSendType" SG_ 793 LBMS_FaultSt_SOCLow 1;
BA_ "GenSigStartValue" SG_ 793 LBMS_FaultSt_SOCLow 0;
BA_ "GenSigTimeoutValue" SG_ 793 LBMS_FaultSt_SOCLow 0;
BA_ "Remark" SG_ 793 LBMS_FaultSt_SOCLow "";
BA_ "EventCommandSignal" SG_ 793 LBMS_FaultNum 0;
BA_ "GatewayedSignals" SG_ 793 LBMS_FaultNum 0;
BA_ "GenSigInactiveValue" SG_ 793 LBMS_FaultNum 0;
BA_ "GenSigInvalidValue" SG_ 793 LBMS_FaultNum 0;
BA_ "GenSigSendType" SG_ 793 LBMS_FaultNum 1;
BA_ "GenSigStartValue" SG_ 793 LBMS_FaultNum 0;
BA_ "GenSigTimeoutValue" SG_ 793 LBMS_FaultNum 0;
BA_ "Remark" SG_ 793 LBMS_FaultNum "";
BA_ "EventCommandSignal" SG_ 793 LBMS_FaultCode 0;
BA_ "GatewayedSignals" SG_ 793 LBMS_FaultCode 0;
BA_ "GenSigInactiveValue" SG_ 793 LBMS_FaultCode 0;
BA_ "GenSigInvalidValue" SG_ 793 LBMS_FaultCode 0;
BA_ "GenSigSendType" SG_ 793 LBMS_FaultCode 1;
BA_ "GenSigStartValue" SG_ 793 LBMS_FaultCode 0;
BA_ "GenSigTimeoutValue" SG_ 793 LBMS_FaultCode 0;
BA_ "Remark" SG_ 793 LBMS_FaultCode "";
BA_ "EventCommandSignal" SG_ 793 LBMS_DisconnectSt 0;
BA_ "GatewayedSignals" SG_ 793 LBMS_DisconnectSt 0;
BA_ "GenSigInactiveValue" SG_ 793 LBMS_DisconnectSt 0;
BA_ "GenSigInvalidValue" SG_ 793 LBMS_DisconnectSt 0;
BA_ "GenSigSendType" SG_ 793 LBMS_DisconnectSt 1;
BA_ "GenSigStartValue" SG_ 793 LBMS_DisconnectSt 0;
BA_ "GenSigTimeoutValue" SG_ 793 LBMS_DisconnectSt 0;
BA_ "Remark" SG_ 793 LBMS_DisconnectSt "";
BA_ "EventCommandSignal" SG_ 973 LBMS_SOH 0;
BA_ "GatewayedSignals" SG_ 973 LBMS_SOH 0;
BA_ "GenSigInactiveValue" SG_ 973 LBMS_SOH 0;
BA_ "GenSigInvalidValue" SG_ 973 LBMS_SOH 0;
BA_ "GenSigSendType" SG_ 973 LBMS_SOH 1;
BA_ "GenSigStartValue" SG_ 973 LBMS_SOH 255;
BA_ "GenSigTimeoutValue" SG_ 973 LBMS_SOH 0;
BA_ "Remark" SG_ 973 LBMS_SOH "";
BA_ "EventCommandSignal" SG_ 973 LBMS_SOHVD 0;
BA_ "GatewayedSignals" SG_ 973 LBMS_SOHVD 0;
BA_ "GenSigInactiveValue" SG_ 973 LBMS_SOHVD 0;
BA_ "GenSigInvalidValue" SG_ 973 LBMS_SOHVD 0;
BA_ "GenSigSendType" SG_ 973 LBMS_SOHVD 1;
BA_ "GenSigStartValue" SG_ 973 LBMS_SOHVD 0;
BA_ "GenSigTimeoutValue" SG_ 973 LBMS_SOHVD 0;
BA_ "Remark" SG_ 973 LBMS_SOHVD "";
BA_ "EventCommandSignal" SG_ 973 LBMS_Current 0;
BA_ "GatewayedSignals" SG_ 973 LBMS_Current 0;
BA_ "GenSigInactiveValue" SG_ 973 LBMS_Current 0;
BA_ "GenSigInvalidValue" SG_ 973 LBMS_Current 0;
BA_ "GenSigSendType" SG_ 973 LBMS_Current 1;
BA_ "GenSigStartValue" SG_ 973 LBMS_Current 4194303;
BA_ "GenSigTimeoutValue" SG_ 973 LBMS_Current 0;
BA_ "Remark" SG_ 973 LBMS_Current "";
BA_ "EventCommandSignal" SG_ 973 LBMS_ChrgCurrentReq 0;
BA_ "GatewayedSignals" SG_ 973 LBMS_ChrgCurrentReq 0;
BA_ "GenSigInactiveValue" SG_ 973 LBMS_ChrgCurrentReq 0;
BA_ "GenSigInvalidValue" SG_ 973 LBMS_ChrgCurrentReq 0;
BA_ "GenSigSendType" SG_ 973 LBMS_ChrgCurrentReq 1;
BA_ "GenSigStartValue" SG_ 973 LBMS_ChrgCurrentReq 4095;
BA_ "GenSigTimeoutValue" SG_ 973 LBMS_ChrgCurrentReq 0;
BA_ "Remark" SG_ 973 LBMS_ChrgCurrentReq "";
BA_ "EventCommandSignal" SG_ 973 LBMS_CellTotVolt 0;
BA_ "GatewayedSignals" SG_ 973 LBMS_CellTotVolt 0;
BA_ "GenSigInactiveValue" SG_ 973 LBMS_CellTotVolt 0;
BA_ "GenSigInvalidValue" SG_ 973 LBMS_CellTotVolt 0;
BA_ "GenSigSendType" SG_ 973 LBMS_CellTotVolt 1;
BA_ "GenSigStartValue" SG_ 973 LBMS_CellTotVolt 2047;
BA_ "GenSigTimeoutValue" SG_ 973 LBMS_CellTotVolt 0;
BA_ "Remark" SG_ 973 LBMS_CellTotVolt "";
BA_ "EventCommandSignal" SG_ 973 LBMS_CellTotVoltVD 0;
BA_ "GatewayedSignals" SG_ 973 LBMS_CellTotVoltVD 0;
BA_ "GenSigInactiveValue" SG_ 973 LBMS_CellTotVoltVD 0;
BA_ "GenSigInvalidValue" SG_ 973 LBMS_CellTotVoltVD 0;
BA_ "GenSigSendType" SG_ 973 LBMS_CellTotVoltVD 1;
BA_ "GenSigStartValue" SG_ 973 LBMS_CellTotVoltVD 0;
BA_ "GenSigTimeoutValue" SG_ 973 LBMS_CellTotVoltVD 0;
BA_ "Remark" SG_ 973 LBMS_CellTotVoltVD "";
BA_ "EventCommandSignal" SG_ 973 LBMS_ChargReqEn 0;
BA_ "GatewayedSignals" SG_ 973 LBMS_ChargReqEn 0;
BA_ "GenSigInactiveValue" SG_ 973 LBMS_ChargReqEn 0;
BA_ "GenSigInvalidValue" SG_ 973 LBMS_ChargReqEn 0;
BA_ "GenSigSendType" SG_ 973 LBMS_ChargReqEn 1;
BA_ "GenSigStartValue" SG_ 973 LBMS_ChargReqEn 0;
BA_ "GenSigTimeoutValue" SG_ 973 LBMS_ChargReqEn 0;
BA_ "Remark" SG_ 973 LBMS_ChargReqEn "";
BA_ "EventCommandSignal" SG_ 973 LBMS_WorkSt 0;
BA_ "GatewayedSignals" SG_ 973 LBMS_WorkSt 0;
BA_ "GenSigInactiveValue" SG_ 973 LBMS_WorkSt 0;
BA_ "GenSigInvalidValue" SG_ 973 LBMS_WorkSt 0;
BA_ "GenSigSendType" SG_ 973 LBMS_WorkSt 1;
BA_ "GenSigStartValue" SG_ 973 LBMS_WorkSt 0;
BA_ "GenSigTimeoutValue" SG_ 973 LBMS_WorkSt 0;
BA_ "Remark" SG_ 973 LBMS_WorkSt "";
BA_ "EventCommandSignal" SG_ 973 LBMS_MOSSt 0;
BA_ "GatewayedSignals" SG_ 973 LBMS_MOSSt 0;
BA_ "GenSigInactiveValue" SG_ 973 LBMS_MOSSt 0;
BA_ "GenSigInvalidValue" SG_ 973 LBMS_MOSSt 0;
BA_ "GenSigSendType" SG_ 973 LBMS_MOSSt 1;
BA_ "GenSigStartValue" SG_ 973 LBMS_MOSSt 7;
BA_ "GenSigTimeoutValue" SG_ 973 LBMS_MOSSt 0;
BA_ "Remark" SG_ 973 LBMS_MOSSt "";
BA_ "EventCommandSignal" SG_ 973 LBMS_WakeupSource 0;
BA_ "GatewayedSignals" SG_ 973 LBMS_WakeupSource 0;
BA_ "GenSigInactiveValue" SG_ 973 LBMS_WakeupSource 0;
BA_ "GenSigInvalidValue" SG_ 973 LBMS_WakeupSource 0;
BA_ "GenSigSendType" SG_ 973 LBMS_WakeupSource 1;
BA_ "GenSigStartValue" SG_ 973 LBMS_WakeupSource 0;
BA_ "GenSigTimeoutValue" SG_ 973 LBMS_WakeupSource 0;
BA_ "Remark" SG_ 973 LBMS_WakeupSource "";
BA_ "EventCommandSignal" SG_ 973 LBMS_HardWireSt 0;
BA_ "GatewayedSignals" SG_ 973 LBMS_HardWireSt 0;
BA_ "GenSigInactiveValue" SG_ 973 LBMS_HardWireSt 0;
BA_ "GenSigInvalidValue" SG_ 973 LBMS_HardWireSt 0;
BA_ "GenSigSendType" SG_ 973 LBMS_HardWireSt 1;
BA_ "GenSigStartValue" SG_ 973 LBMS_HardWireSt 0;
BA_ "GenSigTimeoutValue" SG_ 973 LBMS_HardWireSt 0;
BA_ "Remark" SG_ 973 LBMS_HardWireSt "";
BA_ "EventCommandSignal" SG_ 973 LBMS_QC 0;
BA_ "GatewayedSignals" SG_ 973 LBMS_QC 0;
BA_ "GenSigInactiveValue" SG_ 973 LBMS_QC 0;
BA_ "GenSigInvalidValue" SG_ 973 LBMS_QC 0;
BA_ "GenSigSendType" SG_ 973 LBMS_QC 1;
BA_ "GenSigStartValue" SG_ 973 LBMS_QC 0;
BA_ "GenSigTimeoutValue" SG_ 973 LBMS_QC 0;
BA_ "Remark" SG_ 973 LBMS_QC "";
BA_ "EventCommandSignal" SG_ 973 LBMS_WireHarnConSt 0;
BA_ "GatewayedSignals" SG_ 973 LBMS_WireHarnConSt 0;
BA_ "GenSigInactiveValue" SG_ 973 LBMS_WireHarnConSt 0;
BA_ "GenSigInvalidValue" SG_ 973 LBMS_WireHarnConSt 0;
BA_ "GenSigSendType" SG_ 973 LBMS_WireHarnConSt 1;
BA_ "GenSigStartValue" SG_ 973 LBMS_WireHarnConSt 7;
BA_ "GenSigTimeoutValue" SG_ 973 LBMS_WireHarnConSt 0;
BA_ "Remark" SG_ 973 LBMS_WireHarnConSt "";
BA_ "EventCommandSignal" SG_ 973 LBMS_SOCCaliMode 0;
BA_ "GatewayedSignals" SG_ 973 LBMS_SOCCaliMode 0;
BA_ "GenSigInactiveValue" SG_ 973 LBMS_SOCCaliMode 0;
BA_ "GenSigInvalidValue" SG_ 973 LBMS_SOCCaliMode 0;
BA_ "GenSigSendType" SG_ 973 LBMS_SOCCaliMode 1;
BA_ "GenSigStartValue" SG_ 973 LBMS_SOCCaliMode 0;
BA_ "GenSigTimeoutValue" SG_ 973 LBMS_SOCCaliMode 0;
BA_ "Remark" SG_ 973 LBMS_SOCCaliMode "";
BA_ "EventCommandSignal" SG_ 973 LBMS_ChrgCurrentLimt1 0;
BA_ "GatewayedSignals" SG_ 973 LBMS_ChrgCurrentLimt1 0;
BA_ "GenSigInactiveValue" SG_ 973 LBMS_ChrgCurrentLimt1 0;
BA_ "GenSigInvalidValue" SG_ 973 LBMS_ChrgCurrentLimt1 0;
BA_ "GenSigSendType" SG_ 973 LBMS_ChrgCurrentLimt1 1;
BA_ "GenSigStartValue" SG_ 973 LBMS_ChrgCurrentLimt1 4095;
BA_ "GenSigTimeoutValue" SG_ 973 LBMS_ChrgCurrentLimt1 0;
BA_ "Remark" SG_ 973 LBMS_ChrgCurrentLimt1 "";
BA_ "EventCommandSignal" SG_ 973 LBMS_ChrgCurrentLimt2 0;
BA_ "GatewayedSignals" SG_ 973 LBMS_ChrgCurrentLimt2 0;
BA_ "GenSigInactiveValue" SG_ 973 LBMS_ChrgCurrentLimt2 0;
BA_ "GenSigInvalidValue" SG_ 973 LBMS_ChrgCurrentLimt2 0;
BA_ "GenSigSendType" SG_ 973 LBMS_ChrgCurrentLimt2 1;
BA_ "GenSigStartValue" SG_ 973 LBMS_ChrgCurrentLimt2 4095;
BA_ "GenSigTimeoutValue" SG_ 973 LBMS_ChrgCurrentLimt2 0;
BA_ "Remark" SG_ 973 LBMS_ChrgCurrentLimt2 "";
BA_ "EventCommandSignal" SG_ 973 LBMS_ChrgCurrentLimt1VD 0;
BA_ "GatewayedSignals" SG_ 973 LBMS_ChrgCurrentLimt1VD 0;
BA_ "GenSigInactiveValue" SG_ 973 LBMS_ChrgCurrentLimt1VD 0;
BA_ "GenSigInvalidValue" SG_ 973 LBMS_ChrgCurrentLimt1VD 0;
BA_ "GenSigSendType" SG_ 973 LBMS_ChrgCurrentLimt1VD 1;
BA_ "GenSigStartValue" SG_ 973 LBMS_ChrgCurrentLimt1VD 0;
BA_ "GenSigTimeoutValue" SG_ 973 LBMS_ChrgCurrentLimt1VD 0;
BA_ "Remark" SG_ 973 LBMS_ChrgCurrentLimt1VD "";
BA_ "EventCommandSignal" SG_ 973 LBMS_ChrgCurrentLimt2VD 0;
BA_ "GatewayedSignals" SG_ 973 LBMS_ChrgCurrentLimt2VD 0;
BA_ "GenSigInactiveValue" SG_ 973 LBMS_ChrgCurrentLimt2VD 0;
BA_ "GenSigInvalidValue" SG_ 973 LBMS_ChrgCurrentLimt2VD 0;
BA_ "GenSigSendType" SG_ 973 LBMS_ChrgCurrentLimt2VD 1;
BA_ "GenSigStartValue" SG_ 973 LBMS_ChrgCurrentLimt2VD 0;
BA_ "GenSigTimeoutValue" SG_ 973 LBMS_ChrgCurrentLimt2VD 0;
BA_ "Remark" SG_ 973 LBMS_ChrgCurrentLimt2VD "";
BA_ "EventCommandSignal" SG_ 973 LBMS_Cell1Volt 0;
BA_ "GatewayedSignals" SG_ 973 LBMS_Cell1Volt 0;
BA_ "GenSigInactiveValue" SG_ 973 LBMS_Cell1Volt 0;
BA_ "GenSigInvalidValue" SG_ 973 LBMS_Cell1Volt 0;
BA_ "GenSigSendType" SG_ 973 LBMS_Cell1Volt 1;
BA_ "GenSigStartValue" SG_ 973 LBMS_Cell1Volt 8191;
BA_ "GenSigTimeoutValue" SG_ 973 LBMS_Cell1Volt 0;
BA_ "Remark" SG_ 973 LBMS_Cell1Volt "";
BA_ "EventCommandSignal" SG_ 973 LBMS_Cell1VoltVD 0;
BA_ "GatewayedSignals" SG_ 973 LBMS_Cell1VoltVD 0;
BA_ "GenSigInactiveValue" SG_ 973 LBMS_Cell1VoltVD 0;
BA_ "GenSigInvalidValue" SG_ 973 LBMS_Cell1VoltVD 0;
BA_ "GenSigSendType" SG_ 973 LBMS_Cell1VoltVD 1;
BA_ "GenSigStartValue" SG_ 973 LBMS_Cell1VoltVD 0;
BA_ "GenSigTimeoutValue" SG_ 973 LBMS_Cell1VoltVD 0;
BA_ "Remark" SG_ 973 LBMS_Cell1VoltVD "";
BA_ "EventCommandSignal" SG_ 973 LBMS_Cell2Volt 0;
BA_ "GatewayedSignals" SG_ 973 LBMS_Cell2Volt 0;
BA_ "GenSigInactiveValue" SG_ 973 LBMS_Cell2Volt 0;
BA_ "GenSigInvalidValue" SG_ 973 LBMS_Cell2Volt 0;
BA_ "GenSigSendType" SG_ 973 LBMS_Cell2Volt 1;
BA_ "GenSigStartValue" SG_ 973 LBMS_Cell2Volt 8191;
BA_ "GenSigTimeoutValue" SG_ 973 LBMS_Cell2Volt 0;
BA_ "Remark" SG_ 973 LBMS_Cell2Volt "";
BA_ "EventCommandSignal" SG_ 973 LBMS_Cell2VoltVD 0;
BA_ "GatewayedSignals" SG_ 973 LBMS_Cell2VoltVD 0;
BA_ "GenSigInactiveValue" SG_ 973 LBMS_Cell2VoltVD 0;
BA_ "GenSigInvalidValue" SG_ 973 LBMS_Cell2VoltVD 0;
BA_ "GenSigSendType" SG_ 973 LBMS_Cell2VoltVD 1;
BA_ "GenSigStartValue" SG_ 973 LBMS_Cell2VoltVD 0;
BA_ "GenSigTimeoutValue" SG_ 973 LBMS_Cell2VoltVD 0;
BA_ "Remark" SG_ 973 LBMS_Cell2VoltVD "";
BA_ "EventCommandSignal" SG_ 973 LBMS_Cell3Volt 0;
BA_ "GatewayedSignals" SG_ 973 LBMS_Cell3Volt 0;
BA_ "GenSigInactiveValue" SG_ 973 LBMS_Cell3Volt 0;
BA_ "GenSigInvalidValue" SG_ 973 LBMS_Cell3Volt 0;
BA_ "GenSigSendType" SG_ 973 LBMS_Cell3Volt 1;
BA_ "GenSigStartValue" SG_ 973 LBMS_Cell3Volt 8191;
BA_ "GenSigTimeoutValue" SG_ 973 LBMS_Cell3Volt 0;
BA_ "Remark" SG_ 973 LBMS_Cell3Volt "";
BA_ "EventCommandSignal" SG_ 973 LBMS_Cell3VoltVD 0;
BA_ "GatewayedSignals" SG_ 973 LBMS_Cell3VoltVD 0;
BA_ "GenSigInactiveValue" SG_ 973 LBMS_Cell3VoltVD 0;
BA_ "GenSigInvalidValue" SG_ 973 LBMS_Cell3VoltVD 0;
BA_ "GenSigSendType" SG_ 973 LBMS_Cell3VoltVD 1;
BA_ "GenSigStartValue" SG_ 973 LBMS_Cell3VoltVD 0;
BA_ "GenSigTimeoutValue" SG_ 973 LBMS_Cell3VoltVD 0;
BA_ "Remark" SG_ 973 LBMS_Cell3VoltVD "";
BA_ "EventCommandSignal" SG_ 973 LBMS_Cell4Volt 0;
BA_ "GatewayedSignals" SG_ 973 LBMS_Cell4Volt 0;
BA_ "GenSigInactiveValue" SG_ 973 LBMS_Cell4Volt 0;
BA_ "GenSigInvalidValue" SG_ 973 LBMS_Cell4Volt 0;
BA_ "GenSigSendType" SG_ 973 LBMS_Cell4Volt 1;
BA_ "GenSigStartValue" SG_ 973 LBMS_Cell4Volt 8191;
BA_ "GenSigTimeoutValue" SG_ 973 LBMS_Cell4Volt 0;
BA_ "Remark" SG_ 973 LBMS_Cell4Volt "";
BA_ "EventCommandSignal" SG_ 973 LBMS_Cell4VoltVD 0;
BA_ "GatewayedSignals" SG_ 973 LBMS_Cell4VoltVD 0;
BA_ "GenSigInactiveValue" SG_ 973 LBMS_Cell4VoltVD 0;
BA_ "GenSigInvalidValue" SG_ 973 LBMS_Cell4VoltVD 0;
BA_ "GenSigSendType" SG_ 973 LBMS_Cell4VoltVD 1;
BA_ "GenSigStartValue" SG_ 973 LBMS_Cell4VoltVD 0;
BA_ "GenSigTimeoutValue" SG_ 973 LBMS_Cell4VoltVD 0;
BA_ "Remark" SG_ 973 LBMS_Cell4VoltVD "";
BA_ "EventCommandSignal" SG_ 973 LBMS_CellMaxVolt 0;
BA_ "GatewayedSignals" SG_ 973 LBMS_CellMaxVolt 0;
BA_ "GenSigInactiveValue" SG_ 973 LBMS_CellMaxVolt 0;
BA_ "GenSigInvalidValue" SG_ 973 LBMS_CellMaxVolt 0;
BA_ "GenSigSendType" SG_ 973 LBMS_CellMaxVolt 1;
BA_ "GenSigStartValue" SG_ 973 LBMS_CellMaxVolt 8191;
BA_ "GenSigTimeoutValue" SG_ 973 LBMS_CellMaxVolt 0;
BA_ "Remark" SG_ 973 LBMS_CellMaxVolt "";
BA_ "EventCommandSignal" SG_ 973 LBMS_CellMinVolt 0;
BA_ "GatewayedSignals" SG_ 973 LBMS_CellMinVolt 0;
BA_ "GenSigInactiveValue" SG_ 973 LBMS_CellMinVolt 0;
BA_ "GenSigInvalidValue" SG_ 973 LBMS_CellMinVolt 0;
BA_ "GenSigSendType" SG_ 973 LBMS_CellMinVolt 1;
BA_ "GenSigStartValue" SG_ 973 LBMS_CellMinVolt 8191;
BA_ "GenSigTimeoutValue" SG_ 973 LBMS_CellMinVolt 0;
BA_ "Remark" SG_ 973 LBMS_CellMinVolt "";
BA_ "EventCommandSignal" SG_ 973 LBMS_Cell1BalanceSt 0;
BA_ "GatewayedSignals" SG_ 973 LBMS_Cell1BalanceSt 0;
BA_ "GenSigInactiveValue" SG_ 973 LBMS_Cell1BalanceSt 0;
BA_ "GenSigInvalidValue" SG_ 973 LBMS_Cell1BalanceSt 0;
BA_ "GenSigSendType" SG_ 973 LBMS_Cell1BalanceSt 1;
BA_ "GenSigStartValue" SG_ 973 LBMS_Cell1BalanceSt 0;
BA_ "GenSigTimeoutValue" SG_ 973 LBMS_Cell1BalanceSt 0;
BA_ "Remark" SG_ 973 LBMS_Cell1BalanceSt "";
BA_ "EventCommandSignal" SG_ 973 LBMS_Cell2BalanceSt 0;
BA_ "GatewayedSignals" SG_ 973 LBMS_Cell2BalanceSt 0;
BA_ "GenSigInactiveValue" SG_ 973 LBMS_Cell2BalanceSt 0;
BA_ "GenSigInvalidValue" SG_ 973 LBMS_Cell2BalanceSt 0;
BA_ "GenSigSendType" SG_ 973 LBMS_Cell2BalanceSt 1;
BA_ "GenSigStartValue" SG_ 973 LBMS_Cell2BalanceSt 0;
BA_ "GenSigTimeoutValue" SG_ 973 LBMS_Cell2BalanceSt 0;
BA_ "Remark" SG_ 973 LBMS_Cell2BalanceSt "";
BA_ "EventCommandSignal" SG_ 973 LBMS_Cell3BalanceSt 0;
BA_ "GatewayedSignals" SG_ 973 LBMS_Cell3BalanceSt 0;
BA_ "GenSigInactiveValue" SG_ 973 LBMS_Cell3BalanceSt 0;
BA_ "GenSigInvalidValue" SG_ 973 LBMS_Cell3BalanceSt 0;
BA_ "GenSigSendType" SG_ 973 LBMS_Cell3BalanceSt 1;
BA_ "GenSigStartValue" SG_ 973 LBMS_Cell3BalanceSt 0;
BA_ "GenSigTimeoutValue" SG_ 973 LBMS_Cell3BalanceSt 0;
BA_ "Remark" SG_ 973 LBMS_Cell3BalanceSt "";
BA_ "EventCommandSignal" SG_ 973 LBMS_Cell4BalanceSt 0;
BA_ "GatewayedSignals" SG_ 973 LBMS_Cell4BalanceSt 0;
BA_ "GenSigInactiveValue" SG_ 973 LBMS_Cell4BalanceSt 0;
BA_ "GenSigInvalidValue" SG_ 973 LBMS_Cell4BalanceSt 0;
BA_ "GenSigSendType" SG_ 973 LBMS_Cell4BalanceSt 1;
BA_ "GenSigStartValue" SG_ 973 LBMS_Cell4BalanceSt 0;
BA_ "GenSigTimeoutValue" SG_ 973 LBMS_Cell4BalanceSt 0;
BA_ "Remark" SG_ 973 LBMS_Cell4BalanceSt "";
BA_ "EventCommandSignal" SG_ 973 LBMS_CellTemp1 0;
BA_ "GatewayedSignals" SG_ 973 LBMS_CellTemp1 0;
BA_ "GenSigInactiveValue" SG_ 973 LBMS_CellTemp1 0;
BA_ "GenSigInvalidValue" SG_ 973 LBMS_CellTemp1 0;
BA_ "GenSigSendType" SG_ 973 LBMS_CellTemp1 1;
BA_ "GenSigStartValue" SG_ 973 LBMS_CellTemp1 255;
BA_ "GenSigTimeoutValue" SG_ 973 LBMS_CellTemp1 0;
BA_ "Remark" SG_ 973 LBMS_CellTemp1 "";
BA_ "EventCommandSignal" SG_ 973 LBMS_CellTemp2 0;
BA_ "GatewayedSignals" SG_ 973 LBMS_CellTemp2 0;
BA_ "GenSigInactiveValue" SG_ 973 LBMS_CellTemp2 0;
BA_ "GenSigInvalidValue" SG_ 973 LBMS_CellTemp2 0;
BA_ "GenSigSendType" SG_ 973 LBMS_CellTemp2 1;
BA_ "GenSigStartValue" SG_ 973 LBMS_CellTemp2 255;
BA_ "GenSigTimeoutValue" SG_ 973 LBMS_CellTemp2 0;
BA_ "Remark" SG_ 973 LBMS_CellTemp2 "";
BA_ "EventCommandSignal" SG_ 973 LBMS_CellTemp3 0;
BA_ "GatewayedSignals" SG_ 973 LBMS_CellTemp3 0;
BA_ "GenSigInactiveValue" SG_ 973 LBMS_CellTemp3 0;
BA_ "GenSigInvalidValue" SG_ 973 LBMS_CellTemp3 0;
BA_ "GenSigSendType" SG_ 973 LBMS_CellTemp3 1;
BA_ "GenSigStartValue" SG_ 973 LBMS_CellTemp3 255;
BA_ "GenSigTimeoutValue" SG_ 973 LBMS_CellTemp3 0;
BA_ "Remark" SG_ 973 LBMS_CellTemp3 "";
BA_ "EventCommandSignal" SG_ 973 LBMS_CellTemp1VD 0;
BA_ "GatewayedSignals" SG_ 973 LBMS_CellTemp1VD 0;
BA_ "GenSigInactiveValue" SG_ 973 LBMS_CellTemp1VD 0;
BA_ "GenSigInvalidValue" SG_ 973 LBMS_CellTemp1VD 0;
BA_ "GenSigSendType" SG_ 973 LBMS_CellTemp1VD 1;
BA_ "GenSigStartValue" SG_ 973 LBMS_CellTemp1VD 0;
BA_ "GenSigTimeoutValue" SG_ 973 LBMS_CellTemp1VD 0;
BA_ "Remark" SG_ 973 LBMS_CellTemp1VD "";
BA_ "EventCommandSignal" SG_ 973 LBMS_CellTemp2VD 0;
BA_ "GatewayedSignals" SG_ 973 LBMS_CellTemp2VD 0;
BA_ "GenSigInactiveValue" SG_ 973 LBMS_CellTemp2VD 0;
BA_ "GenSigInvalidValue" SG_ 973 LBMS_CellTemp2VD 0;
BA_ "GenSigSendType" SG_ 973 LBMS_CellTemp2VD 1;
BA_ "GenSigStartValue" SG_ 973 LBMS_CellTemp2VD 0;
BA_ "GenSigTimeoutValue" SG_ 973 LBMS_CellTemp2VD 0;
BA_ "Remark" SG_ 973 LBMS_CellTemp2VD "";
BA_ "EventCommandSignal" SG_ 973 LBMS_CellTemp3VD 0;
BA_ "GatewayedSignals" SG_ 973 LBMS_CellTemp3VD 0;
BA_ "GenSigInactiveValue" SG_ 973 LBMS_CellTemp3VD 0;
BA_ "GenSigInvalidValue" SG_ 973 LBMS_CellTemp3VD 0;
BA_ "GenSigSendType" SG_ 973 LBMS_CellTemp3VD 1;
BA_ "GenSigStartValue" SG_ 973 LBMS_CellTemp3VD 0;
BA_ "GenSigTimeoutValue" SG_ 973 LBMS_CellTemp3VD 0;
BA_ "Remark" SG_ 973 LBMS_CellTemp3VD "";
BA_ "EventCommandSignal" SG_ 973 LBMS_McuTemp 0;
BA_ "GatewayedSignals" SG_ 973 LBMS_McuTemp 0;
BA_ "GenSigInactiveValue" SG_ 973 LBMS_McuTemp 0;
BA_ "GenSigInvalidValue" SG_ 973 LBMS_McuTemp 0;
BA_ "GenSigSendType" SG_ 973 LBMS_McuTemp 1;
BA_ "GenSigStartValue" SG_ 973 LBMS_McuTemp 255;
BA_ "GenSigTimeoutValue" SG_ 973 LBMS_McuTemp 0;
BA_ "Remark" SG_ 973 LBMS_McuTemp "";
BA_ "EventCommandSignal" SG_ 973 LBMS_McuTempVD 0;
BA_ "GatewayedSignals" SG_ 973 LBMS_McuTempVD 0;
BA_ "GenSigInactiveValue" SG_ 973 LBMS_McuTempVD 0;
BA_ "GenSigInvalidValue" SG_ 973 LBMS_McuTempVD 0;
BA_ "GenSigSendType" SG_ 973 LBMS_McuTempVD 1;
BA_ "GenSigStartValue" SG_ 973 LBMS_McuTempVD 0;
BA_ "GenSigTimeoutValue" SG_ 973 LBMS_McuTempVD 0;
BA_ "Remark" SG_ 973 LBMS_McuTempVD "";
BA_ "EventCommandSignal" SG_ 973 LBMS_MosTemp1 0;
BA_ "GatewayedSignals" SG_ 973 LBMS_MosTemp1 0;
BA_ "GenSigInactiveValue" SG_ 973 LBMS_MosTemp1 0;
BA_ "GenSigInvalidValue" SG_ 973 LBMS_MosTemp1 0;
BA_ "GenSigSendType" SG_ 973 LBMS_MosTemp1 1;
BA_ "GenSigStartValue" SG_ 973 LBMS_MosTemp1 255;
BA_ "GenSigTimeoutValue" SG_ 973 LBMS_MosTemp1 0;
BA_ "Remark" SG_ 973 LBMS_MosTemp1 "";
BA_ "EventCommandSignal" SG_ 973 LBMS_MosTemp1VD 0;
BA_ "GatewayedSignals" SG_ 973 LBMS_MosTemp1VD 0;
BA_ "GenSigInactiveValue" SG_ 973 LBMS_MosTemp1VD 0;
BA_ "GenSigInvalidValue" SG_ 973 LBMS_MosTemp1VD 0;
BA_ "GenSigSendType" SG_ 973 LBMS_MosTemp1VD 1;
BA_ "GenSigStartValue" SG_ 973 LBMS_MosTemp1VD 0;
BA_ "GenSigTimeoutValue" SG_ 973 LBMS_MosTemp1VD 0;
BA_ "Remark" SG_ 973 LBMS_MosTemp1VD "";
BA_ "EventCommandSignal" SG_ 973 LBMS_CurrentVD 0;
BA_ "GatewayedSignals" SG_ 973 LBMS_CurrentVD 0;
BA_ "GenSigInactiveValue" SG_ 973 LBMS_CurrentVD 0;
BA_ "GenSigInvalidValue" SG_ 973 LBMS_CurrentVD 0;
BA_ "GenSigSendType" SG_ 973 LBMS_CurrentVD 1;
BA_ "GenSigStartValue" SG_ 973 LBMS_CurrentVD 0;
BA_ "GenSigTimeoutValue" SG_ 973 LBMS_CurrentVD 0;
BA_ "Remark" SG_ 973 LBMS_CurrentVD "";
BA_ "EventCommandSignal" SG_ 973 LBMS_MosTemp2 0;
BA_ "GatewayedSignals" SG_ 973 LBMS_MosTemp2 0;
BA_ "GenSigInactiveValue" SG_ 973 LBMS_MosTemp2 0;
BA_ "GenSigInvalidValue" SG_ 973 LBMS_MosTemp2 0;
BA_ "GenSigSendType" SG_ 973 LBMS_MosTemp2 1;
BA_ "GenSigStartValue" SG_ 973 LBMS_MosTemp2 255;
BA_ "GenSigTimeoutValue" SG_ 973 LBMS_MosTemp2 0;
BA_ "Remark" SG_ 973 LBMS_MosTemp2 "";
BA_ "EventCommandSignal" SG_ 973 LBMS_MosTemp2VD 0;
BA_ "GatewayedSignals" SG_ 973 LBMS_MosTemp2VD 0;
BA_ "GenSigInactiveValue" SG_ 973 LBMS_MosTemp2VD 0;
BA_ "GenSigInvalidValue" SG_ 973 LBMS_MosTemp2VD 0;
BA_ "GenSigSendType" SG_ 973 LBMS_MosTemp2VD 1;
BA_ "GenSigStartValue" SG_ 973 LBMS_MosTemp2VD 0;
BA_ "GenSigTimeoutValue" SG_ 973 LBMS_MosTemp2VD 0;
BA_ "Remark" SG_ 973 LBMS_MosTemp2VD "";
BA_ "EventCommandSignal" SG_ 973 LBMS_ShuntTemp 0;
BA_ "GatewayedSignals" SG_ 973 LBMS_ShuntTemp 0;
BA_ "GenSigInactiveValue" SG_ 973 LBMS_ShuntTemp 0;
BA_ "GenSigInvalidValue" SG_ 973 LBMS_ShuntTemp 0;
BA_ "GenSigSendType" SG_ 973 LBMS_ShuntTemp 1;
BA_ "GenSigStartValue" SG_ 973 LBMS_ShuntTemp 255;
BA_ "GenSigTimeoutValue" SG_ 973 LBMS_ShuntTemp 0;
BA_ "Remark" SG_ 973 LBMS_ShuntTemp "";
BA_ "EventCommandSignal" SG_ 973 LBMS_ShuntTempVD 0;
BA_ "GatewayedSignals" SG_ 973 LBMS_ShuntTempVD 0;
BA_ "GenSigInactiveValue" SG_ 973 LBMS_ShuntTempVD 0;
BA_ "GenSigInvalidValue" SG_ 973 LBMS_ShuntTempVD 0;
BA_ "GenSigSendType" SG_ 973 LBMS_ShuntTempVD 1;
BA_ "GenSigStartValue" SG_ 973 LBMS_ShuntTempVD 0;
BA_ "GenSigTimeoutValue" SG_ 973 LBMS_ShuntTempVD 0;
BA_ "Remark" SG_ 973 LBMS_ShuntTempVD "";
BA_ "EventCommandSignal" SG_ 973 LBMS_BalanTemp1 0;
BA_ "GatewayedSignals" SG_ 973 LBMS_BalanTemp1 0;
BA_ "GenSigInactiveValue" SG_ 973 LBMS_BalanTemp1 0;
BA_ "GenSigInvalidValue" SG_ 973 LBMS_BalanTemp1 0;
BA_ "GenSigSendType" SG_ 973 LBMS_BalanTemp1 1;
BA_ "GenSigStartValue" SG_ 973 LBMS_BalanTemp1 255;
BA_ "GenSigTimeoutValue" SG_ 973 LBMS_BalanTemp1 0;
BA_ "Remark" SG_ 973 LBMS_BalanTemp1 "";
BA_ "EventCommandSignal" SG_ 973 LBMS_BalanTemp1VD 0;
BA_ "GatewayedSignals" SG_ 973 LBMS_BalanTemp1VD 0;
BA_ "GenSigInactiveValue" SG_ 973 LBMS_BalanTemp1VD 0;
BA_ "GenSigInvalidValue" SG_ 973 LBMS_BalanTemp1VD 0;
BA_ "GenSigSendType" SG_ 973 LBMS_BalanTemp1VD 1;
BA_ "GenSigStartValue" SG_ 973 LBMS_BalanTemp1VD 0;
BA_ "GenSigTimeoutValue" SG_ 973 LBMS_BalanTemp1VD 0;
BA_ "Remark" SG_ 973 LBMS_BalanTemp1VD "";
BA_ "EventCommandSignal" SG_ 973 LBMS_BalanTemp2 0;
BA_ "GatewayedSignals" SG_ 973 LBMS_BalanTemp2 0;
BA_ "GenSigInactiveValue" SG_ 973 LBMS_BalanTemp2 0;
BA_ "GenSigInvalidValue" SG_ 973 LBMS_BalanTemp2 0;
BA_ "GenSigSendType" SG_ 973 LBMS_BalanTemp2 1;
BA_ "GenSigStartValue" SG_ 973 LBMS_BalanTemp2 255;
BA_ "GenSigTimeoutValue" SG_ 973 LBMS_BalanTemp2 0;
BA_ "Remark" SG_ 973 LBMS_BalanTemp2 "";
BA_ "EventCommandSignal" SG_ 973 LBMS_BalanTemp2VD 0;
BA_ "GatewayedSignals" SG_ 973 LBMS_BalanTemp2VD 0;
BA_ "GenSigInactiveValue" SG_ 973 LBMS_BalanTemp2VD 0;
BA_ "GenSigInvalidValue" SG_ 973 LBMS_BalanTemp2VD 0;
BA_ "GenSigSendType" SG_ 973 LBMS_BalanTemp2VD 1;
BA_ "GenSigStartValue" SG_ 973 LBMS_BalanTemp2VD 0;
BA_ "GenSigTimeoutValue" SG_ 973 LBMS_BalanTemp2VD 0;
BA_ "Remark" SG_ 973 LBMS_BalanTemp2VD "";
BA_ "EventCommandSignal" SG_ 973 LBMS_FaultSt_OVB 0;
BA_ "GatewayedSignals" SG_ 973 LBMS_FaultSt_OVB 0;
BA_ "GenSigInactiveValue" SG_ 973 LBMS_FaultSt_OVB 0;
BA_ "GenSigInvalidValue" SG_ 973 LBMS_FaultSt_OVB 0;
BA_ "GenSigSendType" SG_ 973 LBMS_FaultSt_OVB 1;
BA_ "GenSigStartValue" SG_ 973 LBMS_FaultSt_OVB 0;
BA_ "GenSigTimeoutValue" SG_ 973 LBMS_FaultSt_OVB 0;
BA_ "Remark" SG_ 973 LBMS_FaultSt_OVB "";
BA_ "EventCommandSignal" SG_ 973 LBMS_FaultSt_OVC 0;
BA_ "GatewayedSignals" SG_ 973 LBMS_FaultSt_OVC 0;
BA_ "GenSigInactiveValue" SG_ 973 LBMS_FaultSt_OVC 0;
BA_ "GenSigInvalidValue" SG_ 973 LBMS_FaultSt_OVC 0;
BA_ "GenSigSendType" SG_ 973 LBMS_FaultSt_OVC 1;
BA_ "GenSigStartValue" SG_ 973 LBMS_FaultSt_OVC 0;
BA_ "GenSigTimeoutValue" SG_ 973 LBMS_FaultSt_OVC 0;
BA_ "Remark" SG_ 973 LBMS_FaultSt_OVC "";
BA_ "EventCommandSignal" SG_ 973 LBMS_FaultSt_CVD 0;
BA_ "GatewayedSignals" SG_ 973 LBMS_FaultSt_CVD 0;
BA_ "GenSigInactiveValue" SG_ 973 LBMS_FaultSt_CVD 0;
BA_ "GenSigInvalidValue" SG_ 973 LBMS_FaultSt_CVD 0;
BA_ "GenSigSendType" SG_ 973 LBMS_FaultSt_CVD 1;
BA_ "GenSigStartValue" SG_ 973 LBMS_FaultSt_CVD 0;
BA_ "GenSigTimeoutValue" SG_ 973 LBMS_FaultSt_CVD 0;
BA_ "Remark" SG_ 973 LBMS_FaultSt_CVD "";
BA_ "EventCommandSignal" SG_ 973 LBMS_FaultSt_LVB 0;
BA_ "GatewayedSignals" SG_ 973 LBMS_FaultSt_LVB 0;
BA_ "GenSigInactiveValue" SG_ 973 LBMS_FaultSt_LVB 0;
BA_ "GenSigInvalidValue" SG_ 973 LBMS_FaultSt_LVB 0;
BA_ "GenSigSendType" SG_ 973 LBMS_FaultSt_LVB 1;
BA_ "GenSigStartValue" SG_ 973 LBMS_FaultSt_LVB 0;
BA_ "GenSigTimeoutValue" SG_ 973 LBMS_FaultSt_LVB 0;
BA_ "Remark" SG_ 973 LBMS_FaultSt_LVB "";
BA_ "EventCommandSignal" SG_ 973 LBMS_FaultSt_LVC 0;
BA_ "GatewayedSignals" SG_ 973 LBMS_FaultSt_LVC 0;
BA_ "GenSigInactiveValue" SG_ 973 LBMS_FaultSt_LVC 0;
BA_ "GenSigInvalidValue" SG_ 973 LBMS_FaultSt_LVC 0;
BA_ "GenSigSendType" SG_ 973 LBMS_FaultSt_LVC 1;
BA_ "GenSigStartValue" SG_ 973 LBMS_FaultSt_LVC 0;
BA_ "GenSigTimeoutValue" SG_ 973 LBMS_FaultSt_LVC 0;
BA_ "Remark" SG_ 973 LBMS_FaultSt_LVC "";
BA_ "EventCommandSignal" SG_ 973 LBMS_FaultSt_OTB 0;
BA_ "GatewayedSignals" SG_ 973 LBMS_FaultSt_OTB 0;
BA_ "GenSigInactiveValue" SG_ 973 LBMS_FaultSt_OTB 0;
BA_ "GenSigInvalidValue" SG_ 973 LBMS_FaultSt_OTB 0;
BA_ "GenSigSendType" SG_ 973 LBMS_FaultSt_OTB 1;
BA_ "GenSigStartValue" SG_ 973 LBMS_FaultSt_OTB 0;
BA_ "GenSigTimeoutValue" SG_ 973 LBMS_FaultSt_OTB 0;
BA_ "Remark" SG_ 973 LBMS_FaultSt_OTB "";
BA_ "EventCommandSignal" SG_ 973 LBMS_FaultSt_OTMC 0;
BA_ "GatewayedSignals" SG_ 973 LBMS_FaultSt_OTMC 0;
BA_ "GenSigInactiveValue" SG_ 973 LBMS_FaultSt_OTMC 0;
BA_ "GenSigInvalidValue" SG_ 973 LBMS_FaultSt_OTMC 0;
BA_ "GenSigSendType" SG_ 973 LBMS_FaultSt_OTMC 1;
BA_ "GenSigStartValue" SG_ 973 LBMS_FaultSt_OTMC 0;
BA_ "GenSigTimeoutValue" SG_ 973 LBMS_FaultSt_OTMC 0;
BA_ "Remark" SG_ 973 LBMS_FaultSt_OTMC "";
BA_ "EventCommandSignal" SG_ 973 LBMS_FaultSt_OTMO 0;
BA_ "GatewayedSignals" SG_ 973 LBMS_FaultSt_OTMO 0;
BA_ "GenSigInactiveValue" SG_ 973 LBMS_FaultSt_OTMO 0;
BA_ "GenSigInvalidValue" SG_ 973 LBMS_FaultSt_OTMO 0;
BA_ "GenSigSendType" SG_ 973 LBMS_FaultSt_OTMO 1;
BA_ "GenSigStartValue" SG_ 973 LBMS_FaultSt_OTMO 0;
BA_ "GenSigTimeoutValue" SG_ 973 LBMS_FaultSt_OTMO 0;
BA_ "Remark" SG_ 973 LBMS_FaultSt_OTMO "";
BA_ "EventCommandSignal" SG_ 973 LBMS_FaultSt_OTS 0;
BA_ "GatewayedSignals" SG_ 973 LBMS_FaultSt_OTS 0;
BA_ "GenSigInactiveValue" SG_ 973 LBMS_FaultSt_OTS 0;
BA_ "GenSigInvalidValue" SG_ 973 LBMS_FaultSt_OTS 0;
BA_ "GenSigSendType" SG_ 973 LBMS_FaultSt_OTS 1;
BA_ "GenSigStartValue" SG_ 973 LBMS_FaultSt_OTS 0;
BA_ "GenSigTimeoutValue" SG_ 973 LBMS_FaultSt_OTS 0;
BA_ "Remark" SG_ 973 LBMS_FaultSt_OTS "";
BA_ "EventCommandSignal" SG_ 973 LBMS_FaultSt_OTCB 0;
BA_ "GatewayedSignals" SG_ 973 LBMS_FaultSt_OTCB 0;
BA_ "GenSigInactiveValue" SG_ 973 LBMS_FaultSt_OTCB 0;
BA_ "GenSigInvalidValue" SG_ 973 LBMS_FaultSt_OTCB 0;
BA_ "GenSigSendType" SG_ 973 LBMS_FaultSt_OTCB 1;
BA_ "GenSigStartValue" SG_ 973 LBMS_FaultSt_OTCB 0;
BA_ "GenSigTimeoutValue" SG_ 973 LBMS_FaultSt_OTCB 0;
BA_ "Remark" SG_ 973 LBMS_FaultSt_OTCB "";
BA_ "EventCommandSignal" SG_ 973 LBMS_FaultSt_CTD 0;
BA_ "GatewayedSignals" SG_ 973 LBMS_FaultSt_CTD 0;
BA_ "GenSigInactiveValue" SG_ 973 LBMS_FaultSt_CTD 0;
BA_ "GenSigInvalidValue" SG_ 973 LBMS_FaultSt_CTD 0;
BA_ "GenSigSendType" SG_ 973 LBMS_FaultSt_CTD 1;
BA_ "GenSigStartValue" SG_ 973 LBMS_FaultSt_CTD 0;
BA_ "GenSigTimeoutValue" SG_ 973 LBMS_FaultSt_CTD 0;
BA_ "Remark" SG_ 973 LBMS_FaultSt_CTD "";
BA_ "EventCommandSignal" SG_ 973 LBMS_FaultSt_LT 0;
BA_ "GatewayedSignals" SG_ 973 LBMS_FaultSt_LT 0;
BA_ "GenSigInactiveValue" SG_ 973 LBMS_FaultSt_LT 0;
BA_ "GenSigInvalidValue" SG_ 973 LBMS_FaultSt_LT 0;
BA_ "GenSigSendType" SG_ 973 LBMS_FaultSt_LT 1;
BA_ "GenSigStartValue" SG_ 973 LBMS_FaultSt_LT 0;
BA_ "GenSigTimeoutValue" SG_ 973 LBMS_FaultSt_LT 0;
BA_ "Remark" SG_ 973 LBMS_FaultSt_LT "";
BA_ "EventCommandSignal" SG_ 973 LBMS_FaultSt_ChgOC 0;
BA_ "GatewayedSignals" SG_ 973 LBMS_FaultSt_ChgOC 0;
BA_ "GenSigInactiveValue" SG_ 973 LBMS_FaultSt_ChgOC 0;
BA_ "GenSigInvalidValue" SG_ 973 LBMS_FaultSt_ChgOC 0;
BA_ "GenSigSendType" SG_ 973 LBMS_FaultSt_ChgOC 1;
BA_ "GenSigStartValue" SG_ 973 LBMS_FaultSt_ChgOC 0;
BA_ "GenSigTimeoutValue" SG_ 973 LBMS_FaultSt_ChgOC 0;
BA_ "Remark" SG_ 973 LBMS_FaultSt_ChgOC "";
BA_ "EventCommandSignal" SG_ 973 LBMS_FaultSt_DsgOC 0;
BA_ "GatewayedSignals" SG_ 973 LBMS_FaultSt_DsgOC 0;
BA_ "GenSigInactiveValue" SG_ 973 LBMS_FaultSt_DsgOC 0;
BA_ "GenSigInvalidValue" SG_ 973 LBMS_FaultSt_DsgOC 0;
BA_ "GenSigSendType" SG_ 973 LBMS_FaultSt_DsgOC 1;
BA_ "GenSigStartValue" SG_ 973 LBMS_FaultSt_DsgOC 0;
BA_ "GenSigTimeoutValue" SG_ 973 LBMS_FaultSt_DsgOC 0;
BA_ "Remark" SG_ 973 LBMS_FaultSt_DsgOC "";
BA_ "EventCommandSignal" SG_ 973 LBMS_FaultSt_Hard_CellVolCol 0;
BA_ "GatewayedSignals" SG_ 973 LBMS_FaultSt_Hard_CellVolCol 0;
BA_ "GenSigInactiveValue" SG_ 973 LBMS_FaultSt_Hard_CellVolCol 0;
BA_ "GenSigInvalidValue" SG_ 973 LBMS_FaultSt_Hard_CellVolCol 0;
BA_ "GenSigSendType" SG_ 973 LBMS_FaultSt_Hard_CellVolCol 1;
BA_ "GenSigStartValue" SG_ 973 LBMS_FaultSt_Hard_CellVolCol 0;
BA_ "GenSigTimeoutValue" SG_ 973 LBMS_FaultSt_Hard_CellVolCol 0;
BA_ "Remark" SG_ 973 LBMS_FaultSt_Hard_CellVolCol "";
BA_ "EventCommandSignal" SG_ 973 LBMS_FaultSt_Hard_TempColBat 0;
BA_ "GatewayedSignals" SG_ 973 LBMS_FaultSt_Hard_TempColBat 0;
BA_ "GenSigInactiveValue" SG_ 973 LBMS_FaultSt_Hard_TempColBat 0;
BA_ "GenSigInvalidValue" SG_ 973 LBMS_FaultSt_Hard_TempColBat 0;
BA_ "GenSigSendType" SG_ 973 LBMS_FaultSt_Hard_TempColBat 1;
BA_ "GenSigStartValue" SG_ 973 LBMS_FaultSt_Hard_TempColBat 0;
BA_ "GenSigTimeoutValue" SG_ 973 LBMS_FaultSt_Hard_TempColBat 0;
BA_ "Remark" SG_ 973 LBMS_FaultSt_Hard_TempColBat "";
BA_ "EventCommandSignal" SG_ 973 LBMS_FaultSt_Hard_TemColMOS 0;
BA_ "GatewayedSignals" SG_ 973 LBMS_FaultSt_Hard_TemColMOS 0;
BA_ "GenSigInactiveValue" SG_ 973 LBMS_FaultSt_Hard_TemColMOS 0;
BA_ "GenSigInvalidValue" SG_ 973 LBMS_FaultSt_Hard_TemColMOS 0;
BA_ "GenSigSendType" SG_ 973 LBMS_FaultSt_Hard_TemColMOS 1;
BA_ "GenSigStartValue" SG_ 973 LBMS_FaultSt_Hard_TemColMOS 0;
BA_ "GenSigTimeoutValue" SG_ 973 LBMS_FaultSt_Hard_TemColMOS 0;
BA_ "Remark" SG_ 973 LBMS_FaultSt_Hard_TemColMOS "";
BA_ "EventCommandSignal" SG_ 973 LBMS_FaultSt_Hard_TemColMCU 0;
BA_ "GatewayedSignals" SG_ 973 LBMS_FaultSt_Hard_TemColMCU 0;
BA_ "GenSigInactiveValue" SG_ 973 LBMS_FaultSt_Hard_TemColMCU 0;
BA_ "GenSigInvalidValue" SG_ 973 LBMS_FaultSt_Hard_TemColMCU 0;
BA_ "GenSigSendType" SG_ 973 LBMS_FaultSt_Hard_TemColMCU 1;
BA_ "GenSigStartValue" SG_ 973 LBMS_FaultSt_Hard_TemColMCU 0;
BA_ "GenSigTimeoutValue" SG_ 973 LBMS_FaultSt_Hard_TemColMCU 0;
BA_ "Remark" SG_ 973 LBMS_FaultSt_Hard_TemColMCU "";
BA_ "EventCommandSignal" SG_ 973 LBMS_FaultSt_Hard_Shunt 0;
BA_ "GatewayedSignals" SG_ 973 LBMS_FaultSt_Hard_Shunt 0;
BA_ "GenSigInactiveValue" SG_ 973 LBMS_FaultSt_Hard_Shunt 0;
BA_ "GenSigInvalidValue" SG_ 973 LBMS_FaultSt_Hard_Shunt 0;
BA_ "GenSigSendType" SG_ 973 LBMS_FaultSt_Hard_Shunt 1;
BA_ "GenSigStartValue" SG_ 973 LBMS_FaultSt_Hard_Shunt 0;
BA_ "GenSigTimeoutValue" SG_ 973 LBMS_FaultSt_Hard_Shunt 0;
BA_ "Remark" SG_ 973 LBMS_FaultSt_Hard_Shunt "";
BA_ "EventCommandSignal" SG_ 973 LBMS_FaultSt_Hard_ChgMOS 0;
BA_ "GatewayedSignals" SG_ 973 LBMS_FaultSt_Hard_ChgMOS 0;
BA_ "GenSigInactiveValue" SG_ 973 LBMS_FaultSt_Hard_ChgMOS 0;
BA_ "GenSigInvalidValue" SG_ 973 LBMS_FaultSt_Hard_ChgMOS 0;
BA_ "GenSigSendType" SG_ 973 LBMS_FaultSt_Hard_ChgMOS 1;
BA_ "GenSigStartValue" SG_ 973 LBMS_FaultSt_Hard_ChgMOS 0;
BA_ "GenSigTimeoutValue" SG_ 973 LBMS_FaultSt_Hard_ChgMOS 0;
BA_ "Remark" SG_ 973 LBMS_FaultSt_Hard_ChgMOS "";
BA_ "EventCommandSignal" SG_ 973 LBMS_FaultSt_Hard_DsgMOS 0;
BA_ "GatewayedSignals" SG_ 973 LBMS_FaultSt_Hard_DsgMOS 0;
BA_ "GenSigInactiveValue" SG_ 973 LBMS_FaultSt_Hard_DsgMOS 0;
BA_ "GenSigInvalidValue" SG_ 973 LBMS_FaultSt_Hard_DsgMOS 0;
BA_ "GenSigSendType" SG_ 973 LBMS_FaultSt_Hard_DsgMOS 1;
BA_ "GenSigStartValue" SG_ 973 LBMS_FaultSt_Hard_DsgMOS 0;
BA_ "GenSigTimeoutValue" SG_ 973 LBMS_FaultSt_Hard_DsgMOS 0;
BA_ "Remark" SG_ 973 LBMS_FaultSt_Hard_DsgMOS "";
BA_ "EventCommandSignal" SG_ 973 LBMS_FaultSt_Hard_AFE 0;
BA_ "GatewayedSignals" SG_ 973 LBMS_FaultSt_Hard_AFE 0;
BA_ "GenSigInactiveValue" SG_ 973 LBMS_FaultSt_Hard_AFE 0;
BA_ "GenSigInvalidValue" SG_ 973 LBMS_FaultSt_Hard_AFE 0;
BA_ "GenSigSendType" SG_ 973 LBMS_FaultSt_Hard_AFE 1;
BA_ "GenSigStartValue" SG_ 973 LBMS_FaultSt_Hard_AFE 0;
BA_ "GenSigTimeoutValue" SG_ 973 LBMS_FaultSt_Hard_AFE 0;
BA_ "Remark" SG_ 973 LBMS_FaultSt_Hard_AFE "";
BA_ "EventCommandSignal" SG_ 973 LBMS_FaultSt_Hard_MCU 0;
BA_ "GatewayedSignals" SG_ 973 LBMS_FaultSt_Hard_MCU 0;
BA_ "GenSigInactiveValue" SG_ 973 LBMS_FaultSt_Hard_MCU 0;
BA_ "GenSigInvalidValue" SG_ 973 LBMS_FaultSt_Hard_MCU 0;
BA_ "GenSigSendType" SG_ 973 LBMS_FaultSt_Hard_MCU 1;
BA_ "GenSigStartValue" SG_ 973 LBMS_FaultSt_Hard_MCU 0;
BA_ "GenSigTimeoutValue" SG_ 973 LBMS_FaultSt_Hard_MCU 0;
BA_ "Remark" SG_ 973 LBMS_FaultSt_Hard_MCU "";
BA_ "EventCommandSignal" SG_ 973 LBMS_FaultSt_Hard_SBC 0;
BA_ "GatewayedSignals" SG_ 973 LBMS_FaultSt_Hard_SBC 0;
BA_ "GenSigInactiveValue" SG_ 973 LBMS_FaultSt_Hard_SBC 0;
BA_ "GenSigInvalidValue" SG_ 973 LBMS_FaultSt_Hard_SBC 0;
BA_ "GenSigSendType" SG_ 973 LBMS_FaultSt_Hard_SBC 1;
BA_ "GenSigStartValue" SG_ 973 LBMS_FaultSt_Hard_SBC 0;
BA_ "GenSigTimeoutValue" SG_ 973 LBMS_FaultSt_Hard_SBC 0;
BA_ "Remark" SG_ 973 LBMS_FaultSt_Hard_SBC "";
BA_ "EventCommandSignal" SG_ 973 LBMS_FaultSt_Hard_DCDC 0;
BA_ "GatewayedSignals" SG_ 973 LBMS_FaultSt_Hard_DCDC 0;
BA_ "GenSigInactiveValue" SG_ 973 LBMS_FaultSt_Hard_DCDC 0;
BA_ "GenSigInvalidValue" SG_ 973 LBMS_FaultSt_Hard_DCDC 0;
BA_ "GenSigSendType" SG_ 973 LBMS_FaultSt_Hard_DCDC 1;
BA_ "GenSigStartValue" SG_ 973 LBMS_FaultSt_Hard_DCDC 0;
BA_ "GenSigTimeoutValue" SG_ 973 LBMS_FaultSt_Hard_DCDC 0;
BA_ "Remark" SG_ 973 LBMS_FaultSt_Hard_DCDC "";
BA_ "EventCommandSignal" SG_ 973 LBMS_FaultSt_CANBusOff 0;
BA_ "GatewayedSignals" SG_ 973 LBMS_FaultSt_CANBusOff 0;
BA_ "GenSigInactiveValue" SG_ 973 LBMS_FaultSt_CANBusOff 0;
BA_ "GenSigInvalidValue" SG_ 973 LBMS_FaultSt_CANBusOff 0;
BA_ "GenSigSendType" SG_ 973 LBMS_FaultSt_CANBusOff 1;
BA_ "GenSigStartValue" SG_ 973 LBMS_FaultSt_CANBusOff 0;
BA_ "GenSigTimeoutValue" SG_ 973 LBMS_FaultSt_CANBusOff 0;
BA_ "Remark" SG_ 973 LBMS_FaultSt_CANBusOff "";
BA_ "EventCommandSignal" SG_ 973 LBMS_FaultSt_CANTimeOut 0;
BA_ "GatewayedSignals" SG_ 973 LBMS_FaultSt_CANTimeOut 0;
BA_ "GenSigInactiveValue" SG_ 973 LBMS_FaultSt_CANTimeOut 0;
BA_ "GenSigInvalidValue" SG_ 973 LBMS_FaultSt_CANTimeOut 0;
BA_ "GenSigSendType" SG_ 973 LBMS_FaultSt_CANTimeOut 1;
BA_ "GenSigStartValue" SG_ 973 LBMS_FaultSt_CANTimeOut 0;
BA_ "GenSigTimeoutValue" SG_ 973 LBMS_FaultSt_CANTimeOut 0;
BA_ "Remark" SG_ 973 LBMS_FaultSt_CANTimeOut "";
BA_ "EventCommandSignal" SG_ 973 LBMS_FaultSt_CANCrcErr 0;
BA_ "GatewayedSignals" SG_ 973 LBMS_FaultSt_CANCrcErr 0;
BA_ "GenSigInactiveValue" SG_ 973 LBMS_FaultSt_CANCrcErr 0;
BA_ "GenSigInvalidValue" SG_ 973 LBMS_FaultSt_CANCrcErr 0;
BA_ "GenSigSendType" SG_ 973 LBMS_FaultSt_CANCrcErr 1;
BA_ "GenSigStartValue" SG_ 973 LBMS_FaultSt_CANCrcErr 0;
BA_ "GenSigTimeoutValue" SG_ 973 LBMS_FaultSt_CANCrcErr 0;
BA_ "Remark" SG_ 973 LBMS_FaultSt_CANCrcErr "";
BA_ "EventCommandSignal" SG_ 973 LBMS_CumuChargeAh 0;
BA_ "GatewayedSignals" SG_ 973 LBMS_CumuChargeAh 0;
BA_ "GenSigInactiveValue" SG_ 973 LBMS_CumuChargeAh 0;
BA_ "GenSigInvalidValue" SG_ 973 LBMS_CumuChargeAh 0;
BA_ "GenSigSendType" SG_ 973 LBMS_CumuChargeAh 1;
BA_ "GenSigStartValue" SG_ 973 LBMS_CumuChargeAh 0;
BA_ "GenSigTimeoutValue" SG_ 973 LBMS_CumuChargeAh 0;
BA_ "Remark" SG_ 973 LBMS_CumuChargeAh "";
BA_ "EventCommandSignal" SG_ 973 LBMS_CumuDischargeAh 0;
BA_ "GatewayedSignals" SG_ 973 LBMS_CumuDischargeAh 0;
BA_ "GenSigInactiveValue" SG_ 973 LBMS_CumuDischargeAh 0;
BA_ "GenSigInvalidValue" SG_ 973 LBMS_CumuDischargeAh 0;
BA_ "GenSigSendType" SG_ 973 LBMS_CumuDischargeAh 1;
BA_ "GenSigStartValue" SG_ 973 LBMS_CumuDischargeAh 0;
BA_ "GenSigTimeoutValue" SG_ 973 LBMS_CumuDischargeAh 0;
BA_ "Remark" SG_ 973 LBMS_CumuDischargeAh "";
BA_ "EventCommandSignal" SG_ 973 LBMS_LastFullChargeAh 0;
BA_ "GatewayedSignals" SG_ 973 LBMS_LastFullChargeAh 0;
BA_ "GenSigInactiveValue" SG_ 973 LBMS_LastFullChargeAh 0;
BA_ "GenSigInvalidValue" SG_ 973 LBMS_LastFullChargeAh 0;
BA_ "GenSigSendType" SG_ 973 LBMS_LastFullChargeAh 1;
BA_ "GenSigStartValue" SG_ 973 LBMS_LastFullChargeAh 0;
BA_ "GenSigTimeoutValue" SG_ 973 LBMS_LastFullChargeAh 0;
BA_ "Remark" SG_ 973 LBMS_LastFullChargeAh "";
BA_ "EventCommandSignal" SG_ 973 LBMS_HisLockPackSt 0;
BA_ "GatewayedSignals" SG_ 973 LBMS_HisLockPackSt 0;
BA_ "GenSigInactiveValue" SG_ 973 LBMS_HisLockPackSt 0;
BA_ "GenSigInvalidValue" SG_ 973 LBMS_HisLockPackSt 0;
BA_ "GenSigSendType" SG_ 973 LBMS_HisLockPackSt 1;
BA_ "GenSigStartValue" SG_ 973 LBMS_HisLockPackSt 0;
BA_ "GenSigTimeoutValue" SG_ 973 LBMS_HisLockPackSt 0;
BA_ "Remark" SG_ 973 LBMS_HisLockPackSt "";
BA_ "EventCommandSignal" SG_ 973 LBMS_CurentLockPackSt 0;
BA_ "GatewayedSignals" SG_ 973 LBMS_CurentLockPackSt 0;
BA_ "GenSigInactiveValue" SG_ 973 LBMS_CurentLockPackSt 0;
BA_ "GenSigInvalidValue" SG_ 973 LBMS_CurentLockPackSt 0;
BA_ "GenSigSendType" SG_ 973 LBMS_CurentLockPackSt 1;
BA_ "GenSigStartValue" SG_ 973 LBMS_CurentLockPackSt 0;
BA_ "GenSigTimeoutValue" SG_ 973 LBMS_CurentLockPackSt 0;
BA_ "Remark" SG_ 973 LBMS_CurentLockPackSt "";
BA_ "EventCommandSignal" SG_ 973 LBMS_ExternalCharging 0;
BA_ "GatewayedSignals" SG_ 973 LBMS_ExternalCharging 0;
BA_ "GenSigInactiveValue" SG_ 973 LBMS_ExternalCharging 0;
BA_ "GenSigInvalidValue" SG_ 973 LBMS_ExternalCharging 0;
BA_ "GenSigSendType" SG_ 973 LBMS_ExternalCharging 1;
BA_ "GenSigStartValue" SG_ 973 LBMS_ExternalCharging 0;
BA_ "GenSigTimeoutValue" SG_ 973 LBMS_ExternalCharging 0;
BA_ "Remark" SG_ 973 LBMS_ExternalCharging "";
BA_ "EventCommandSignal" SG_ 973 LBMS_LastFullChargeTime 0;
BA_ "GatewayedSignals" SG_ 973 LBMS_LastFullChargeTime 0;
BA_ "GenSigInactiveValue" SG_ 973 LBMS_LastFullChargeTime 0;
BA_ "GenSigInvalidValue" SG_ 973 LBMS_LastFullChargeTime 0;
BA_ "GenSigSendType" SG_ 973 LBMS_LastFullChargeTime 1;
BA_ "GenSigStartValue" SG_ 973 LBMS_LastFullChargeTime 0;
BA_ "GenSigTimeoutValue" SG_ 973 LBMS_LastFullChargeTime 0;
BA_ "Remark" SG_ 973 LBMS_LastFullChargeTime "";
BA_ "EventCommandSignal" SG_ 973 LBMS_StaticTime 0;
BA_ "GatewayedSignals" SG_ 973 LBMS_StaticTime 0;
BA_ "GenSigInactiveValue" SG_ 973 LBMS_StaticTime 0;
BA_ "GenSigInvalidValue" SG_ 973 LBMS_StaticTime 0;
BA_ "GenSigSendType" SG_ 973 LBMS_StaticTime 1;
BA_ "GenSigStartValue" SG_ 973 LBMS_StaticTime 0;
BA_ "GenSigTimeoutValue" SG_ 973 LBMS_StaticTime 0;
BA_ "Remark" SG_ 973 LBMS_StaticTime "";
BA_ "EventCommandSignal" SG_ 973 LBMS_AppVersionFirst 0;
BA_ "GatewayedSignals" SG_ 973 LBMS_AppVersionFirst 0;
BA_ "GenSigInactiveValue" SG_ 973 LBMS_AppVersionFirst 0;
BA_ "GenSigInvalidValue" SG_ 973 LBMS_AppVersionFirst 0;
BA_ "GenSigSendType" SG_ 973 LBMS_AppVersionFirst 1;
BA_ "GenSigStartValue" SG_ 973 LBMS_AppVersionFirst 0;
BA_ "GenSigTimeoutValue" SG_ 973 LBMS_AppVersionFirst 0;
BA_ "Remark" SG_ 973 LBMS_AppVersionFirst "";
BA_ "EventCommandSignal" SG_ 973 LBMS_AppVersionSecond 0;
BA_ "GatewayedSignals" SG_ 973 LBMS_AppVersionSecond 0;
BA_ "GenSigInactiveValue" SG_ 973 LBMS_AppVersionSecond 0;
BA_ "GenSigInvalidValue" SG_ 973 LBMS_AppVersionSecond 0;
BA_ "GenSigSendType" SG_ 973 LBMS_AppVersionSecond 1;
BA_ "GenSigStartValue" SG_ 973 LBMS_AppVersionSecond 0;
BA_ "GenSigTimeoutValue" SG_ 973 LBMS_AppVersionSecond 0;
BA_ "Remark" SG_ 973 LBMS_AppVersionSecond "";
BA_ "EventCommandSignal" SG_ 973 LBMS_AppVersionThird 0;
BA_ "GatewayedSignals" SG_ 973 LBMS_AppVersionThird 0;
BA_ "GenSigInactiveValue" SG_ 973 LBMS_AppVersionThird 0;
BA_ "GenSigInvalidValue" SG_ 973 LBMS_AppVersionThird 0;
BA_ "GenSigSendType" SG_ 973 LBMS_AppVersionThird 1;
BA_ "GenSigStartValue" SG_ 973 LBMS_AppVersionThird 0;
BA_ "GenSigTimeoutValue" SG_ 973 LBMS_AppVersionThird 0;
BA_ "Remark" SG_ 973 LBMS_AppVersionThird "";
BA_ "EventCommandSignal" SG_ 973 LBMS_BootVersionFirst 0;
BA_ "GatewayedSignals" SG_ 973 LBMS_BootVersionFirst 0;
BA_ "GenSigInactiveValue" SG_ 973 LBMS_BootVersionFirst 0;
BA_ "GenSigInvalidValue" SG_ 973 LBMS_BootVersionFirst 0;
BA_ "GenSigSendType" SG_ 973 LBMS_BootVersionFirst 1;
BA_ "GenSigStartValue" SG_ 973 LBMS_BootVersionFirst 0;
BA_ "GenSigTimeoutValue" SG_ 973 LBMS_BootVersionFirst 0;
BA_ "Remark" SG_ 973 LBMS_BootVersionFirst "";
BA_ "EventCommandSignal" SG_ 973 LBMS_BootVersionSecond 0;
BA_ "GatewayedSignals" SG_ 973 LBMS_BootVersionSecond 0;
BA_ "GenSigInactiveValue" SG_ 973 LBMS_BootVersionSecond 0;
BA_ "GenSigInvalidValue" SG_ 973 LBMS_BootVersionSecond 0;
BA_ "GenSigSendType" SG_ 973 LBMS_BootVersionSecond 1;
BA_ "GenSigStartValue" SG_ 973 LBMS_BootVersionSecond 0;
BA_ "GenSigTimeoutValue" SG_ 973 LBMS_BootVersionSecond 0;
BA_ "Remark" SG_ 973 LBMS_BootVersionSecond "";
BA_ "EventCommandSignal" SG_ 973 LBMS_HwVersion 0;
BA_ "GatewayedSignals" SG_ 973 LBMS_HwVersion 0;
BA_ "GenSigInactiveValue" SG_ 973 LBMS_HwVersion 0;
BA_ "GenSigInvalidValue" SG_ 973 LBMS_HwVersion 0;
BA_ "GenSigSendType" SG_ 973 LBMS_HwVersion 1;
BA_ "GenSigStartValue" SG_ 973 LBMS_HwVersion 0;
BA_ "GenSigTimeoutValue" SG_ 973 LBMS_HwVersion 0;
BA_ "Remark" SG_ 973 LBMS_HwVersion "";
BA_ "EventCommandSignal" SG_ 973 LBMS_Supplier 0;
BA_ "GatewayedSignals" SG_ 973 LBMS_Supplier 0;
BA_ "GenSigInactiveValue" SG_ 973 LBMS_Supplier 0;
BA_ "GenSigInvalidValue" SG_ 973 LBMS_Supplier 0;
BA_ "GenSigSendType" SG_ 973 LBMS_Supplier 1;
BA_ "GenSigStartValue" SG_ 973 LBMS_Supplier 0;
BA_ "GenSigTimeoutValue" SG_ 973 LBMS_Supplier 0;
BA_ "Remark" SG_ 973 LBMS_Supplier "";
BA_ "EventCommandSignal" SG_ 973 LBMS_UpackRvsVolt 0;
BA_ "GatewayedSignals" SG_ 973 LBMS_UpackRvsVolt 0;
BA_ "GenSigInactiveValue" SG_ 973 LBMS_UpackRvsVolt 0;
BA_ "GenSigInvalidValue" SG_ 973 LBMS_UpackRvsVolt 0;
BA_ "GenSigSendType" SG_ 973 LBMS_UpackRvsVolt 1;
BA_ "GenSigStartValue" SG_ 973 LBMS_UpackRvsVolt 4095;
BA_ "GenSigTimeoutValue" SG_ 973 LBMS_UpackRvsVolt 0;
BA_ "Remark" SG_ 973 LBMS_UpackRvsVolt "";
BA_ "EventCommandSignal" SG_ 973 LBMS_UpackRvsVoltVD 0;
BA_ "GatewayedSignals" SG_ 973 LBMS_UpackRvsVoltVD 0;
BA_ "GenSigInactiveValue" SG_ 973 LBMS_UpackRvsVoltVD 0;
BA_ "GenSigInvalidValue" SG_ 973 LBMS_UpackRvsVoltVD 0;
BA_ "GenSigSendType" SG_ 973 LBMS_UpackRvsVoltVD 1;
BA_ "GenSigStartValue" SG_ 973 LBMS_UpackRvsVoltVD 0;
BA_ "GenSigTimeoutValue" SG_ 973 LBMS_UpackRvsVoltVD 0;
BA_ "Remark" SG_ 973 LBMS_UpackRvsVoltVD "";

VAL_ 998 VCU_LVBatFillSt_1 0 "Not active" 1 "Ongoing" 2 "Rejected : Low Power" 3 "Rejected : Vehicle is ready" 4 "Rejected : Error" 5 "Aborted : Low power" 6 "Aborted : Crank received" 7 "Aborted : Energy accumula-tion" 8 "Aborted : Max time reached" 9 "Aborted : Error" 10 "Stop : Received stop re-quest" 11 "Reserved" 12 "Reserved" 13 "Reserved" 14 "Reserved" 15 "Reserved"  ;
VAL_ 616 UMM_UsageModeSt 0 "Standby" 1 "Comfort" 2 "Reserved" 3 "DRV" 4 "Reserved" 5 "Reserved" 6 "Reserved" 7 "Invalid"  ;
VAL_ 616 VMM_VehModeSt 0 "Normal Mode" 1 "Manufacture Mode" 2 "Transport Mode" 3 "Showroom Mode" 4 "PostCrash Mode" 5 "Maintenance Mode" 6 "Reserved" 7 "Reserved" 8 "Reserved" 9 "Reserved" 10 "Reserved" 11 "Reserved" 12 "Reserved" 13 "Reserved" 14 "Reserved" 15 "Invalid Value"  ;
VAL_ 616 VMM_OTAModeSt 0 "NonOTA Mode" 1 "OTA Mode" 2 "Invalid Value" 3 "reserved"  ;
VAL_ 1359 CCU_NMCBV 0 "Node has not woken up the    network(passive wakeup);" 1 "Node has woken up the network(active wakeup)" 0 "NM PDU contains no Partial Network request information" 1 "NM PDU contains Partial Network request information"  ;
VAL_ 1359 CCU_NMWakeupOrigin 0 "Reserved" 1 "CAN channel 0" 2 "CAN channel 1" 3 "CAN channel 2" 4 "CAN channel 3" 5 "CAN channel 4" 6 "CAN channel 5" 7 "CAN channel 6" 8 "CAN channel 7" 9 "CAN channel 8" 10 "CAN channel 9" 11 "CAN channel 10" 12 "CAN channel 11" 13 "CAN channel 12" 14 "CAN channel 13" 15 "CAN channel 14" 16 "CAN channel 15" 17 "Reserved" 18 "Reserved" 19 "Reserved" 20 "AcoreRequest" 21 "Reserved" 22 "Reserved" 23 "Reserved" 24 "Reserved" 25 "Reserved" 26 "Reserved" 27 "Reserved" 28 "Reserved" 29 "Reserved" 30 "Reserved" 31 "Reserved" 32 "Reserved" 33 "Reserved" 34 "Reserved" 35 "Reserved" 36 "Reserved" 37 "Reserved" 38 "Reserved" 39 "Reserved" 40 "Reserved" 41 "Reserved" 42 "Reserved" 43 "Reserved" 44 "Reserved" 45 "Reserved" 46 "Reserved" 47 "Reserved" 48 "Reserved" 49 "Reserved" 50 "UsageModeSt" 51 "NMiDPSNMKeepAwakeFlag" 52 "NMEEMKeepAwakeFlag" 53 "NMEEMKeepAwakeFlag_Aux" 54 "NMVCUGlobalKeepAwakeFlag" 55 "NMVCUChargingKeepAwakeFlag（新能源，VCU_hcu）" 56 "DoIPActiveLineStatus" 57 "NMBMSGlobalKeepAwakeFlag" 58 "NMBMSChargingKeepAwakeFlag" 59 "NMBMSThermalRunawayKeepAwakeFlag（新能源，BMS）" 60 "Reserved" 61 "NMBMSThermalRunawayKeepAwakeFlag （动力，VCU_slccu）" 62 "NMVCUChargingKeepAwakeFlag（动力，VCU_slccu）" 63 "NMVCU2GlobalKeepAwakeFlag" 64 "NMVHMKeepAwakeFlag" 65 "Reserved" 66 "CSM_RC_KeepAwake" 67 "NMHVACKeepAwakeFlag（新能源，TMS）" 68 "Reserved" 69 "Reserved" 70 "BDC_NMBDCKeepAwakeFlag" 71 "NMTMSChargingKeepAwakeFlag" 72 "NMTMSGlobalKeepAwakeFlag" 73 "Reserved" 74 "Reserved" 75 "Reserved" 76 "Reserved" 77 "Reserved" 78 "Reserved" 79 "Reserved" 80 "Reserved" 81 "Reserved" 82 "Reserved" 83 "Reserved" 84 "Reserved" 85 "Reserved" 86 "Reserved" 87 "Reserved" 88 "Reserved" 89 "NMWCCDownloadRequest_RT1" 90 "CAN7_DiagMSG_ID ！" 91 "CAN7_DiagMSG_ID" 92 "Reserved" 93 "Reserved" 94 "Reserved" 95 "Reserved" 96 "Reserved" 97 "Reserved" 98 "Reserved" 99 "Reserved" 100 "NMATWSKeepAwakeFlag" 101 "NMExteriorLightKeepAwakeFlag" 102 "NMLockingKeepAwakeFlag" 103 "NMPWLKeepAwakeFlag" 104 "NMSunRoofKeepAwakeFlag" 105 "NMPLGKeepAwakeFlag" 106 "NMPowerOperatedDoorKeepAwakeFlag" 107 "MR_NMMirrorKeepAwakeFlag" 108 "NMSeatControlKeepAwakeFlag" 109 "NMHVACKeepAwakeFlag" 110 "NMHVACRLSLinAwakeFlag" 111 "NMAQCKeepAwakeFlag" 112 "NMTPMSKeepAwakeFlag" 113 "ILC_NMKeepAwakeFlag" 114 "NMESMKeepAwakeFlag" 115 "NMKAEKeepAwakeFlag" 116 "NMVRMPNCCharingKeepAwakeFlag" 140 "NMWCCDownloadReques_RT2"  ;
VAL_ 1359 CCU_PNCInformation0 0 "No request" 1 "Request" 0 "No request" 1 "Request" 0 "No request" 1 "Request" 0 "No request" 1 "Request" 1 "Request" 0 "No request" 1 "Request" 0 "No request" 1 "Request"  ;
VAL_ 1359 CCU_PNCInformation1 0 "No request" 1 "Request" 0 "No request" 1 "Request"  ;
VAL_ 352 BCS_VehSpdVD 0 "Not Valid" 1 "Valid"  ;
VAL_ 884 LCK_FrontLeftDoorHandlePosition 0 "FullyClosed" 100 "FullyOpened" 254 "Uninitialized" 255 "Unknown"  ;
VAL_ 884 LCK_FrontLeftDoorLockAction 0 "NoAction" 1 "Locking" 2 "Unlocking" 3 "Breaking"  ;
VAL_ 884 LCK_FrontLeftDoorHandleAction 0 "NoAction" 1 "Closing" 2 "Opening"  ;
VAL_ 884 LCK_FrontLeftPowerDoorAction 0 "NoAction" 1 "Cinching" 2 "Releasing"  ;
VAL_ 884 LCK_FrontRightDoorHandlePosition 0 "FullyClosed" 100 "FullyOpened" 254 "Uninitialized" 255 "Unknown"  ;
VAL_ 884 LCK_FrontRightDoorLockAction 0 "NoAction" 1 "Locking" 2 "Unlocking" 3 "Breaking"  ;
VAL_ 884 LCK_FrontRightDoorHandleAction 0 "NoAction" 1 "Closing" 2 "Opening"  ;
VAL_ 884 LCK_FrontRightPowerDoorAction 0 "NoAction" 1 "Cinching" 2 "Releasing"  ;
VAL_ 884 IPDS_BAT1PowerSt 0 "Not Active" 1 "Active"  ;
VAL_ 884 IPDS_BAT2PowerSt 0 "Not Active" 1 "Active"  ;
VAL_ 884 IPDS_DCDC2PowerSt 0 "Not Active" 1 "Active"  ;
VAL_ 884 IPDS_GridIsoPowerSt 0 "Not Active" 1 "Active"  ;
VAL_ 514 SRS_CrashOutputSt 0 "No crash,"  ;
VAL_ 514 BMS_HVBattSt 14 "Service mode;" 10 "10 Emergency Disconnect;" 9 "9 AC Charge;" 8 "8 DC Charge;" 6 "6 Disconnect;" 5 "5 Wait;" 4 "4 Online;" 3 "3 Connect;" 2 "2 Precharge;" 1 "1 Offline;" 0 "0 Undefined;"  ;
VAL_ 909 LCK_FrontLeftDoorLockSt 0 "Locked" 1 "Unlocked"  ;
VAL_ 909 LCK_FrontRightDoorLockSt 0 "Locked" 1 "Unlocked"  ;
VAL_ 909 LCK_RearLeftDoorLockSt 0 "Locked" 1 "Unlocked"  ;
VAL_ 909 LCK_RearRightDoorLockSt 0 "Locked" 1 "Unlocked"  ;
VAL_ 909 LCK_RearLeftChildSaftyLockSt 0 "Locked" 1 "Unlocked"  ;
VAL_ 909 LCK_RearRightChildSaftyLockSt 0 "Locked" 1 "Unlocked"  ;
VAL_ 909 BMS_ThermalRunawayErr 1 "Thermal runaway alarm;" 0 "Normal;"  ;
VAL_ 909 IPS_DCDCModeSt 7 "Failure;" 3 "Active - Buck Mode;" 2 "Connected (HV is active);" 1 "Disconnected;" 0 "Init;"  ;
VAL_ 792 LCK_RearLeftDoorLockAction 0 "NoAction" 1 "Locking" 2 "Unlocking" 3 "Breaking"  ;
VAL_ 792 LCK_RearLeftDoorHandleAction 0 "NoAction" 1 "Closing" 2 "Opening"  ;
VAL_ 792 LCK_RearLeftPowerDoorAction 0 "NoAction" 1 "Cinching" 2 "Releasing"  ;
VAL_ 792 LCK_RearLeftDoorHandlePosition 0 "FullyClosed" 100 "FullyOpened" 254 "Uninitialized" 255 "Unknown"  ;
VAL_ 792 LCK_RearLeftChildSaftyLockAction 0 "NoAction" 1 "Locking" 2 "Unlocking" 3 "Breaking"  ;
VAL_ 792 LCK_RearRightDoorHandlePosition 0 "FullyClosed" 100 "FullyOpened" 254 "Uninitialized" 255 "Unknown"  ;
VAL_ 792 LCK_RearRightDoorHandleAction 0 "NoAction" 1 "Closing" 2 "Opening"  ;
VAL_ 792 LCK_RearRightPowerDoorAction 0 "NoAction" 1 "Cinching" 2 "Releasing"  ;
VAL_ 792 LCK_RearRightChildSaftyLockAction 0 "NoAction" 1 "Locking" 2 "Unlocking" 3 "Breaking"  ;
VAL_ 792 LCK_RearRightDoorLockAction 0 "NoAction" 1 "Locking" 2 "Unlocking" 3 "Breaking"  ;
VAL_ 1395 ZCUT_NMCBV 0 "Node has not woken up the    network(passive wakeup);" 1 "Node has woken up the network(active wakeup)" 0 "NM PDU contains no Partial Network request information" 1 "NM PDU contains Partial Network request information"  ;
VAL_ 1395 ZCUT_NMWakeupOrigin 0 "Reserved" 254 "Diag_message" 241 "CAN01_NM Message wakeup" 242 "CAN02_NM Message wakeup" 243 "CAN03_NM Message wakeup" 244 "CAN04_NM Message wakeup" 245 "CAN05_NM Message wakeup" 4 "EPB sw" 80 "Fill Cap B State" 81 "RL Door Ajar State" 82 "RR Door Ajar State" 83 "RL Door Lock State" 84 "RR Door Lock State" 85 "RL Door Open State" 86 "RL Power Release Switch" 87 "RL Door Outside Switch" 88 "RR Door Open State" 89 "RR Power Release Switch" 90 "RR Door Outside Switch" 91 "Trunk Ajar State / Tail Door Latch Ajar Switch" 92 "Tail Door Latch Half Switch" 93 "Tail Door Latch Neutral Switch" 94 "Tail Door  pawl switch" 95 "PLG Switch" 99 "External Switch, Filler Cap" 100 "Fill Cap A State" 189 "EBS Low Battery Wakeup" 194 "Lift Gate Stay Assy 1 HS 1" 195 "Lift Gate Stay Assy 1 HS 2" 203 "EPB（SSM）"  ;
VAL_ 1395 ZCUT_PNCInformation0 0 "No request" 1 "Request" 0 "No request" 1 "Request" 0 "No request" 1 "Request" 0 "No request" 1 "Request" 1 "Request" 0 "No request" 1 "Request" 0 "No request" 1 "Request"  ;
VAL_ 1395 ZCUT_PNCInformation1 0 "No request" 1 "Request" 0 "No request" 1 "Request"  ;
VAL_ 1449 LBMS_NMCBV 0 "Node has not woken up the    network(passive wakeup);" 1 "Node has woken up the network(active wakeup)" 0 "NM PDU contains no Partial Network request information" 1 "NM PDU contains Partial Network request information"  ;
VAL_ 1449 LBMS_NMWakeupOrigin 1 "" 2 "Lock Power of  Transport" 3 "Lock Power of  Level1" 4 "Lock Power of  Level2" 5 "Automatic Charge"  ;
VAL_ 1449 LBMS_PNCInformation0 0 "No request" 1 "Request" 0 "No request" 1 "Request" 0 "No request" 1 "Request" 0 "No request" 1 "Request" 1 "Request" 0 "No request" 1 "Request" 0 "No request" 1 "Request"  ;
VAL_ 1449 LBMS_PNCInformation1 0 "No request" 1 "Request" 0 "No request" 1 "Request"  ;
VAL_ 793 LBMS_UnsfLoadPackVoltVD 0 "Invalid" 1 "Valid"  ;
VAL_ 793 LBMS_SfLoadPackVoltVD 0 "Invalid" 1 "Valid"  ;
VAL_ 793 LBMS_UnsfLoadCurrentRange 0 "Unsafe Load current range (0A,0.3A]" 1 "Unsafe Load current range (0.3A,1500A]" 2 "Unsafe Load current range (-1500A,0A]" 3 "Reserved"  ;
VAL_ 793 LBMS_SfLoadCurrentRange 0 "Safe Load current range (0A,0.3A]" 1 "Safe Load current range (0.3A,1500A]" 2 "Safe Load current range (-1500A,0A]" 3 "Reserved"  ;
VAL_ 793 LBMS_SOFVD 0 "Invalid" 1 "Valid"  ;
VAL_ 793 LBMS_SOFEN 0 "Keep to the side parking False,Original lane parking False" 1 "Keep to the side parking True,Original lane parking False" 2 "Keep to the side parking False,Original lane parking True" 3 "Keep to the side parking True,Original lane parking True"  ;
VAL_ 793 LBMS_SOFInhibitSt 0 "None" 1 "LBMS_FaultSt_CellOV" 2 "LBMS_FaultSt_CellLV" 3 "LBMS_FaultSt_BatOV" 4 "LBMS_FaultSt_BatLV" 5 "LBMS_FaultSt_ChgOC" 6 "LBMS_FaultSt_DsgOC" 7 "LBMS_FaultSt_OTB" 8 "LBMS_FaultSt_LT" 9 "LBMS_FaultSt_OTMO" 10 "LBMS_FaultSt_OTMC" 11 "LBMS_FaultSt_OTS" 12 "LBMS_ThermalRunawayErr" 13 "LBMS_FaultSt_Hard_CellVolCol" 14 "LBMS_FaultSt_Hard_CelltotVolCol" 15 "LBMS_FaultSt_Hard_PackVolCol" 16 "LBMS_FaultSt_Hard_ComSoVoltCol" 17 "LBMS_FaultSt_Hard_TempColBat" 18 "LBMS_FaultSt_Hard_TemColMOS" 19 "LBMS_FaultSt_Hard_TemColMCU" 20 "LBMS_FaultSt_Hard_Hard_Shunt" 21 "LBMS_FaultSt_Hard_ChgMos Stuck Open" 22 "LBMS_FaultSt_Hard_DgsMos Stuck Open" 23 "LBMS_FaultSt_Hard_ChgMos Stuck Close" 24 "LBMS_FaultSt_Hard_DgsMos Stuck Close" 25 "LBMS_FaultSt_Hard_ChgMOSDriverErr" 26 "LBMS_FaultSt_Hard_DsgMOSDriverErr" 27 "AFE Fault" 28 "MCU Fault" 29 "SBC Fault" 30 "WireHarnConSt" 31 "SOC Low" 32 "SOH Low" 33 "Pack Output Line Conect Reverse" 34 "Reserved" 35 "Reserved" 36 "Reserved" 37 "Reserved" 38 "Reserved" 39 "Reserved" 40 "Reserved" 41 "Reserved" 42 "Reserved" 43 "Reserved" 44 "Reserved" 45 "Reserved" 46 "Reserved" 47 "Reserved" 48 "Reserved" 49 "Reserved" 50 "Reserved" 51 "Reserved" 52 "Reserved" 53 "Reserved" 54 "Reserved" 55 "Reserved" 56 "Reserved" 57 "Reserved" 58 "Reserved" 59 "Reserved" 60 "Reserved" 61 "Reserved" 62 "Reserved" 63 "Reserved" 64 "Reserved" 65 "Reserved" 66 "Reserved" 67 "Reserved" 68 "Reserved" 69 "Reserved" 70 "Reserved" 71 "Reserved" 72 "Reserved" 73 "Reserved" 74 "Reserved" 75 "Reserved" 76 "Reserved" 77 "Reserved" 78 "Reserved" 79 "Reserved" 80 "Reserved" 81 "Reserved" 82 "Reserved" 83 "Reserved" 84 "Reserved" 85 "Reserved" 86 "Reserved" 87 "Reserved" 88 "Reserved" 89 "Reserved" 90 "Reserved" 91 "Reserved" 92 "Reserved" 93 "Reserved" 94 "Reserved" 95 "Reserved" 96 "Reserved" 97 "Reserved" 98 "Reserved" 99 "Reserved" 100 "Reserved" 101 "Reserved" 102 "Reserved" 103 "Reserved" 104 "Reserved" 105 "Reserved" 106 "Reserved" 107 "Reserved" 108 "Reserved" 109 "Reserved" 110 "Reserved" 111 "Reserved" 112 "Reserved" 113 "Reserved" 114 "Reserved" 115 "Reserved" 116 "Reserved" 117 "Reserved" 118 "Reserved" 119 "Reserved" 120 "Reserved" 121 "Reserved" 122 "Reserved" 123 "Reserved" 124 "Reserved" 125 "Reserved" 126 "Reserved" 127 "Reserved" 128 "Reserved" 129 "Reserved" 130 "Reserved" 131 "Reserved" 132 "Reserved" 133 "Reserved" 134 "Reserved" 135 "Reserved" 136 "Reserved" 137 "Reserved" 138 "Reserved" 139 "Reserved" 140 "Reserved" 141 "Reserved" 142 "Reserved" 143 "Reserved" 144 "Reserved" 145 "Reserved" 146 "Reserved" 147 "Reserved" 148 "Reserved" 149 "Reserved" 150 "Reserved" 151 "Reserved" 152 "Reserved" 153 "Reserved" 154 "Reserved" 155 "Reserved" 156 "Reserved" 157 "Reserved" 158 "Reserved" 159 "Reserved" 160 "Reserved" 161 "Reserved" 162 "Reserved" 163 "Reserved" 164 "Reserved" 165 "Reserved" 166 "Reserved" 167 "Reserved" 168 "Reserved" 169 "Reserved" 170 "Reserved" 171 "Reserved" 172 "Reserved" 173 "Reserved" 174 "Reserved" 175 "Reserved" 176 "Reserved" 177 "Reserved" 178 "Reserved" 179 "Reserved" 180 "Reserved" 181 "Reserved" 182 "Reserved" 183 "Reserved" 184 "Reserved" 185 "Reserved" 186 "Reserved" 187 "Reserved" 188 "Reserved" 189 "Reserved" 190 "Reserved" 191 "Reserved" 192 "Reserved" 193 "Reserved" 194 "Reserved" 195 "Reserved" 196 "Reserved" 197 "Reserved" 198 "Reserved" 199 "Reserved" 200 "Reserved" 201 "Reserved" 202 "Reserved" 203 "Reserved" 204 "Reserved" 205 "Reserved" 206 "Reserved" 207 "Reserved" 208 "Reserved" 209 "Reserved" 210 "Reserved" 211 "Reserved" 212 "Reserved" 213 "Reserved" 214 "Reserved" 215 "Reserved" 216 "Reserved" 217 "Reserved" 218 "Reserved" 219 "Reserved" 220 "Reserved" 221 "Reserved" 222 "Reserved" 223 "Reserved" 224 "Reserved" 225 "Reserved" 226 "Reserved" 227 "Reserved" 228 "Reserved" 229 "Reserved" 230 "Reserved" 231 "Reserved" 232 "Reserved" 233 "Reserved" 234 "Reserved" 235 "Reserved" 236 "Reserved" 237 "Reserved" 238 "Reserved" 239 "Reserved" 240 "Reserved" 241 "Reserved" 242 "Reserved" 243 "Reserved" 244 "Reserved" 245 "Reserved" 246 "Reserved" 247 "Reserved" 248 "Reserved" 249 "Reserved" 250 "Reserved" 251 "Reserved" 252 "Reserved" 253 "Reserved" 254 "Reserved" 255 "Reserved"  ;
VAL_ 793 LBMS_ChargReq 0 "No Charge Request" 1 "Low SOC Charge Request" 2 "Low Volt Charge Request"  ;
VAL_ 793 LBMS_SOCVD 0 "Invalid" 1 "Valid"  ;
VAL_ 793 LBMS_PackVoltVD 0 "Invalid" 1 "Valid"  ;
VAL_ 793 LBMS_AlrmDispSt 0 "No alarm" 1 "fault" 2 "Low power to lock" 3 "Thermal Out of Control" 4 "Low power to EOL" 5 "Low power to lock of Transport Mode" 6 "SOH low" 7 "SOF low"  ;
VAL_ 793 LBMS_CurrentRange 0 "current range (0A,0.3A]" 1 "current range (0.3A,1500A]" 2 "current range (-1500A,0A]" 3 "Reserved"  ;
VAL_ 793 LBMS_RefChargReq 0 "No Refesh Charge Request" 1 "Refesh  Charge Request"  ;
VAL_ 793 LBMS_ThermalRunawayErr 0 "No Error" 1 "Process Error" 2 "Mauture Error" 3 "Reserved"  ;
VAL_ 793 LBMS_IPDS_BAT1PowerReq 0 "Open" 1 "Close"  ;
VAL_ 793 LBMS_IPDS_BAT2PowerReq 0 "Open" 1 "Close"  ;
VAL_ 793 LBMS_IPDS_GridlsoPowerReq 0 "Open" 1 "Close"  ;
VAL_ 793 LBMS_FaultSt_SOCLow 0 "No Fault" 1 "LBMS_Faultx_SOCLow_Level1" 2 "LBMS_Faultx_SOCLow_Level2" 3 "LBMS_Faultx_SOCLow_Level3"  ;
VAL_ 793 LBMS_DisconnectSt 0 "Init" 1 "Disconnect" 2 "Reject disconnect"  ;
VAL_ 973 LBMS_SOHVD 0 "Invalid" 1 "Valid"  ;
VAL_ 973 LBMS_CellTotVoltVD 0 "Invalid" 1 "Valid"  ;
VAL_ 973 LBMS_ChargReqEn 0 "Disable" 1 "Enable"  ;
VAL_ 973 LBMS_WorkSt 0 "Init" 1 "Discharge" 2 "Voltage Regulation Charge" 3 "Full Charge Mode" 4 "Float Charge Mode" 5 "DCDC Charge" 6 "FAULT" 7 "Blind Charge"  ;
VAL_ 973 LBMS_MOSSt 0 "All Opened" 1 "All Closed" 2 "Charge Mos Closed&Dischrge Mos Opened" 3 "Charge Mos Opened&Discharge Mos Closed"  ;
VAL_ 973 LBMS_WakeupSource 0 "No wakeup" 1 "wakeup by NM" 2 "wakeup by OV" 3 "wakeup by RTC" 4 "wakeup by OT" 5 "wakeup by OC" 6 "wakeup by Hardwire" 7 "wakeup by short-circuit protection" 8 "wakeup by Bonding power"  ;
VAL_ 973 LBMS_HardWireSt 0 "No wakeup" 1 "Wakeup" 2 "Out of nimbleness" 3 "Reserved"  ;
VAL_ 973 LBMS_WireHarnConSt 0 "All Normal" 1 "All Fault" 2 "Unsafe Load Normal & Safe Load Fault" 2 "Unsafe Load Fault & Safe Load Normal"  ;
VAL_ 973 LBMS_SOCCaliMode 0 "No Calibration" 1 "Full Charge Calibration" 2 "Full Disharge Calibration" 3 "OCV Static Calibration" 4 "OCV Dynamic Calibration" 5 "SOC Out Of Range Calibration" 6 "NVM Invalid Calibration" 7 "Reserved"  ;
VAL_ 973 LBMS_ChrgCurrentLimt1VD 0 "Invalid" 1 "Valid"  ;
VAL_ 973 LBMS_ChrgCurrentLimt2VD 0 "Invalid" 1 "Valid"  ;
VAL_ 973 LBMS_Cell1VoltVD 0 "Invalid" 1 "Valid"  ;
VAL_ 973 LBMS_Cell2VoltVD 0 "Invalid" 1 "Valid"  ;
VAL_ 973 LBMS_Cell3VoltVD 0 "Invalid" 1 "Valid"  ;
VAL_ 973 LBMS_Cell4VoltVD 0 "Invalid" 1 "Valid"  ;
VAL_ 973 LBMS_Cell1BalanceSt 0 "Not  Work" 1 "Work" 2 "Consistency Fault" 3 "Balance Circuit Open Fault"  ;
VAL_ 973 LBMS_Cell2BalanceSt 0 "Not  Work" 1 "Work" 2 "Consistency Fault" 3 "Balance Circuit Open Fault"  ;
VAL_ 973 LBMS_Cell3BalanceSt 0 "Not  Work" 1 "Work" 2 "Consistency Fault" 3 "Balance Circuit Open Fault"  ;
VAL_ 973 LBMS_Cell4BalanceSt 0 "Not  Work" 1 "Work" 2 "Consistency Fault" 3 "Balance Circuit Open Fault"  ;
VAL_ 973 LBMS_CellTemp1VD 0 "Invalid" 1 "Valid"  ;
VAL_ 973 LBMS_CellTemp2VD 0 "Invalid" 1 "Valid"  ;
VAL_ 973 LBMS_CellTemp3VD 0 "Invalid" 1 "Valid"  ;
VAL_ 973 LBMS_McuTempVD 0 "Invalid" 1 "Valid"  ;
VAL_ 973 LBMS_MosTemp1VD 0 "Invalid" 1 "Valid"  ;
VAL_ 973 LBMS_CurrentVD 0 "Invalid" 1 "Valid"  ;
VAL_ 973 LBMS_MosTemp2VD 0 "Invalid" 1 "Valid"  ;
VAL_ 973 LBMS_ShuntTempVD 0 "Invalid" 1 "Valid"  ;
VAL_ 973 LBMS_BalanTemp1VD 0 "Invalid" 1 "Valid"  ;
VAL_ 973 LBMS_BalanTemp2VD 0 "Invalid" 1 "Valid"  ;
VAL_ 973 LBMS_FaultSt_OVB 0 "No Fault" 1 "LBMS_FaultSt_BatOV_Level1" 2 "LBMS_FaultSt_BatOV_Level2" 3 "LBMS_FaultSt_BatOV_Level3"  ;
VAL_ 973 LBMS_FaultSt_OVC 0 "No Fault" 1 "LBMS_FaultSt_CellOV_Extremity" 2 "LBMS_FaultSt_CellOV_Level1" 3 "LBMS_FaultSt_CellOV_Level2" 4 "LBMS_FaultSt_CellOV_Level3"  ;
VAL_ 973 LBMS_FaultSt_CVD 0 "No Fault" 1 "LBMS_FaultSt_CellVolDif"  ;
VAL_ 973 LBMS_FaultSt_LVB 0 "No Fault" 1 "LBMS_FaultSt_BatLV_Extremity" 2 "LBMS_FaultSt_BatLV_Level1" 3 "LBMS_FaultSt_BatLV_Level2" 4 "Occurred LBMS_FaultSt_BatLV_Extremity" 5 "Occurred LBMS_FaultSt_BatLV_Level1"  ;
VAL_ 973 LBMS_FaultSt_LVC 0 "No Fault" 1 "LBMS_FaultSt_CellLV_Extremity" 2 "LBMS_FaultSt_CellLV_Level1" 3 "LBMS_FaultSt_CellLV_Level2" 4 "Occurred LBMS_FaultSt_CellLV_Extremity" 5 "Occurred LBMS_FaultSt_CellLV_Level1"  ;
VAL_ 973 LBMS_FaultSt_OTB 0 "No Fault" 1 "LBMS_FaultSt_BatOT_Level1" 2 "LBMS_FaultSt_BatOT_Level2" 3 "LBMS_FaultSt_BatOT_Level3" 4 "Occurred LBMS_FaultSt_BatOT_Level1" 5 "Occurred LBMS_FaultSt_BatOT_Level2"  ;
VAL_ 973 LBMS_FaultSt_OTMC 0 "No Fault" 1 "LBMS_FaultSt_MCUOT_Level1" 2 "LBMS_FaultSt_MCUOT_Level2" 3 "Occurred LBMS_FaultSt_MCUOT_Level1"  ;
VAL_ 973 LBMS_FaultSt_OTMO 0 "No Fault" 1 "LBMS_FaultSt_MOSOT_Level1" 2 "LBMS_FaultSt_MOSOT_Level2" 3 "Occurred LBMS_FaultSt_MOSOT_Level1"  ;
VAL_ 973 LBMS_FaultSt_OTS 0 "No Fault" 1 "LBMS_FaultSt_ShuntOT_Level1" 2 "LBMS_FaultSt_ShuntOT_Level2" 3 "Occurred LBMS_FaultSt_ShuntOT_Level1"  ;
VAL_ 973 LBMS_FaultSt_OTCB 0 "No Fault" 1 "LBMS_FaultSt_CellBalanceOT_Level1"  ;
VAL_ 973 LBMS_FaultSt_CTD 0 "No Fault" 1 "LBMS_FaultSt_CellTemDif"  ;
VAL_ 973 LBMS_FaultSt_LT 0 "No Fault" 1 "LBMS_FaultSt_CellLT"  ;
VAL_ 973 LBMS_FaultSt_ChgOC 0 "No Fault" 1 "LBMS_FaultSt_ChgOC_Extremity" 2 "LBMS_FaultSt_ChgOC_Level1" 3 "LBMS_FaultSt_ChgOC_Level2"  ;
VAL_ 973 LBMS_FaultSt_DsgOC 0 "No Fault" 1 "LBMS_FaultSt_DsgOC_ShortCircuit" 2 "LBMS_FaultSt_DsgOC_Level1" 3 "LBMS_FaultSt_DsgOC_Level2" 4 "Occurred LBMS_FaultSt_DsgOC_ShortCircuit" 5 "Occurred LBMS_FaultSt_DsgOC_Level1" 6 "Occurred LBMS_FaultSt_DsgOC_Level2" 7 "Reserved"  ;
VAL_ 973 LBMS_FaultSt_Hard_CellVolCol 0 "No Fault" 1 "LBMS_FaultSt_Hard_CellVolColOpen"  ;
VAL_ 973 LBMS_FaultSt_Hard_TempColBat 0 "No Fault" 1 "LBMS_FaultSt_Hard_BatTempColShort" 2 "LBMS_FaultSt_Hard_BatTempColOpen" 3 "Reserved"  ;
VAL_ 973 LBMS_FaultSt_Hard_TemColMOS 0 "No Fault" 1 "LBMS_FaultSt_Hard_MOSTemSensor;" 2 "LBMS_FaultSt_Hard_MOSTemColShort" 3 "LBMS_FaultSt_Hard_MOSTemColOpen"  ;
VAL_ 973 LBMS_FaultSt_Hard_TemColMCU 0 "No Fault" 1 "LBMS_FaultSt_Hard_MCUTemColShort" 2 "LBMS_FaultSt_Hard_MCUTemColOpen" 3 "Reserved"  ;
VAL_ 973 LBMS_FaultSt_Hard_Shunt 0 "No Fault" 1 "LBMS_FaultSt_Hard_ShuntOpen"  ;
VAL_ 973 LBMS_FaultSt_Hard_ChgMOS 0 "No Fault" 1 "LBMS_FaultSt_Hard_ChgMOSAdhesion" 2 "LBMS_FaultSt_Hard_ChgMOSOpen" 3 "LBMS_FaultSt_Hard_ChgMOSDriverErr"  ;
VAL_ 973 LBMS_FaultSt_Hard_DsgMOS 0 "No Fault" 1 "LBMS_FaultSt_Hard_DsgMOSAdhesion" 2 "LBMS_FaultSt_Hard_DsgMOSOpen" 3 "LBMS_FaultSt_Hard_DsgMOSDriverErr" 4 "Occurred LBMS_FaultSt_Hard_DsgMOSOpen"  ;
VAL_ 973 LBMS_FaultSt_Hard_AFE 0 "No Fault" 1 "LBMS_FaultSt_Hard_AFEFaultPinErr" 2 "LBMS_FaultSt_Hard_AFEResetPinErr" 3 "LBMS_FaultSt_Hard_AFEBalanceErr" 4 "LBMS_FaultSt_Hard_AFEVolColErr" 5 "LBMS_FaultSt_Hard_AFECutColErr" 6 "LBMS_FaultSt_Hard_AFETemColErr" 7 "LBMS_FaultSt_Hard_AFEOtherHardErr"  ;
VAL_ 973 LBMS_FaultSt_Hard_MCU 0 "No Fault" 1 "LBMS_FaultSt_Hard_MCUSPIErr" 2 "LBMS_FaultSt_Hard_MCUPowerSupErr" 3 "LBMS_FaultSt_Hard_MCUTimeErr" 4 "LBMS_FaultSt_Hard_MCURegisterErr" 5 "LBMS_FaultSt_Hard_MCUMemoryErr" 6 "LBMS_FaultSt_Hard_MCUPeriErr" 7 "LBMS_FaultSt_Hard_MCUKeyModulesErr"  ;
VAL_ 973 LBMS_FaultSt_Hard_SBC 0 "No Fault" 1 "LBMS_FaultSt_Hard_SBCFS0BErr" 2 "LBMS_FaultSt_Hard_SBCDormantCfgErr" 3 "LBMS_FaultSt_Hard_SBCExternalErr"  ;
VAL_ 973 LBMS_FaultSt_Hard_DCDC 0 "No Fault" 1 "LBMS_FaultSt_Hard_DCDCLimitCutErr"  ;
VAL_ 973 LBMS_FaultSt_CANBusOff 0 "No Fault" 1 "fault"  ;
VAL_ 973 LBMS_FaultSt_CANTimeOut 0 "No Fault" 1 "fault"  ;
VAL_ 973 LBMS_FaultSt_CANCrcErr 0 "No Fault" 1 "fault"  ;
VAL_ 973 LBMS_HisLockPackSt 0 "Unlock" 1 "Lock"  ;
VAL_ 973 LBMS_CurentLockPackSt 0 "Unlock" 1 "Lock"  ;
VAL_ 973 LBMS_ExternalCharging 0 "not powered externally" 1 "powered externally"  ;
VAL_ 973 LBMS_Supplier 0 "default" 1 "A" 2 "B" 3 "C" 4 "D"  ;
VAL_ 973 LBMS_UpackRvsVoltVD 0 "Invalid" 1 "Valid"  ;
